VERSION "10.6"

NS_ :

BS_:

BU_: OBD XGW_Diag

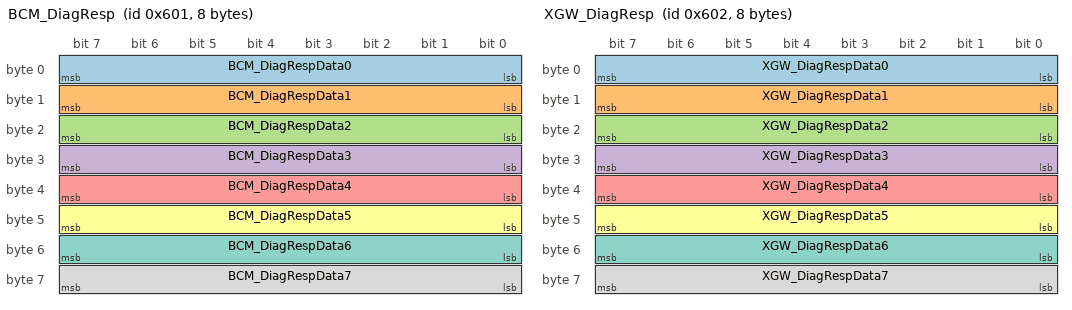
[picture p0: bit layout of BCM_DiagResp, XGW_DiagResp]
BO_ 1537 BCM_DiagResp: 8 XGW_Diag
  SG_ BCM_DiagRespData0 : 7|8@0+ (1,0) [0|255] "" OBD
  SG_ BCM_DiagRespData1 : 15|8@0+ (1,0) [0|255] "-" OBD
  SG_ BCM_DiagRespData2 : 23|8@0+ (1,0) [0|255] "" OBD
  SG_ BCM_DiagRespData3 : 31|8@0+ (1,0) [0|255] "" OBD
  SG_ BCM_DiagRespData4 : 39|8@0+ (1,0) [0|255] "" OBD
  SG_ BCM_DiagRespData5 : 47|8@0+ (1,0) [0|255] "" OBD
  SG_ BCM_DiagRespData6 : 55|8@0+ (1,0) [0|255] "-" OBD
  SG_ BCM_DiagRespData7 : 63|8@0+ (1,0) [0|255] "" OBD

BO_ 1538 XGW_DiagResp: 8 XGW_Diag
  SG_ XGW_DiagRespData0 : 7|8@0+ (1,0) [0|255] "-" OBD
  SG_ XGW_DiagRespData1 : 15|8@0+ (1,0) [0|255] "-" OBD
  SG_ XGW_DiagRespData2 : 23|8@0+ (1,0) [0|255] "-" OBD
  SG_ XGW_DiagRespData3 : 31|8@0+ (1,0) [0|255] "" OBD
  SG_ XGW_DiagRespData4 : 39|8@0+ (1,0) [0|255] "" OBD
  SG_ XGW_DiagRespData5 : 47|8@0+ (1,0) [0|255] "-" OBD
  SG_ XGW_DiagRespData6 : 55|8@0+ (1,0) [0|255] "" OBD
  SG_ XGW_DiagRespData7 : 63|8@0+ (1,0) [0|255] "-" OBD

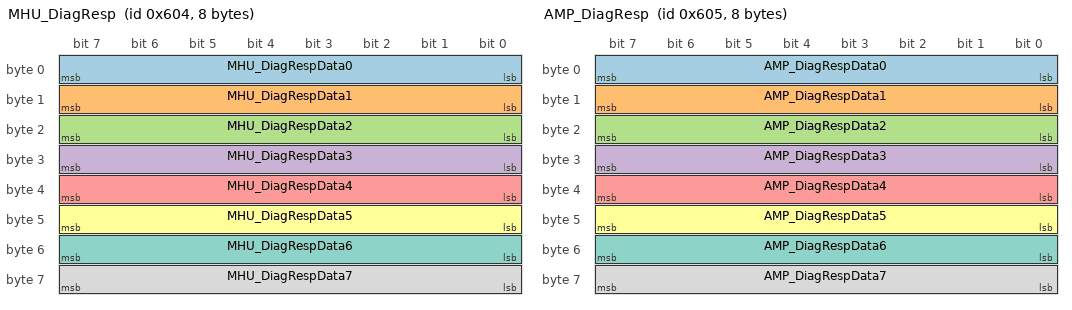
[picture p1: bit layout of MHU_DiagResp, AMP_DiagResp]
BO_ 1540 MHU_DiagResp: 8 XGW_Diag
  SG_ MHU_DiagRespData0 : 7|8@0+ (1,0) [0|255] "-" OBD
  SG_ MHU_DiagRespData1 : 15|8@0+ (1,0) [0|255] "-" OBD
  SG_ MHU_DiagRespData2 : 23|8@0+ (1,0) [0|255] "" OBD
  SG_ MHU_DiagRespData3 : 31|8@0+ (1,0) [0|255] "-" OBD
  SG_ MHU_DiagRespData4 : 39|8@0+ (1,0) [0|255] "-" OBD
  SG_ MHU_DiagRespData5 : 47|8@0+ (1,0) [0|255] "-" OBD
  SG_ MHU_DiagRespData6 : 55|8@0+ (1,0) [0|255] "-" OBD
  SG_ MHU_DiagRespData7 : 63|8@0+ (1,0) [0|255] "" OBD

BO_ 1541 AMP_DiagResp: 8 XGW_Diag
  SG_ AMP_DiagRespData0 : 7|8@0+ (1,0) [0|255] "-" OBD
  SG_ AMP_DiagRespData1 : 15|8@0+ (1,0) [0|255] "-" OBD
  SG_ AMP_DiagRespData2 : 23|8@0+ (1,0) [0|255] "-" OBD
  SG_ AMP_DiagRespData3 : 31|8@0+ (1,0) [0|255] "" OBD
  SG_ AMP_DiagRespData4 : 39|8@0+ (1,0) [0|255] "-" OBD
  SG_ AMP_DiagRespData5 : 47|8@0+ (1,0) [0|255] "" OBD
  SG_ AMP_DiagRespData6 : 55|8@0+ (1,0) [0|255] "" OBD
  SG_ AMP_DiagRespData7 : 63|8@0+ (1,0) [0|255] "-" OBD

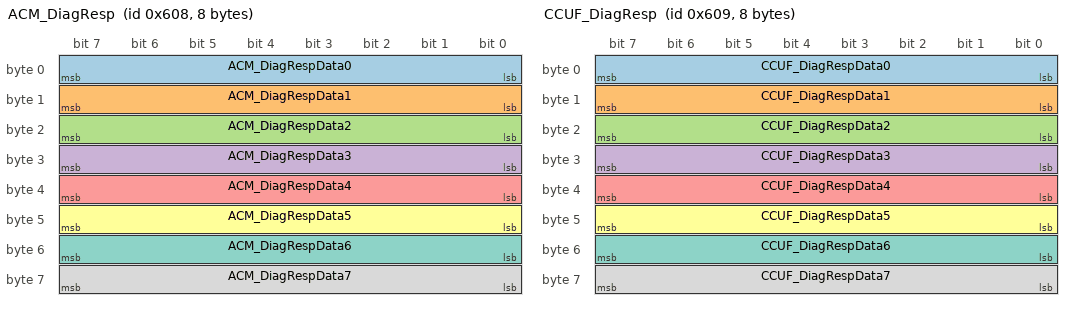
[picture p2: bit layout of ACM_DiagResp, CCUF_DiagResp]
BO_ 1544 ACM_DiagResp: 8 XGW_Diag
  SG_ ACM_DiagRespData0 : 7|8@0+ (1,0) [0|255] "" OBD
  SG_ ACM_DiagRespData1 : 15|8@0+ (1,0) [0|255] "-" OBD
  SG_ ACM_DiagRespData2 : 23|8@0+ (1,0) [0|255] "" OBD
  SG_ ACM_DiagRespData3 : 31|8@0+ (1,0) [0|255] "-" OBD
  SG_ ACM_DiagRespData4 : 39|8@0+ (1,0) [0|255] "" OBD
  SG_ ACM_DiagRespData5 : 47|8@0+ (1,0) [0|255] "-" OBD
  SG_ ACM_DiagRespData6 : 55|8@0+ (1,0) [0|255] "" OBD
  SG_ ACM_DiagRespData7 : 63|8@0+ (1,0) [0|255] "-" OBD

BO_ 1545 CCUF_DiagResp: 8 XGW_Diag
  SG_ CCUF_DiagRespData0 : 7|8@0+ (1,0) [0|255] "" OBD
  SG_ CCUF_DiagRespData1 : 15|8@0+ (1,0) [0|255] "-" OBD
  SG_ CCUF_DiagRespData2 : 23|8@0+ (1,0) [0|255] "-" OBD
  SG_ CCUF_DiagRespData3 : 31|8@0+ (1,0) [0|255] "" OBD
  SG_ CCUF_DiagRespData4 : 39|8@0+ (1,0) [0|255] "" OBD
  SG_ CCUF_DiagRespData5 : 47|8@0+ (1,0) [0|255] "-" OBD
  SG_ CCUF_DiagRespData6 : 55|8@0+ (1,0) [0|255] "-" OBD
  SG_ CCUF_DiagRespData7 : 63|8@0+ (1,0) [0|255] "" OBD

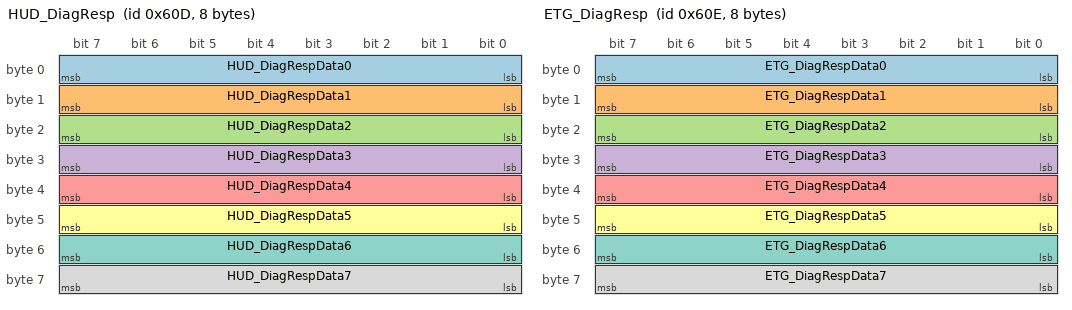
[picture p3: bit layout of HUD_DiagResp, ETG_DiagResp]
BO_ 1549 HUD_DiagResp: 8 XGW_Diag
  SG_ HUD_DiagRespData0 : 7|8@0+ (1,0) [0|255] "" OBD
  SG_ HUD_DiagRespData1 : 15|8@0+ (1,0) [0|255] "" OBD
  SG_ HUD_DiagRespData2 : 23|8@0+ (1,0) [0|255] "" OBD
  SG_ HUD_DiagRespData3 : 31|8@0+ (1,0) [0|255] "" OBD
  SG_ HUD_DiagRespData4 : 39|8@0+ (1,0) [0|255] "-" OBD
  SG_ HUD_DiagRespData5 : 47|8@0+ (1,0) [0|255] "" OBD
  SG_ HUD_DiagRespData6 : 55|8@0+ (1,0) [0|255] "-" OBD
  SG_ HUD_DiagRespData7 : 63|8@0+ (1,0) [0|255] "" OBD

BO_ 1550 ETG_DiagResp: 8 XGW_Diag
  SG_ ETG_DiagRespData0 : 7|8@0+ (1,0) [0|255] "" OBD
  SG_ ETG_DiagRespData1 : 15|8@0+ (1,0) [0|255] "" OBD
  SG_ ETG_DiagRespData2 : 23|8@0+ (1,0) [0|255] "" OBD
  SG_ ETG_DiagRespData3 : 31|8@0+ (1,0) [0|255] "-" OBD
  SG_ ETG_DiagRespData4 : 39|8@0+ (1,0) [0|255] "" OBD
  SG_ ETG_DiagRespData5 : 47|8@0+ (1,0) [0|255] "" OBD
  SG_ ETG_DiagRespData6 : 55|8@0+ (1,0) [0|255] "" OBD
  SG_ ETG_DiagRespData7 : 63|8@0+ (1,0) [0|255] "" OBD

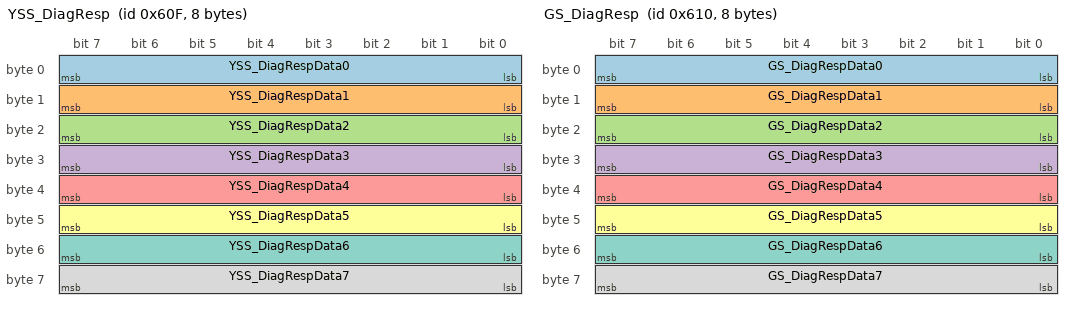
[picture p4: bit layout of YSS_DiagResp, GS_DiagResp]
BO_ 1551 YSS_DiagResp: 8 XGW_Diag
  SG_ YSS_DiagRespData0 : 7|8@0+ (1,0) [0|255] "" OBD
  SG_ YSS_DiagRespData1 : 15|8@0+ (1,0) [0|255] "" OBD
  SG_ YSS_DiagRespData2 : 23|8@0+ (1,0) [0|255] "-" OBD
  SG_ YSS_DiagRespData3 : 31|8@0+ (1,0) [0|255] "" OBD
  SG_ YSS_DiagRespData4 : 39|8@0+ (1,0) [0|255] "" OBD
  SG_ YSS_DiagRespData5 : 47|8@0+ (1,0) [0|255] "" OBD
  SG_ YSS_DiagRespData6 : 55|8@0+ (1,0) [0|255] "" OBD
  SG_ YSS_DiagRespData7 : 63|8@0+ (1,0) [0|255] "" OBD

BO_ 1552 GS_DiagResp: 8 XGW_Diag
  SG_ GS_DiagRespData0 : 7|8@0+ (1,0) [0|255] "-" OBD
  SG_ GS_DiagRespData1 : 15|8@0+ (1,0) [0|255] "" OBD
  SG_ GS_DiagRespData2 : 23|8@0+ (1,0) [0|255] "-" OBD
  SG_ GS_DiagRespData3 : 31|8@0+ (1,0) [0|255] "" OBD
  SG_ GS_DiagRespData4 : 39|8@0+ (1,0) [0|255] "" OBD
  SG_ GS_DiagRespData5 : 47|8@0+ (1,0) [0|255] "" OBD
  SG_ GS_DiagRespData6 : 55|8@0+ (1,0) [0|255] "-" OBD
  SG_ GS_DiagRespData7 : 63|8@0+ (1,0) [0|255] "" OBD

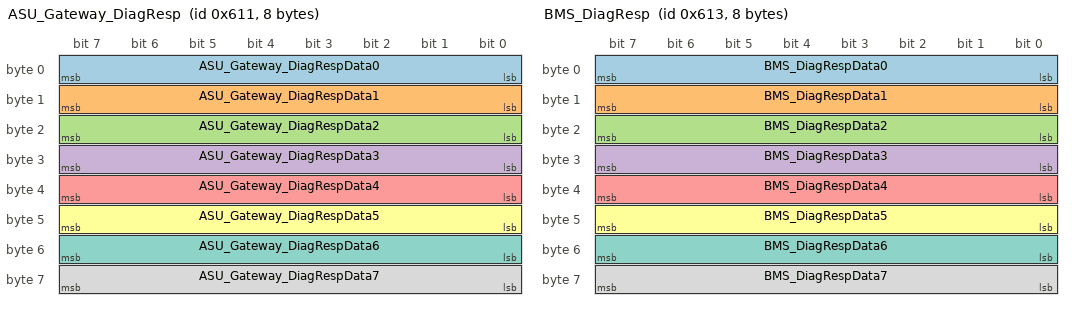
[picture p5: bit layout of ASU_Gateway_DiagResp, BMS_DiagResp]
BO_ 1553 ASU_Gateway_DiagResp: 8 XGW_Diag
  SG_ ASU_Gateway_DiagRespData0 : 7|8@0+ (1,0) [0|255] "-" OBD
  SG_ ASU_Gateway_DiagRespData1 : 15|8@0+ (1,0) [0|255] "-" OBD
  SG_ ASU_Gateway_DiagRespData2 : 23|8@0+ (1,0) [0|255] "-" OBD
  SG_ ASU_Gateway_DiagRespData3 : 31|8@0+ (1,0) [0|255] "-" OBD
  SG_ ASU_Gateway_DiagRespData4 : 39|8@0+ (1,0) [0|255] "-" OBD
  SG_ ASU_Gateway_DiagRespData5 : 47|8@0+ (1,0) [0|255] "-" OBD
  SG_ ASU_Gateway_DiagRespData6 : 55|8@0+ (1,0) [0|255] "-" OBD
  SG_ ASU_Gateway_DiagRespData7 : 63|8@0+ (1,0) [0|255] "-" OBD

BO_ 1555 BMS_DiagResp: 8 XGW_Diag
  SG_ BMS_DiagRespData0 : 7|8@0+ (1,0) [0|255] "" OBD
  SG_ BMS_DiagRespData1 : 15|8@0+ (1,0) [0|255] "" OBD
  SG_ BMS_DiagRespData2 : 23|8@0+ (1,0) [0|255] "" OBD
  SG_ BMS_DiagRespData3 : 31|8@0+ (1,0) [0|255] "" OBD
  SG_ BMS_DiagRespData4 : 39|8@0+ (1,0) [0|255] "" OBD
  SG_ BMS_DiagRespData5 : 47|8@0+ (1,0) [0|255] "" OBD
  SG_ BMS_DiagRespData6 : 55|8@0+ (1,0) [0|255] "" OBD
  SG_ BMS_DiagRespData7 : 63|8@0+ (1,0) [0|255] "-" OBD

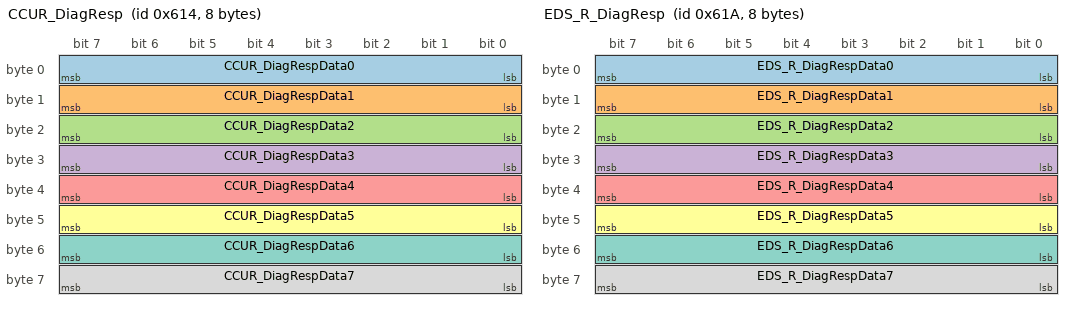
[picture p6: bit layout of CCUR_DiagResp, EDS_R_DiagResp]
BO_ 1556 CCUR_DiagResp: 8 XGW_Diag
  SG_ CCUR_DiagRespData0 : 7|8@0+ (1,0) [0|255] "" OBD
  SG_ CCUR_DiagRespData1 : 15|8@0+ (1,0) [0|255] "" OBD
  SG_ CCUR_DiagRespData2 : 23|8@0+ (1,0) [0|255] "" OBD
  SG_ CCUR_DiagRespData3 : 31|8@0+ (1,0) [0|255] "" OBD
  SG_ CCUR_DiagRespData4 : 39|8@0+ (1,0) [0|255] "-" OBD
  SG_ CCUR_DiagRespData5 : 47|8@0+ (1,0) [0|255] "" OBD
  SG_ CCUR_DiagRespData6 : 55|8@0+ (1,0) [0|255] "-" OBD
  SG_ CCUR_DiagRespData7 : 63|8@0+ (1,0) [0|255] "" OBD

BO_ 1562 EDS_R_DiagResp: 8 XGW_Diag
  SG_ EDS_R_DiagRespData0 : 7|8@0+ (1,0) [0|255] "" OBD
  SG_ EDS_R_DiagRespData1 : 15|8@0+ (1,0) [0|255] "" OBD
  SG_ EDS_R_DiagRespData2 : 23|8@0+ (1,0) [0|255] "-" OBD
  SG_ EDS_R_DiagRespData3 : 31|8@0+ (1,0) [0|255] "" OBD
  SG_ EDS_R_DiagRespData4 : 39|8@0+ (1,0) [0|255] "" OBD
  SG_ EDS_R_DiagRespData5 : 47|8@0+ (1,0) [0|255] "-" OBD
  SG_ EDS_R_DiagRespData6 : 55|8@0+ (1,0) [0|255] "-" OBD
  SG_ EDS_R_DiagRespData7 : 63|8@0+ (1,0) [0|255] "-" OBD

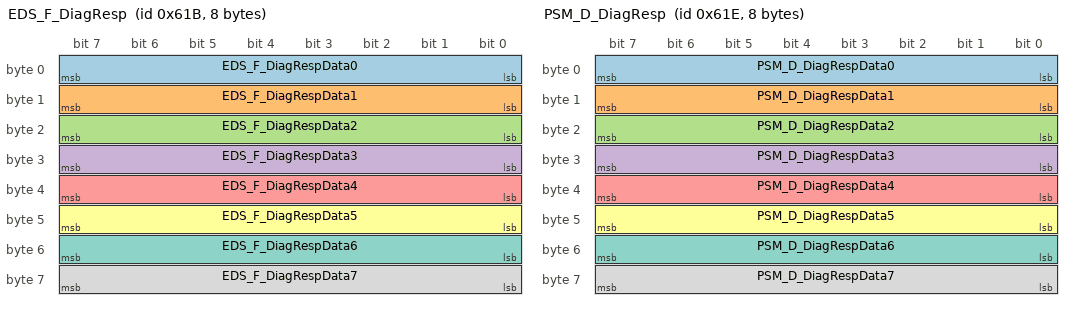
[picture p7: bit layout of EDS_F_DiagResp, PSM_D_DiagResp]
BO_ 1563 EDS_F_DiagResp: 8 XGW_Diag
  SG_ EDS_F_DiagRespData0 : 7|8@0+ (1,0) [0|255] "" OBD
  SG_ EDS_F_DiagRespData1 : 15|8@0+ (1,0) [0|255] "" OBD
  SG_ EDS_F_DiagRespData2 : 23|8@0+ (1,0) [0|255] "-" OBD
  SG_ EDS_F_DiagRespData3 : 31|8@0+ (1,0) [0|255] "" OBD
  SG_ EDS_F_DiagRespData4 : 39|8@0+ (1,0) [0|255] "" OBD
  SG_ EDS_F_DiagRespData5 : 47|8@0+ (1,0) [0|255] "" OBD
  SG_ EDS_F_DiagRespData6 : 55|8@0+ (1,0) [0|255] "-" OBD
  SG_ EDS_F_DiagRespData7 : 63|8@0+ (1,0) [0|255] "" OBD

BO_ 1566 PSM_D_DiagResp: 8 XGW_Diag
  SG_ PSM_D_DiagRespData0 : 7|8@0+ (1,0) [0|255] "" OBD
  SG_ PSM_D_DiagRespData1 : 15|8@0+ (1,0) [0|255] "" OBD
  SG_ PSM_D_DiagRespData2 : 23|8@0+ (1,0) [0|255] "" OBD
  SG_ PSM_D_DiagRespData3 : 31|8@0+ (1,0) [0|255] "-" OBD
  SG_ PSM_D_DiagRespData4 : 39|8@0+ (1,0) [0|255] "" OBD
  SG_ PSM_D_DiagRespData5 : 47|8@0+ (1,0) [0|255] "" OBD
  SG_ PSM_D_DiagRespData6 : 55|8@0+ (1,0) [0|255] "" OBD
  SG_ PSM_D_DiagRespData7 : 63|8@0+ (1,0) [0|255] "" OBD

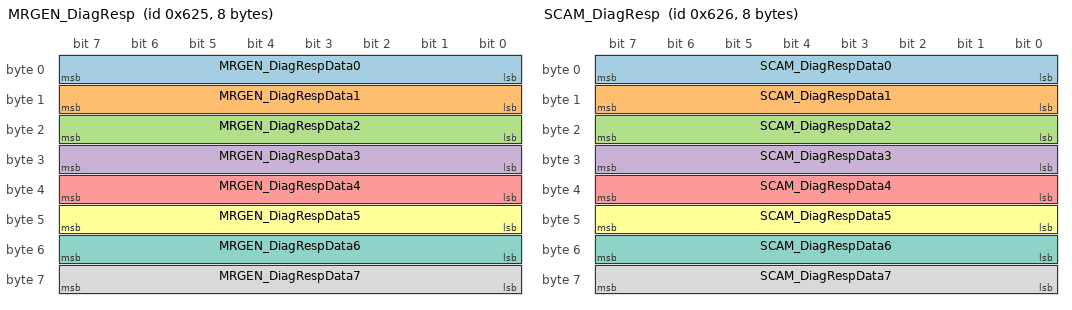
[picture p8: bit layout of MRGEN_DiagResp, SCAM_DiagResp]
BO_ 1573 MRGEN_DiagResp: 8 XGW_Diag
  SG_ MRGEN_DiagRespData0 : 7|8@0+ (1,0) [0|255] "" OBD
  SG_ MRGEN_DiagRespData1 : 15|8@0+ (1,0) [0|255] "-" OBD
  SG_ MRGEN_DiagRespData2 : 23|8@0+ (1,0) [0|255] "" OBD
  SG_ MRGEN_DiagRespData3 : 31|8@0+ (1,0) [0|255] "" OBD
  SG_ MRGEN_DiagRespData4 : 39|8@0+ (1,0) [0|255] "" OBD
  SG_ MRGEN_DiagRespData5 : 47|8@0+ (1,0) [0|255] "" OBD
  SG_ MRGEN_DiagRespData6 : 55|8@0+ (1,0) [0|255] "" OBD
  SG_ MRGEN_DiagRespData7 : 63|8@0+ (1,0) [0|255] "-" OBD

BO_ 1574 SCAM_DiagResp: 8 XGW_Diag
  SG_ SCAM_DiagRespData0 : 7|8@0+ (1,0) [0|255] "" OBD
  SG_ SCAM_DiagRespData1 : 15|8@0+ (1,0) [0|255] "" OBD
  SG_ SCAM_DiagRespData2 : 23|8@0+ (1,0) [0|255] "" OBD
  SG_ SCAM_DiagRespData3 : 31|8@0+ (1,0) [0|255] "" OBD
  SG_ SCAM_DiagRespData4 : 39|8@0+ (1,0) [0|255] "" OBD
  SG_ SCAM_DiagRespData5 : 47|8@0+ (1,0) [0|255] "-" OBD
  SG_ SCAM_DiagRespData6 : 55|8@0+ (1,0) [0|255] "" OBD
  SG_ SCAM_DiagRespData7 : 63|8@0+ (1,0) [0|255] "" OBD

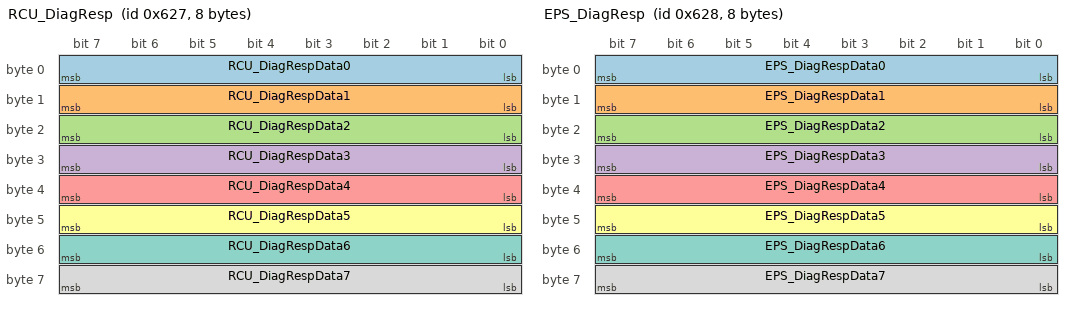
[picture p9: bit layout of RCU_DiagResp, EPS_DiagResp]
BO_ 1575 RCU_DiagResp: 8 XGW_Diag
  SG_ RCU_DiagRespData0 : 7|8@0+ (1,0) [0|255] "" OBD
  SG_ RCU_DiagRespData1 : 15|8@0+ (1,0) [0|255] "" OBD
  SG_ RCU_DiagRespData2 : 23|8@0+ (1,0) [0|255] "" OBD
  SG_ RCU_DiagRespData3 : 31|8@0+ (1,0) [0|255] "" OBD
  SG_ RCU_DiagRespData4 : 39|8@0+ (1,0) [0|255] "" OBD
  SG_ RCU_DiagRespData5 : 47|8@0+ (1,0) [0|255] "" OBD
  SG_ RCU_DiagRespData6 : 55|8@0+ (1,0) [0|255] "" OBD
  SG_ RCU_DiagRespData7 : 63|8@0+ (1,0) [0|255] "" OBD

BO_ 1576 EPS_DiagResp: 8 XGW_Diag
  SG_ EPS_DiagRespData0 : 7|8@0+ (1,0) [0|255] "-" OBD
  SG_ EPS_DiagRespData1 : 15|8@0+ (1,0) [0|255] "" OBD
  SG_ EPS_DiagRespData2 : 23|8@0+ (1,0) [0|255] "" OBD
  SG_ EPS_DiagRespData3 : 31|8@0+ (1,0) [0|255] "-" OBD
  SG_ EPS_DiagRespData4 : 39|8@0+ (1,0) [0|255] "" OBD
  SG_ EPS_DiagRespData5 : 47|8@0+ (1,0) [0|255] "" OBD
  SG_ EPS_DiagRespData6 : 55|8@0+ (1,0) [0|255] "-" OBD
  SG_ EPS_DiagRespData7 : 63|8@0+ (1,0) [0|255] "-" OBD

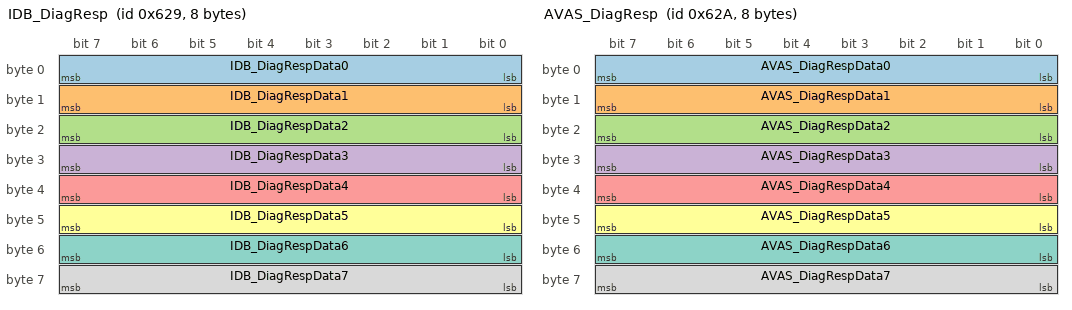
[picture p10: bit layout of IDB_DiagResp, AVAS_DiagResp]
BO_ 1577 IDB_DiagResp: 8 XGW_Diag
  SG_ IDB_DiagRespData0 : 7|8@0+ (1,0) [0|255] "" OBD
  SG_ IDB_DiagRespData1 : 15|8@0+ (1,0) [0|255] "-" OBD
  SG_ IDB_DiagRespData2 : 23|8@0+ (1,0) [0|255] "-" OBD
  SG_ IDB_DiagRespData3 : 31|8@0+ (1,0) [0|255] "" OBD
  SG_ IDB_DiagRespData4 : 39|8@0+ (1,0) [0|255] "" OBD
  SG_ IDB_DiagRespData5 : 47|8@0+ (1,0) [0|255] "-" OBD
  SG_ IDB_DiagRespData6 : 55|8@0+ (1,0) [0|255] "-" OBD
  SG_ IDB_DiagRespData7 : 63|8@0+ (1,0) [0|255] "" OBD

BO_ 1578 AVAS_DiagResp: 8 XGW_Diag
  SG_ AVAS_DiagRespData0 : 7|8@0+ (1,0) [0|255] "" OBD
  SG_ AVAS_DiagRespData1 : 15|8@0+ (1,0) [0|255] "" OBD
  SG_ AVAS_DiagRespData2 : 23|8@0+ (1,0) [0|255] "" OBD
  SG_ AVAS_DiagRespData3 : 31|8@0+ (1,0) [0|255] "" OBD
  SG_ AVAS_DiagRespData4 : 39|8@0+ (1,0) [0|255] "" OBD
  SG_ AVAS_DiagRespData5 : 47|8@0+ (1,0) [0|255] "" OBD
  SG_ AVAS_DiagRespData6 : 55|8@0+ (1,0) [0|255] "" OBD
  SG_ AVAS_DiagRespData7 : 63|8@0+ (1,0) [0|255] "-" OBD

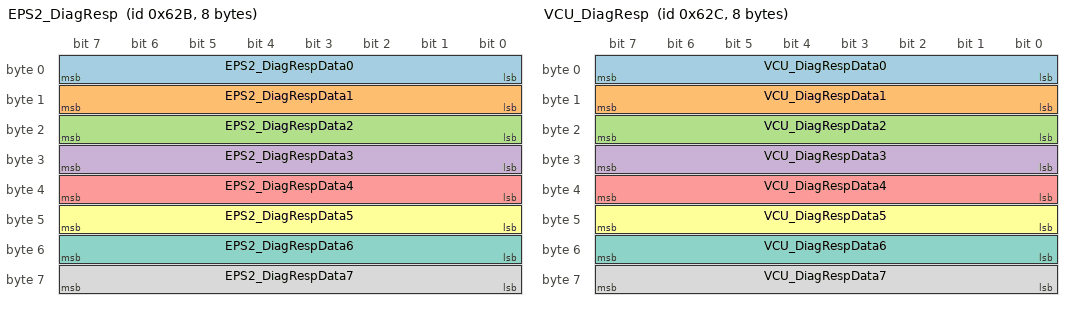
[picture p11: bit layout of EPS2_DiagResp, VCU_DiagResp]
BO_ 1579 EPS2_DiagResp: 8 XGW_Diag
  SG_ EPS2_DiagRespData0 : 7|8@0+ (1,0) [0|255] "" OBD
  SG_ EPS2_DiagRespData1 : 15|8@0+ (1,0) [0|255] "-" OBD
  SG_ EPS2_DiagRespData2 : 23|8@0+ (1,0) [0|255] "-" OBD
  SG_ EPS2_DiagRespData3 : 31|8@0+ (1,0) [0|255] "" OBD
  SG_ EPS2_DiagRespData4 : 39|8@0+ (1,0) [0|255] "-" OBD
  SG_ EPS2_DiagRespData5 : 47|8@0+ (1,0) [0|255] "" OBD
  SG_ EPS2_DiagRespData6 : 55|8@0+ (1,0) [0|255] "-" OBD
  SG_ EPS2_DiagRespData7 : 63|8@0+ (1,0) [0|255] "-" OBD

BO_ 1580 VCU_DiagResp: 8 XGW_Diag
  SG_ VCU_DiagRespData0 : 7|8@0+ (1,0) [0|255] "" OBD
  SG_ VCU_DiagRespData1 : 15|8@0+ (1,0) [0|255] "" OBD
  SG_ VCU_DiagRespData2 : 23|8@0+ (1,0) [0|255] "" OBD
  SG_ VCU_DiagRespData3 : 31|8@0+ (1,0) [0|255] "" OBD
  SG_ VCU_DiagRespData4 : 39|8@0+ (1,0) [0|255] "-" OBD
  SG_ VCU_DiagRespData5 : 47|8@0+ (1,0) [0|255] "" OBD
  SG_ VCU_DiagRespData6 : 55|8@0+ (1,0) [0|255] "" OBD
  SG_ VCU_DiagRespData7 : 63|8@0+ (1,0) [0|255] "-" OBD

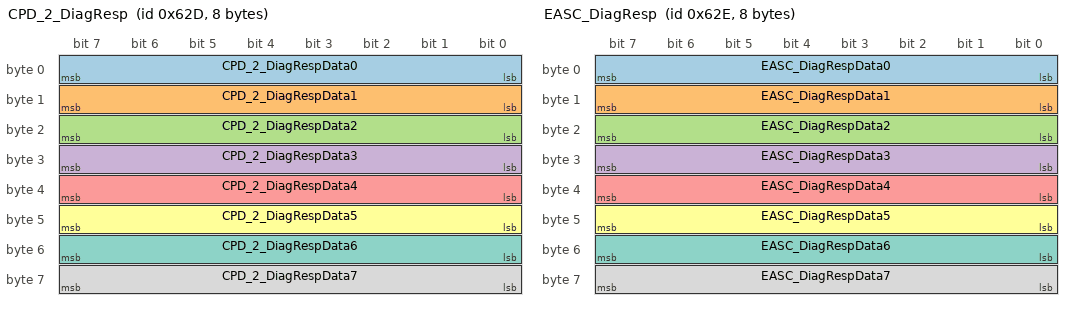
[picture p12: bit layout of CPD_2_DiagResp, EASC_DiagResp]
BO_ 1581 CPD_2_DiagResp: 8 XGW_Diag
  SG_ CPD_2_DiagRespData0 : 7|8@0+ (1,0) [0|0] "" OBD
  SG_ CPD_2_DiagRespData1 : 15|8@0+ (1,0) [0|0] "" OBD
  SG_ CPD_2_DiagRespData2 : 23|8@0+ (1,0) [0|0] "" OBD
  SG_ CPD_2_DiagRespData3 : 31|8@0+ (1,0) [0|0] "" OBD
  SG_ CPD_2_DiagRespData4 : 39|8@0+ (1,0) [0|0] "" OBD
  SG_ CPD_2_DiagRespData5 : 47|8@0+ (1,0) [0|0] "" OBD
  SG_ CPD_2_DiagRespData6 : 55|8@0+ (1,0) [0|0] "" OBD
  SG_ CPD_2_DiagRespData7 : 63|8@0+ (1,0) [0|0] "" OBD

BO_ 1582 EASC_DiagResp: 8 XGW_Diag
  SG_ EASC_DiagRespData0 : 7|8@0+ (1,0) [0|255] "-" OBD
  SG_ EASC_DiagRespData1 : 15|8@0+ (1,0) [0|255] "-" OBD
  SG_ EASC_DiagRespData2 : 23|8@0+ (1,0) [0|255] "-" OBD
  SG_ EASC_DiagRespData3 : 31|8@0+ (1,0) [0|255] "" OBD
  SG_ EASC_DiagRespData4 : 39|8@0+ (1,0) [0|255] "" OBD
  SG_ EASC_DiagRespData5 : 47|8@0+ (1,0) [0|255] "" OBD
  SG_ EASC_DiagRespData6 : 55|8@0+ (1,0) [0|255] "" OBD
  SG_ EASC_DiagRespData7 : 63|8@0+ (1,0) [0|255] "" OBD

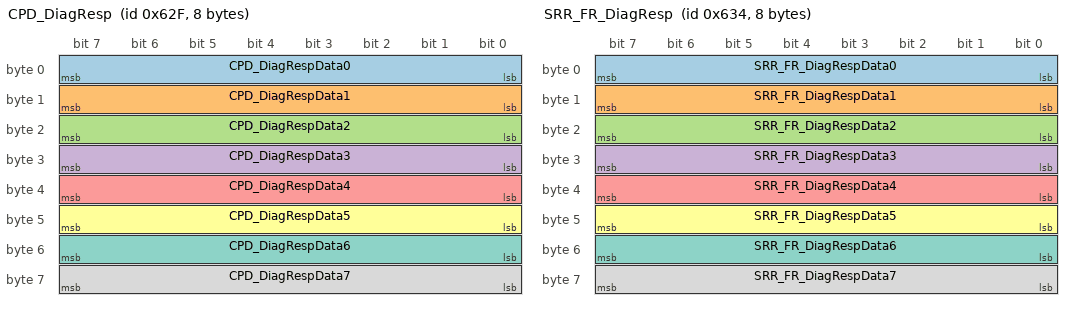
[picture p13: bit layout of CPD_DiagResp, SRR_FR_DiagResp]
BO_ 1583 CPD_DiagResp: 8 XGW_Diag
  SG_ CPD_DiagRespData0 : 7|8@0+ (1,0) [0|255] "-" OBD
  SG_ CPD_DiagRespData1 : 15|8@0+ (1,0) [0|255] "-" OBD
  SG_ CPD_DiagRespData2 : 23|8@0+ (1,0) [0|255] "" OBD
  SG_ CPD_DiagRespData3 : 31|8@0+ (1,0) [0|255] "-" OBD
  SG_ CPD_DiagRespData4 : 39|8@0+ (1,0) [0|255] "-" OBD
  SG_ CPD_DiagRespData5 : 47|8@0+ (1,0) [0|255] "" OBD
  SG_ CPD_DiagRespData6 : 55|8@0+ (1,0) [0|255] "-" OBD
  SG_ CPD_DiagRespData7 : 63|8@0+ (1,0) [0|255] "" OBD

BO_ 1588 SRR_FR_DiagResp: 8 XGW_Diag
  SG_ SRR_FR_DiagRespData0 : 7|8@0+ (1,0) [0|255] "-" OBD
  SG_ SRR_FR_DiagRespData1 : 15|8@0+ (1,0) [0|255] "-" OBD
  SG_ SRR_FR_DiagRespData2 : 23|8@0+ (1,0) [0|255] "-" OBD
  SG_ SRR_FR_DiagRespData3 : 31|8@0+ (1,0) [0|255] "" OBD
  SG_ SRR_FR_DiagRespData4 : 39|8@0+ (1,0) [0|255] "" OBD
  SG_ SRR_FR_DiagRespData5 : 47|8@0+ (1,0) [0|255] "" OBD
  SG_ SRR_FR_DiagRespData6 : 55|8@0+ (1,0) [0|255] "" OBD
  SG_ SRR_FR_DiagRespData7 : 63|8@0+ (1,0) [0|255] "" OBD

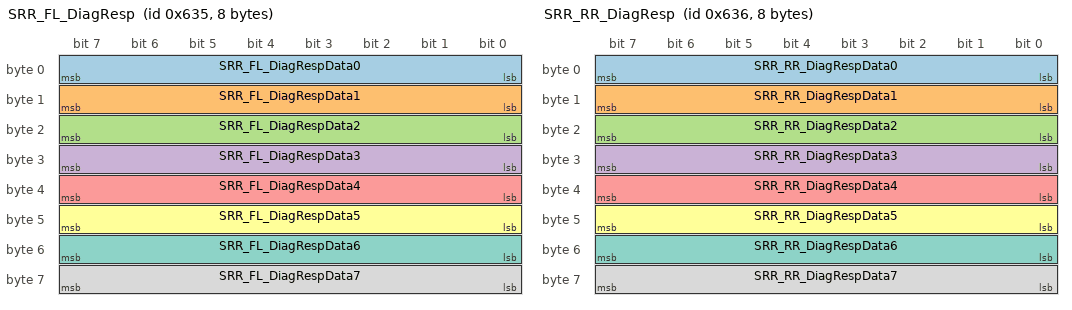
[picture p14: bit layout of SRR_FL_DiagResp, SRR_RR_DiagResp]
BO_ 1589 SRR_FL_DiagResp: 8 XGW_Diag
  SG_ SRR_FL_DiagRespData0 : 7|8@0+ (1,0) [0|255] "" OBD
  SG_ SRR_FL_DiagRespData1 : 15|8@0+ (1,0) [0|255] "-" OBD
  SG_ SRR_FL_DiagRespData2 : 23|8@0+ (1,0) [0|255] "" OBD
  SG_ SRR_FL_DiagRespData3 : 31|8@0+ (1,0) [0|255] "-" OBD
  SG_ SRR_FL_DiagRespData4 : 39|8@0+ (1,0) [0|255] "" OBD
  SG_ SRR_FL_DiagRespData5 : 47|8@0+ (1,0) [0|255] "-" OBD
  SG_ SRR_FL_DiagRespData6 : 55|8@0+ (1,0) [0|255] "-" OBD
  SG_ SRR_FL_DiagRespData7 : 63|8@0+ (1,0) [0|255] "" OBD

BO_ 1590 SRR_RR_DiagResp: 8 XGW_Diag
  SG_ SRR_RR_DiagRespData0 : 7|8@0+ (1,0) [0|255] "" OBD
  SG_ SRR_RR_DiagRespData1 : 15|8@0+ (1,0) [0|255] "-" OBD
  SG_ SRR_RR_DiagRespData2 : 23|8@0+ (1,0) [0|255] "-" OBD
  SG_ SRR_RR_DiagRespData3 : 31|8@0+ (1,0) [0|255] "" OBD
  SG_ SRR_RR_DiagRespData4 : 39|8@0+ (1,0) [0|255] "-" OBD
  SG_ SRR_RR_DiagRespData5 : 47|8@0+ (1,0) [0|255] "-" OBD
  SG_ SRR_RR_DiagRespData6 : 55|8@0+ (1,0) [0|255] "-" OBD
  SG_ SRR_RR_DiagRespData7 : 63|8@0+ (1,0) [0|255] "-" OBD

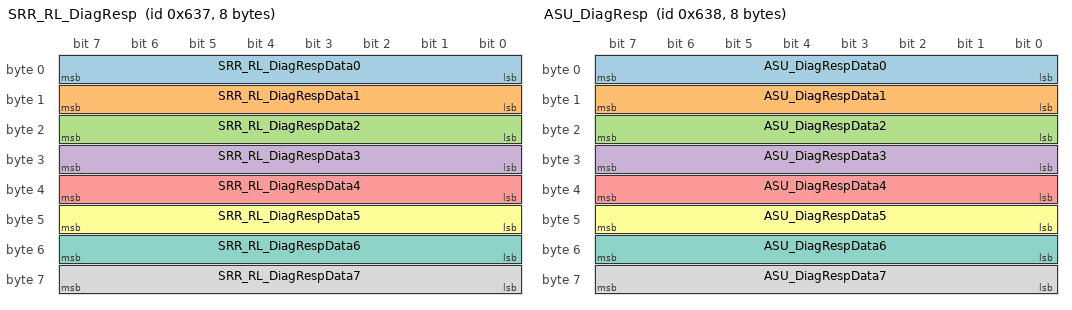
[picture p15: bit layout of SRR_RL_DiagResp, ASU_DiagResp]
BO_ 1591 SRR_RL_DiagResp: 8 XGW_Diag
  SG_ SRR_RL_DiagRespData0 : 7|8@0+ (1,0) [0|255] "" OBD
  SG_ SRR_RL_DiagRespData1 : 15|8@0+ (1,0) [0|255] "-" OBD
  SG_ SRR_RL_DiagRespData2 : 23|8@0+ (1,0) [0|255] "-" OBD
  SG_ SRR_RL_DiagRespData3 : 31|8@0+ (1,0) [0|255] "-" OBD
  SG_ SRR_RL_DiagRespData4 : 39|8@0+ (1,0) [0|255] "" OBD
  SG_ SRR_RL_DiagRespData5 : 47|8@0+ (1,0) [0|255] "-" OBD
  SG_ SRR_RL_DiagRespData6 : 55|8@0+ (1,0) [0|255] "-" OBD
  SG_ SRR_RL_DiagRespData7 : 63|8@0+ (1,0) [0|255] "-" OBD

BO_ 1592 ASU_DiagResp: 8 XGW_Diag
  SG_ ASU_DiagRespData0 : 7|8@0+ (1,0) [0|255] "-" OBD
  SG_ ASU_DiagRespData1 : 15|8@0+ (1,0) [0|255] "-" OBD
  SG_ ASU_DiagRespData2 : 23|8@0+ (1,0) [0|255] "-" OBD
  SG_ ASU_DiagRespData3 : 31|8@0+ (1,0) [0|255] "-" OBD
  SG_ ASU_DiagRespData4 : 39|8@0+ (1,0) [0|255] "-" OBD
  SG_ ASU_DiagRespData5 : 47|8@0+ (1,0) [0|255] "-" OBD
  SG_ ASU_DiagRespData6 : 55|8@0+ (1,0) [0|255] "-" OBD
  SG_ ASU_DiagRespData7 : 63|8@0+ (1,0) [0|255] "-" OBD

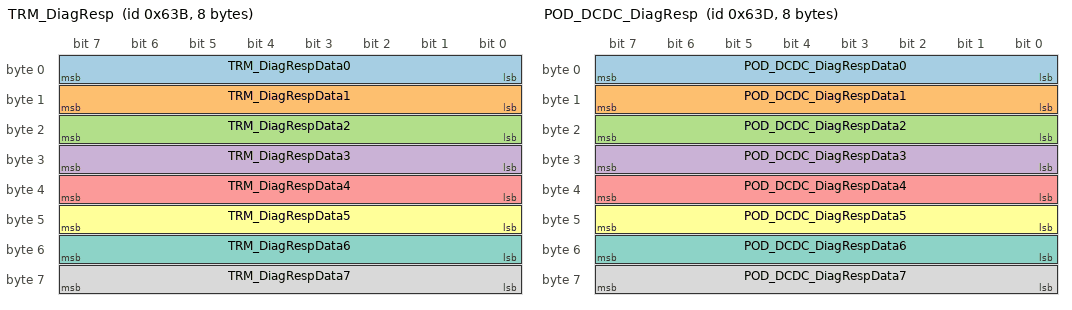
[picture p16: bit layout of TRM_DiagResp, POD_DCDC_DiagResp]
BO_ 1595 TRM_DiagResp: 8 XGW_Diag
  SG_ TRM_DiagRespData0 : 7|8@0+ (1,0) [0|255] "" OBD
  SG_ TRM_DiagRespData1 : 15|8@0+ (1,0) [0|255] "" OBD
  SG_ TRM_DiagRespData2 : 23|8@0+ (1,0) [0|255] "" OBD
  SG_ TRM_DiagRespData3 : 31|8@0+ (1,0) [0|255] "-" OBD
  SG_ TRM_DiagRespData4 : 39|8@0+ (1,0) [0|255] "-" OBD
  SG_ TRM_DiagRespData5 : 47|8@0+ (1,0) [0|255] "-" OBD
  SG_ TRM_DiagRespData6 : 55|8@0+ (1,0) [0|255] "" OBD
  SG_ TRM_DiagRespData7 : 63|8@0+ (1,0) [0|255] "-" OBD

BO_ 1597 POD_DCDC_DiagResp: 8 XGW_Diag
  SG_ POD_DCDC_DiagRespData0 : 7|8@0+ (1,0) [0|255] "" OBD
  SG_ POD_DCDC_DiagRespData1 : 15|8@0+ (1,0) [0|255] "" OBD
  SG_ POD_DCDC_DiagRespData2 : 23|8@0+ (1,0) [0|255] "-" OBD
  SG_ POD_DCDC_DiagRespData3 : 31|8@0+ (1,0) [0|255] "-" OBD
  SG_ POD_DCDC_DiagRespData4 : 39|8@0+ (1,0) [0|255] "" OBD
  SG_ POD_DCDC_DiagRespData5 : 47|8@0+ (1,0) [0|255] "" OBD
  SG_ POD_DCDC_DiagRespData6 : 55|8@0+ (1,0) [0|255] "-" OBD
  SG_ POD_DCDC_DiagRespData7 : 63|8@0+ (1,0) [0|255] "" OBD

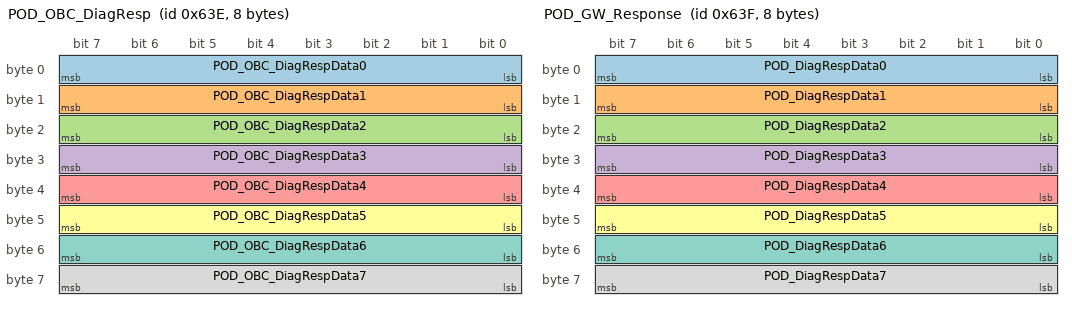
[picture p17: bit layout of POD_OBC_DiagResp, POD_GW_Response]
BO_ 1598 POD_OBC_DiagResp: 8 XGW_Diag
  SG_ POD_OBC_DiagRespData0 : 7|8@0+ (1,0) [0|255] "" OBD
  SG_ POD_OBC_DiagRespData1 : 15|8@0+ (1,0) [0|255] "-" OBD
  SG_ POD_OBC_DiagRespData2 : 23|8@0+ (1,0) [0|255] "" OBD
  SG_ POD_OBC_DiagRespData3 : 31|8@0+ (1,0) [0|255] "-" OBD
  SG_ POD_OBC_DiagRespData4 : 39|8@0+ (1,0) [0|255] "" OBD
  SG_ POD_OBC_DiagRespData5 : 47|8@0+ (1,0) [0|255] "-" OBD
  SG_ POD_OBC_DiagRespData6 : 55|8@0+ (1,0) [0|255] "" OBD
  SG_ POD_OBC_DiagRespData7 : 63|8@0+ (1,0) [0|255] "-" OBD

BO_ 1599 POD_GW_Response: 8 XGW_Diag
  SG_ POD_DiagRespData0 : 7|8@0+ (1,0) [0|255] "-" OBD
  SG_ POD_DiagRespData1 : 15|8@0+ (1,0) [0|255] "" OBD
  SG_ POD_DiagRespData2 : 23|8@0+ (1,0) [0|255] "" OBD
  SG_ POD_DiagRespData3 : 31|8@0+ (1,0) [0|255] "-" OBD
  SG_ POD_DiagRespData4 : 39|8@0+ (1,0) [0|255] "-" OBD
  SG_ POD_DiagRespData5 : 47|8@0+ (1,0) [0|255] "-" OBD
  SG_ POD_DiagRespData6 : 55|8@0+ (1,0) [0|255] "" OBD
  SG_ POD_DiagRespData7 : 63|8@0+ (1,0) [0|255] "" OBD

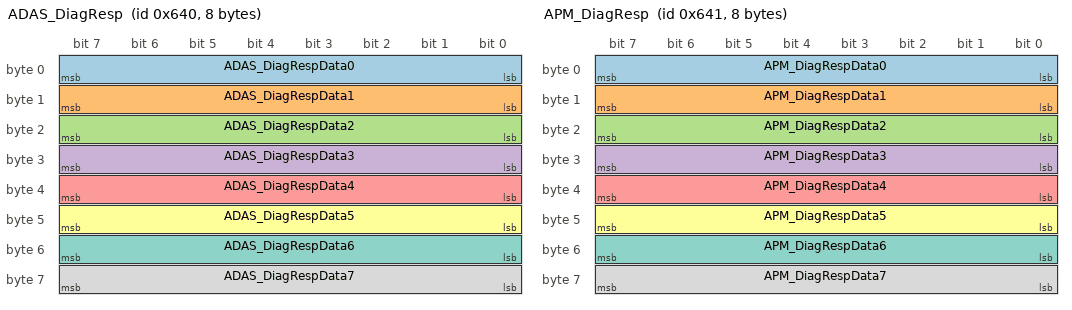
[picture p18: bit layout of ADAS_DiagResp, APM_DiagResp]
BO_ 1600 ADAS_DiagResp: 8 XGW_Diag
  SG_ ADAS_DiagRespData0 : 7|8@0+ (1,0) [0|255] "" OBD
  SG_ ADAS_DiagRespData1 : 15|8@0+ (1,0) [0|255] "" OBD
  SG_ ADAS_DiagRespData2 : 23|8@0+ (1,0) [0|255] "" OBD
  SG_ ADAS_DiagRespData3 : 31|8@0+ (1,0) [0|255] "" OBD
  SG_ ADAS_DiagRespData4 : 39|8@0+ (1,0) [0|255] "" OBD
  SG_ ADAS_DiagRespData5 : 47|8@0+ (1,0) [0|255] "" OBD
  SG_ ADAS_DiagRespData6 : 55|8@0+ (1,0) [0|255] "" OBD
  SG_ ADAS_DiagRespData7 : 63|8@0+ (1,0) [0|255] "" OBD

BO_ 1601 APM_DiagResp: 8 XGW_Diag
  SG_ APM_DiagRespData0 : 7|8@0+ (1,0) [0|255] "" OBD
  SG_ APM_DiagRespData1 : 15|8@0+ (1,0) [0|255] "" OBD
  SG_ APM_DiagRespData2 : 23|8@0+ (1,0) [0|255] "" OBD
  SG_ APM_DiagRespData3 : 31|8@0+ (1,0) [0|255] "" OBD
  SG_ APM_DiagRespData4 : 39|8@0+ (1,0) [0|255] "-" OBD
  SG_ APM_DiagRespData5 : 47|8@0+ (1,0) [0|255] "" OBD
  SG_ APM_DiagRespData6 : 55|8@0+ (1,0) [0|255] "-" OBD
  SG_ APM_DiagRespData7 : 63|8@0+ (1,0) [0|255] "" OBD

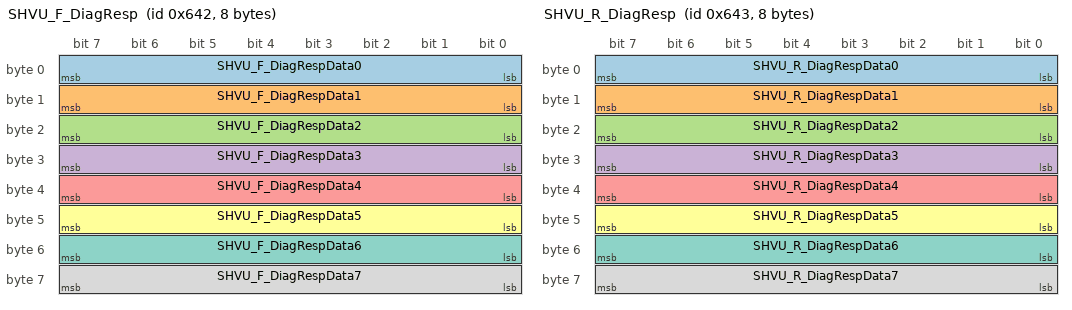
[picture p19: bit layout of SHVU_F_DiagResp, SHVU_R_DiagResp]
BO_ 1602 SHVU_F_DiagResp: 8 XGW_Diag
  SG_ SHVU_F_DiagRespData0 : 7|8@0+ (1,0) [0|255] "" OBD
  SG_ SHVU_F_DiagRespData1 : 15|8@0+ (1,0) [0|255] "" OBD
  SG_ SHVU_F_DiagRespData2 : 23|8@0+ (1,0) [0|255] "-" OBD
  SG_ SHVU_F_DiagRespData3 : 31|8@0+ (1,0) [0|255] "" OBD
  SG_ SHVU_F_DiagRespData4 : 39|8@0+ (1,0) [0|255] "" OBD
  SG_ SHVU_F_DiagRespData5 : 47|8@0+ (1,0) [0|255] "" OBD
  SG_ SHVU_F_DiagRespData6 : 55|8@0+ (1,0) [0|255] "-" OBD
  SG_ SHVU_F_DiagRespData7 : 63|8@0+ (1,0) [0|255] "" OBD

BO_ 1603 SHVU_R_DiagResp: 8 XGW_Diag
  SG_ SHVU_R_DiagRespData0 : 7|8@0+ (1,0) [0|255] "" OBD
  SG_ SHVU_R_DiagRespData1 : 15|8@0+ (1,0) [0|255] "-" OBD
  SG_ SHVU_R_DiagRespData2 : 23|8@0+ (1,0) [0|255] "" OBD
  SG_ SHVU_R_DiagRespData3 : 31|8@0+ (1,0) [0|255] "-" OBD
  SG_ SHVU_R_DiagRespData4 : 39|8@0+ (1,0) [0|255] "-" OBD
  SG_ SHVU_R_DiagRespData5 : 47|8@0+ (1,0) [0|255] "" OBD
  SG_ SHVU_R_DiagRespData6 : 55|8@0+ (1,0) [0|255] "-" OBD
  SG_ SHVU_R_DiagRespData7 : 63|8@0+ (1,0) [0|255] "" OBD

BO_ 1604 OCS_P_DiagResp: 8 XGW_Diag
  SG_ OCS_P_DiagRespData0 : 7|8@0+ (1,0) [0|255] "" OBD
  SG_ OCS_P_DiagRespData1 : 15|8@0+ (1,0) [0|255] "-" OBD
  SG_ OCS_P_DiagRespData2 : 23|8@0+ (1,0) [0|255] "" OBD
  SG_ OCS_P_DiagRespData3 : 31|8@0+ (1,0) [0|255] "-" OBD
  SG_ OCS_P_DiagRespData4 : 39|8@0+ (1,0) [0|255] "" OBD
  SG_ OCS_P_DiagRespData5 : 47|8@0+ (1,0) [0|255] "" OBD
  SG_ OCS_P_DiagRespData6 : 55|8@0+ (1,0) [0|255] "" OBD
  SG_ OCS_P_DiagRespData7 : 63|8@0+ (1,0) [0|255] "" OBD

BO_ 1609 LDM_L_DiagResp: 8 XGW_Diag
  SG_ LDM_L_DiagRespData0 : 7|8@0+ (1,0) [0|255] "-" OBD
  SG_ LDM_L_DiagRespData1 : 15|8@0+ (1,0) [0|255] "" OBD
  SG_ LDM_L_DiagRespData2 : 23|8@0+ (1,0) [0|255] "-" OBD
  SG_ LDM_L_DiagRespData3 : 31|8@0+ (1,0) [0|255] "" OBD
  SG_ LDM_L_DiagRespData4 : 39|8@0+ (1,0) [0|255] "" OBD
  SG_ LDM_L_DiagRespData5 : 47|8@0+ (1,0) [0|255] "-" OBD
  SG_ LDM_L_DiagRespData6 : 55|8@0+ (1,0) [0|255] "" OBD
  SG_ LDM_L_DiagRespData7 : 63|8@0+ (1,0) [0|255] "-" OBD

BO_ 1610 LDM_R_DiagResp: 8 XGW_Diag
  SG_ LDM_R_DiagRespData0 : 7|8@0+ (1,0) [0|255] "" OBD
  SG_ LDM_R_DiagRespData1 : 15|8@0+ (1,0) [0|255] "-" OBD
  SG_ LDM_R_DiagRespData2 : 23|8@0+ (1,0) [0|255] "" OBD
  SG_ LDM_R_DiagRespData3 : 31|8@0+ (1,0) [0|255] "" OBD
  SG_ LDM_R_DiagRespData4 : 39|8@0+ (1,0) [0|255] "-" OBD
  SG_ LDM_R_DiagRespData5 : 47|8@0+ (1,0) [0|255] "" OBD
  SG_ LDM_R_DiagRespData6 : 55|8@0+ (1,0) [0|255] "" OBD
  SG_ LDM_R_DiagRespData7 : 63|8@0+ (1,0) [0|255] "-" OBD

BO_ 1624 BAS_DiagResp: 8 XGW_Diag
  SG_ BAS_DiagRespData0 : 7|8@0+ (1,0) [0|255] "" OBD
  SG_ BAS_DiagRespData1 : 15|8@0+ (1,0) [0|255] "" OBD
  SG_ BAS_DiagRespData2 : 23|8@0+ (1,0) [0|255] "" OBD
  SG_ BAS_DiagRespData3 : 31|8@0+ (1,0) [0|255] "" OBD
  SG_ BAS_DiagRespData4 : 39|8@0+ (1,0) [0|255] "" OBD
  SG_ BAS_DiagRespData5 : 47|8@0+ (1,0) [0|255] "" OBD
  SG_ BAS_DiagRespData6 : 55|8@0+ (1,0) [0|255] "" OBD
  SG_ BAS_DiagRespData7 : 63|8@0+ (1,0) [0|255] "" OBD

BO_ 1636 DCM_APM_DiagResp: 8 XGW_Diag
  SG_ DCM_APM_DiagRespData0 : 7|8@0+ (1,0) [0|255] "-" OBD
  SG_ DCM_APM_DiagRespData1 : 15|8@0+ (1,0) [0|255] "-" OBD
  SG_ DCM_APM_DiagRespData2 : 23|8@0+ (1,0) [0|255] "" OBD
  SG_ DCM_APM_DiagRespData3 : 31|8@0+ (1,0) [0|255] "-" OBD
  SG_ DCM_APM_DiagRespData4 : 39|8@0+ (1,0) [0|255] "" OBD
  SG_ DCM_APM_DiagRespData5 : 47|8@0+ (1,0) [0|255] "-" OBD
  SG_ DCM_APM_DiagRespData6 : 55|8@0+ (1,0) [0|255] "-" OBD
  SG_ DCM_APM_DiagRespData7 : 63|8@0+ (1,0) [0|255] "" OBD

BO_ 1659 BCM_BPM_DiagResp: 8 XGW_Diag
  SG_ BCM_BPM_DiagRespData0 : 7|8@0+ (1,0) [0|255] "" OBD
  SG_ BCM_BPM_DiagRespData1 : 15|8@0+ (1,0) [0|255] "-" OBD
  SG_ BCM_BPM_DiagRespData2 : 23|8@0+ (1,0) [0|255] "" OBD
  SG_ BCM_BPM_DiagRespData3 : 31|8@0+ (1,0) [0|255] "" OBD
  SG_ BCM_BPM_DiagRespData4 : 39|8@0+ (1,0) [0|255] "-" OBD
  SG_ BCM_BPM_DiagRespData5 : 47|8@0+ (1,0) [0|255] "" OBD
  SG_ BCM_BPM_DiagRespData6 : 55|8@0+ (1,0) [0|255] "-" OBD
  SG_ BCM_BPM_DiagRespData7 : 63|8@0+ (1,0) [0|255] "" OBD

BO_ 1665 BCM_DiagReq: 8 OBD
  SG_ BCM_DiagReqData0 : 7|8@0+ (1,0) [0|255] "" XGW_Diag
  SG_ BCM_DiagReqData1 : 15|8@0+ (1,0) [0|255] "" XGW_Diag
  SG_ BCM_DiagReqData2 : 23|8@0+ (1,0) [0|255] "" XGW_Diag
  SG_ BCM_DiagReqData3 : 31|8@0+ (1,0) [0|255] "" XGW_Diag
  SG_ BCM_DiagReqData4 : 39|8@0+ (1,0) [0|255] "" XGW_Diag
  SG_ BCM_DiagReqData5 : 47|8@0+ (1,0) [0|255] "" XGW_Diag
  SG_ BCM_DiagReqData6 : 55|8@0+ (1,0) [0|255] "-" XGW_Diag
  SG_ BCM_DiagReqData7 : 63|8@0+ (1,0) [0|255] "-" XGW_Diag

BO_ 1666 XGW_DiagReq: 8 OBD
  SG_ XGW_DiagReqData0 : 7|8@0+ (1,0) [0|255] "" XGW_Diag
  SG_ XGW_DiagReqData1 : 15|8@0+ (1,0) [0|255] "" XGW_Diag
  SG_ XGW_DiagReqData2 : 23|8@0+ (1,0) [0|255] "-" XGW_Diag
  SG_ XGW_DiagReqData3 : 31|8@0+ (1,0) [0|255] "-" XGW_Diag
  SG_ XGW_DiagReqData4 : 39|8@0+ (1,0) [0|255] "" XGW_Diag
  SG_ XGW_DiagReqData5 : 47|8@0+ (1,0) [0|255] "" XGW_Diag
  SG_ XGW_DiagReqData6 : 55|8@0+ (1,0) [0|255] "" XGW_Diag
  SG_ XGW_DiagReqData7 : 63|8@0+ (1,0) [0|255] "" XGW_Diag

BO_ 1668 MHU_DiagReq: 8 OBD
  SG_ MHU_DiagReqData0 : 7|8@0+ (1,0) [0|255] "" XGW_Diag
  SG_ MHU_DiagReqData1 : 15|8@0+ (1,0) [0|255] "" XGW_Diag
  SG_ MHU_DiagReqData2 : 23|8@0+ (1,0) [0|255] "-" XGW_Diag
  SG_ MHU_DiagReqData3 : 31|8@0+ (1,0) [0|255] "-" XGW_Diag
  SG_ MHU_DiagReqData4 : 39|8@0+ (1,0) [0|255] "" XGW_Diag
  SG_ MHU_DiagReqData5 : 47|8@0+ (1,0) [0|255] "-" XGW_Diag
  SG_ MHU_DiagReqData6 : 55|8@0+ (1,0) [0|255] "-" XGW_Diag
  SG_ MHU_DiagReqData7 : 63|8@0+ (1,0) [0|255] "-" XGW_Diag

BO_ 1669 AMP_DiagReq: 8 OBD
  SG_ AMP_DiagReqData0 : 7|8@0+ (1,0) [0|255] "" XGW_Diag
  SG_ AMP_DiagReqData1 : 15|8@0+ (1,0) [0|255] "-" XGW_Diag
  SG_ AMP_DiagReqData2 : 23|8@0+ (1,0) [0|255] "" XGW_Diag
  SG_ AMP_DiagReqData3 : 31|8@0+ (1,0) [0|255] "" XGW_Diag
  SG_ AMP_DiagReqData4 : 39|8@0+ (1,0) [0|255] "" XGW_Diag
  SG_ AMP_DiagReqData5 : 47|8@0+ (1,0) [0|255] "-" XGW_Diag
  SG_ AMP_DiagReqData6 : 55|8@0+ (1,0) [0|255] "-" XGW_Diag
  SG_ AMP_DiagReqData7 : 63|8@0+ (1,0) [0|255] "" XGW_Diag

BO_ 1672 ACM_DiagReq: 8 OBD
  SG_ ACM_DiagReqData0 : 7|8@0+ (1,0) [0|255] "" XGW_Diag
  SG_ ACM_DiagReqData1 : 15|8@0+ (1,0) [0|255] "" XGW_Diag
  SG_ ACM_DiagReqData2 : 23|8@0+ (1,0) [0|255] "" XGW_Diag
  SG_ ACM_DiagReqData3 : 31|8@0+ (1,0) [0|255] "-" XGW_Diag
  SG_ ACM_DiagReqData4 : 39|8@0+ (1,0) [0|255] "" XGW_Diag
  SG_ ACM_DiagReqData5 : 47|8@0+ (1,0) [0|255] "" XGW_Diag
  SG_ ACM_DiagReqData6 : 55|8@0+ (1,0) [0|255] "-" XGW_Diag
  SG_ ACM_DiagReqData7 : 63|8@0+ (1,0) [0|255] "" XGW_Diag

BO_ 1673 CCUF_DiagReq: 8 OBD
  SG_ CCUF_DiagReqData0 : 7|8@0+ (1,0) [0|255] "-" XGW_Diag
  SG_ CCUF_DiagReqData1 : 15|8@0+ (1,0) [0|255] "" XGW_Diag
  SG_ CCUF_DiagReqData2 : 23|8@0+ (1,0) [0|255] "" XGW_Diag
  SG_ CCUF_DiagReqData3 : 31|8@0+ (1,0) [0|255] "" XGW_Diag
  SG_ CCUF_DiagReqData4 : 39|8@0+ (1,0) [0|255] "" XGW_Diag
  SG_ CCUF_DiagReqData5 : 47|8@0+ (1,0) [0|255] "" XGW_Diag
  SG_ CCUF_DiagReqData6 : 55|8@0+ (1,0) [0|255] "" XGW_Diag
  SG_ CCUF_DiagReqData7 : 63|8@0+ (1,0) [0|255] "" XGW_Diag

BO_ 1677 HUD_DiagReq: 8 OBD
  SG_ HUD_DiagReqData0 : 7|8@0+ (1,0) [0|255] "-" XGW_Diag
  SG_ HUD_DiagReqData1 : 15|8@0+ (1,0) [0|255] "" XGW_Diag
  SG_ HUD_DiagReqData2 : 23|8@0+ (1,0) [0|255] "-" XGW_Diag
  SG_ HUD_DiagReqData3 : 31|8@0+ (1,0) [0|255] "" XGW_Diag
  SG_ HUD_DiagReqData4 : 39|8@0+ (1,0) [0|255] "-" XGW_Diag
  SG_ HUD_DiagReqData5 : 47|8@0+ (1,0) [0|255] "-" XGW_Diag
  SG_ HUD_DiagReqData6 : 55|8@0+ (1,0) [0|255] "" XGW_Diag
  SG_ HUD_DiagReqData7 : 63|8@0+ (1,0) [0|255] "" XGW_Diag

BO_ 1678 ETG_DiagReq: 8 OBD
  SG_ ETG_DiagReqData0 : 7|8@0+ (1,0) [0|255] "" XGW_Diag
  SG_ ETG_DiagReqData1 : 15|8@0+ (1,0) [0|255] "" XGW_Diag
  SG_ ETG_DiagReqData2 : 23|8@0+ (1,0) [0|255] "" XGW_Diag
  SG_ ETG_DiagReqData3 : 31|8@0+ (1,0) [0|255] "" XGW_Diag
  SG_ ETG_DiagReqData4 : 39|8@0+ (1,0) [0|255] "" XGW_Diag
  SG_ ETG_DiagReqData5 : 47|8@0+ (1,0) [0|255] "" XGW_Diag
  SG_ ETG_DiagReqData6 : 55|8@0+ (1,0) [0|255] "" XGW_Diag
  SG_ ETG_DiagReqData7 : 63|8@0+ (1,0) [0|255] "-" XGW_Diag

BO_ 1679 YSS_DiagReq: 8 OBD
  SG_ YSS_DiagReqData0 : 7|8@0+ (1,0) [0|255] "" XGW_Diag
  SG_ YSS_DiagReqData1 : 15|8@0+ (1,0) [0|255] "" XGW_Diag
  SG_ YSS_DiagReqData2 : 23|8@0+ (1,0) [0|255] "-" XGW_Diag
  SG_ YSS_DiagReqData3 : 31|8@0+ (1,0) [0|255] "-" XGW_Diag
  SG_ YSS_DiagReqData4 : 39|8@0+ (1,0) [0|255] "-" XGW_Diag
  SG_ YSS_DiagReqData5 : 47|8@0+ (1,0) [0|255] "-" XGW_Diag
  SG_ YSS_DiagReqData6 : 55|8@0+ (1,0) [0|255] "" XGW_Diag
  SG_ YSS_DiagReqData7 : 63|8@0+ (1,0) [0|255] "" XGW_Diag

BO_ 1680 GS_DiagReq: 8 OBD
  SG_ GS_DiagReqData0 : 7|8@0+ (1,0) [0|255] "" XGW_Diag
  SG_ GS_DiagReqData1 : 15|8@0+ (1,0) [0|255] "" XGW_Diag
  SG_ GS_DiagReqData2 : 23|8@0+ (1,0) [0|255] "" XGW_Diag
  SG_ GS_DiagReqData3 : 31|8@0+ (1,0) [0|255] "" XGW_Diag
  SG_ GS_DiagReqData4 : 39|8@0+ (1,0) [0|255] "-" XGW_Diag
  SG_ GS_DiagReqData5 : 47|8@0+ (1,0) [0|255] "" XGW_Diag
  SG_ GS_DiagReqData6 : 55|8@0+ (1,0) [0|255] "" XGW_Diag
  SG_ GS_DiagReqData7 : 63|8@0+ (1,0) [0|255] "" XGW_Diag

BO_ 1681 ASU_Gateway_DiagReq: 8 OBD
  SG_ ASU_Gateway_DiagReqData0 : 7|8@0+ (1,0) [0|255] "-" XGW_Diag
  SG_ ASU_Gateway_DiagReqData1 : 15|8@0+ (1,0) [0|255] "-" XGW_Diag
  SG_ ASU_Gateway_DiagReqData2 : 23|8@0+ (1,0) [0|255] "-" XGW_Diag
  SG_ ASU_Gateway_DiagReqData3 : 31|8@0+ (1,0) [0|255] "-" XGW_Diag
  SG_ ASU_Gateway_DiagReqData4 : 39|8@0+ (1,0) [0|255] "-" XGW_Diag
  SG_ ASU_Gateway_DiagReqData5 : 47|8@0+ (1,0) [0|255] "-" XGW_Diag
  SG_ ASU_Gateway_DiagReqData6 : 55|8@0+ (1,0) [0|255] "-" XGW_Diag
  SG_ ASU_Gateway_DiagReqData7 : 63|8@0+ (1,0) [0|255] "-" XGW_Diag

BO_ 1683 BMS_DiagReq: 8 OBD
  SG_ BMS_DiagReqData0 : 7|8@0+ (1,0) [0|255] "" XGW_Diag
  SG_ BMS_DiagReqData1 : 15|8@0+ (1,0) [0|255] "" XGW_Diag
  SG_ BMS_DiagReqData2 : 23|8@0+ (1,0) [0|255] "" XGW_Diag
  SG_ BMS_DiagReqData3 : 31|8@0+ (1,0) [0|255] "-" XGW_Diag
  SG_ BMS_DiagReqData4 : 39|8@0+ (1,0) [0|255] "-" XGW_Diag
  SG_ BMS_DiagReqData5 : 47|8@0+ (1,0) [0|255] "-" XGW_Diag
  SG_ BMS_DiagReqData6 : 55|8@0+ (1,0) [0|255] "" XGW_Diag
  SG_ BMS_DiagReqData7 : 63|8@0+ (1,0) [0|255] "" XGW_Diag

BO_ 1684 CCUR_DiagReq: 8 OBD
  SG_ CCUR_DiagReqData0 : 7|8@0+ (1,0) [0|255] "" XGW_Diag
  SG_ CCUR_DiagReqData1 : 15|8@0+ (1,0) [0|255] "" XGW_Diag
  SG_ CCUR_DiagReqData2 : 23|8@0+ (1,0) [0|255] "" XGW_Diag
  SG_ CCUR_DiagReqData3 : 31|8@0+ (1,0) [0|255] "-" XGW_Diag
  SG_ CCUR_DiagReqData4 : 39|8@0+ (1,0) [0|255] "-" XGW_Diag
  SG_ CCUR_DiagReqData5 : 47|8@0+ (1,0) [0|255] "" XGW_Diag
  SG_ CCUR_DiagReqData6 : 55|8@0+ (1,0) [0|255] "" XGW_Diag
  SG_ CCUR_DiagReqData7 : 63|8@0+ (1,0) [0|255] "" XGW_Diag

BO_ 1690 EDS_R_DiagReq: 8 OBD
  SG_ EDS_R_DiagReqData0 : 7|8@0+ (1,0) [0|255] "" XGW_Diag
  SG_ EDS_R_DiagReqData1 : 15|8@0+ (1,0) [0|255] "-" XGW_Diag
  SG_ EDS_R_DiagReqData2 : 23|8@0+ (1,0) [0|255] "" XGW_Diag
  SG_ EDS_R_DiagReqData3 : 31|8@0+ (1,0) [0|255] "-" XGW_Diag
  SG_ EDS_R_DiagReqData4 : 39|8@0+ (1,0) [0|255] "-" XGW_Diag
  SG_ EDS_R_DiagReqData5 : 47|8@0+ (1,0) [0|255] "" XGW_Diag
  SG_ EDS_R_DiagReqData6 : 55|8@0+ (1,0) [0|255] "-" XGW_Diag
  SG_ EDS_R_DiagReqData7 : 63|8@0+ (1,0) [0|255] "" XGW_Diag

BO_ 1691 EDS_F_DiagReq: 8 OBD
  SG_ EDS_F_DiagReqData0 : 7|8@0+ (1,0) [0|255] "-" XGW_Diag
  SG_ EDS_F_DiagReqData1 : 15|8@0+ (1,0) [0|255] "" XGW_Diag
  SG_ EDS_F_DiagReqData2 : 23|8@0+ (1,0) [0|255] "-" XGW_Diag
  SG_ EDS_F_DiagReqData3 : 31|8@0+ (1,0) [0|255] "" XGW_Diag
  SG_ EDS_F_DiagReqData4 : 39|8@0+ (1,0) [0|255] "" XGW_Diag
  SG_ EDS_F_DiagReqData5 : 47|8@0+ (1,0) [0|255] "" XGW_Diag
  SG_ EDS_F_DiagReqData6 : 55|8@0+ (1,0) [0|255] "" XGW_Diag
  SG_ EDS_F_DiagReqData7 : 63|8@0+ (1,0) [0|255] "" XGW_Diag

BO_ 1694 PSM_D_DiagReq: 8 OBD
  SG_ PSM_D_DiagReqData0 : 7|8@0+ (1,0) [0|255] "-" XGW_Diag
  SG_ PSM_D_DiagReqData1 : 15|8@0+ (1,0) [0|255] "" XGW_Diag
  SG_ PSM_D_DiagReqData2 : 23|8@0+ (1,0) [0|255] "-" XGW_Diag
  SG_ PSM_D_DiagReqData3 : 31|8@0+ (1,0) [0|255] "" XGW_Diag
  SG_ PSM_D_DiagReqData4 : 39|8@0+ (1,0) [0|255] "" XGW_Diag
  SG_ PSM_D_DiagReqData5 : 47|8@0+ (1,0) [0|255] "-" XGW_Diag
  SG_ PSM_D_DiagReqData6 : 55|8@0+ (1,0) [0|255] "-" XGW_Diag
  SG_ PSM_D_DiagReqData7 : 63|8@0+ (1,0) [0|255] "" XGW_Diag

BO_ 1701 MRGEN_DiagReq: 8 OBD
  SG_ MRGEN_DiagReqData0 : 7|8@0+ (1,0) [0|255] "" XGW_Diag
  SG_ MRGEN_DiagReqData1 : 15|8@0+ (1,0) [0|255] "" XGW_Diag
  SG_ MRGEN_DiagReqData2 : 23|8@0+ (1,0) [0|255] "" XGW_Diag
  SG_ MRGEN_DiagReqData3 : 31|8@0+ (1,0) [0|255] "" XGW_Diag
  SG_ MRGEN_DiagReqData4 : 39|8@0+ (1,0) [0|255] "" XGW_Diag
  SG_ MRGEN_DiagReqData5 : 47|8@0+ (1,0) [0|255] "-" XGW_Diag
  SG_ MRGEN_DiagReqData6 : 55|8@0+ (1,0) [0|255] "" XGW_Diag
  SG_ MRGEN_DiagReqData7 : 63|8@0+ (1,0) [0|255] "" XGW_Diag

BO_ 1702 SCAM_DiagReq: 8 OBD
  SG_ SCAM_DiagReqData0 : 7|8@0+ (1,0) [0|255] "-" XGW_Diag
  SG_ SCAM_DiagReqData1 : 15|8@0+ (1,0) [0|255] "" XGW_Diag
  SG_ SCAM_DiagReqData2 : 23|8@0+ (1,0) [0|255] "-" XGW_Diag
  SG_ SCAM_DiagReqData3 : 31|8@0+ (1,0) [0|255] "-" XGW_Diag
  SG_ SCAM_DiagReqData4 : 39|8@0+ (1,0) [0|255] "" XGW_Diag
  SG_ SCAM_DiagReqData5 : 47|8@0+ (1,0) [0|255] "-" XGW_Diag
  SG_ SCAM_DiagReqData6 : 55|8@0+ (1,0) [0|255] "-" XGW_Diag
  SG_ SCAM_DiagReqData7 : 63|8@0+ (1,0) [0|255] "-" XGW_Diag

BO_ 1703 RCU_DiagReq: 8 OBD
  SG_ RCU_DiagReqData0 : 7|8@0+ (1,0) [0|255] "" XGW_Diag
  SG_ RCU_DiagReqData1 : 15|8@0+ (1,0) [0|255] "" XGW_Diag
  SG_ RCU_DiagReqData2 : 23|8@0+ (1,0) [0|255] "" XGW_Diag
  SG_ RCU_DiagReqData3 : 31|8@0+ (1,0) [0|255] "" XGW_Diag
  SG_ RCU_DiagReqData4 : 39|8@0+ (1,0) [0|255] "-" XGW_Diag
  SG_ RCU_DiagReqData5 : 47|8@0+ (1,0) [0|255] "" XGW_Diag
  SG_ RCU_DiagReqData6 : 55|8@0+ (1,0) [0|255] "-" XGW_Diag
  SG_ RCU_DiagReqData7 : 63|8@0+ (1,0) [0|255] "-" XGW_Diag

BO_ 1704 EPS_DiagReq: 8 OBD
  SG_ EPS_DiagReqData0 : 7|8@0+ (1,0) [0|255] "-" XGW_Diag
  SG_ EPS_DiagReqData1 : 15|8@0+ (1,0) [0|255] "" XGW_Diag
  SG_ EPS_DiagReqData2 : 23|8@0+ (1,0) [0|255] "" XGW_Diag
  SG_ EPS_DiagReqData3 : 31|8@0+ (1,0) [0|255] "" XGW_Diag
  SG_ EPS_DiagReqData4 : 39|8@0+ (1,0) [0|255] "-" XGW_Diag
  SG_ EPS_DiagReqData5 : 47|8@0+ (1,0) [0|255] "-" XGW_Diag
  SG_ EPS_DiagReqData6 : 55|8@0+ (1,0) [0|255] "-" XGW_Diag
  SG_ EPS_DiagReqData7 : 63|8@0+ (1,0) [0|255] "" XGW_Diag

BO_ 1705 IDB_DiagReq: 8 OBD
  SG_ IDB_DiagReqData0 : 7|8@0+ (1,0) [0|255] "" XGW_Diag
  SG_ IDB_DiagReqData1 : 15|8@0+ (1,0) [0|255] "" XGW_Diag
  SG_ IDB_DiagReqData2 : 23|8@0+ (1,0) [0|255] "" XGW_Diag
  SG_ IDB_DiagReqData3 : 31|8@0+ (1,0) [0|255] "" XGW_Diag
  SG_ IDB_DiagReqData4 : 39|8@0+ (1,0) [0|255] "" XGW_Diag
  SG_ IDB_DiagReqData5 : 47|8@0+ (1,0) [0|255] "" XGW_Diag
  SG_ IDB_DiagReqData6 : 55|8@0+ (1,0) [0|255] "-" XGW_Diag
  SG_ IDB_DiagReqData7 : 63|8@0+ (1,0) [0|255] "" XGW_Diag

BO_ 1706 AVAS_DiagReq: 8 OBD
  SG_ AVAS_DiagReqData0 : 7|8@0+ (1,0) [0|255] "-" XGW_Diag
  SG_ AVAS_DiagReqData1 : 15|8@0+ (1,0) [0|255] "" XGW_Diag
  SG_ AVAS_DiagReqData2 : 23|8@0+ (1,0) [0|255] "" XGW_Diag
  SG_ AVAS_DiagReqData3 : 31|8@0+ (1,0) [0|255] "-" XGW_Diag
  SG_ AVAS_DiagReqData4 : 39|8@0+ (1,0) [0|255] "" XGW_Diag
  SG_ AVAS_DiagReqData5 : 47|8@0+ (1,0) [0|255] "" XGW_Diag
  SG_ AVAS_DiagReqData6 : 55|8@0+ (1,0) [0|255] "" XGW_Diag
  SG_ AVAS_DiagReqData7 : 63|8@0+ (1,0) [0|255] "" XGW_Diag

BO_ 1707 EPS2_DiagReq: 8 OBD
  SG_ EPS2_DiagReqData0 : 7|8@0+ (1,0) [0|255] "" XGW_Diag
  SG_ EPS2_DiagReqData1 : 15|8@0+ (1,0) [0|255] "" XGW_Diag
  SG_ EPS2_DiagReqData2 : 23|8@0+ (1,0) [0|255] "" XGW_Diag
  SG_ EPS2_DiagReqData3 : 31|8@0+ (1,0) [0|255] "-" XGW_Diag
  SG_ EPS2_DiagReqData4 : 39|8@0+ (1,0) [0|255] "" XGW_Diag
  SG_ EPS2_DiagReqData5 : 47|8@0+ (1,0) [0|255] "-" XGW_Diag
  SG_ EPS2_DiagReqData6 : 55|8@0+ (1,0) [0|255] "" XGW_Diag
  SG_ EPS2_DiagReqData7 : 63|8@0+ (1,0) [0|255] "" XGW_Diag

BO_ 1708 VCU_DiagReq: 8 OBD
  SG_ VCU_DiagReqData0 : 7|8@0+ (1,0) [0|255] "-" XGW_Diag
  SG_ VCU_DiagReqData1 : 15|8@0+ (1,0) [0|255] "" XGW_Diag
  SG_ VCU_DiagReqData2 : 23|8@0+ (1,0) [0|255] "-" XGW_Diag
  SG_ VCU_DiagReqData3 : 31|8@0+ (1,0) [0|255] "" XGW_Diag
  SG_ VCU_DiagReqData4 : 39|8@0+ (1,0) [0|255] "" XGW_Diag
  SG_ VCU_DiagReqData5 : 47|8@0+ (1,0) [0|255] "-" XGW_Diag
  SG_ VCU_DiagReqData6 : 55|8@0+ (1,0) [0|255] "" XGW_Diag
  SG_ VCU_DiagReqData7 : 63|8@0+ (1,0) [0|255] "-" XGW_Diag

BO_ 1709 CPD_2_DiagReq: 8 OBD
  SG_ CPD_2_DiagReqData0 : 7|8@0+ (1,0) [0|0] "" XGW_Diag
  SG_ CPD_2_DiagReqData1 : 15|8@0+ (1,0) [0|0] "" XGW_Diag
  SG_ CPD_2_DiagReqData2 : 23|8@0+ (1,0) [0|0] "" XGW_Diag
  SG_ CPD_2_DiagReqData3 : 31|8@0+ (1,0) [0|0] "" XGW_Diag
  SG_ CPD_2_DiagReqData4 : 39|8@0+ (1,0) [0|0] "" XGW_Diag
  SG_ CPD_2_DiagReqData5 : 47|8@0+ (1,0) [0|0] "" XGW_Diag
  SG_ CPD_2_DiagReqData6 : 55|8@0+ (1,0) [0|0] "" XGW_Diag
  SG_ CPD_2_DiagReqData7 : 63|8@0+ (1,0) [0|0] "" XGW_Diag

BO_ 1710 EASC_DiagReq: 8 OBD
  SG_ EASC_DiagReqData0 : 7|8@0+ (1,0) [0|255] "" XGW_Diag
  SG_ EASC_DiagReqData1 : 15|8@0+ (1,0) [0|255] "-" XGW_Diag
  SG_ EASC_DiagReqData2 : 23|8@0+ (1,0) [0|255] "-" XGW_Diag
  SG_ EASC_DiagReqData3 : 31|8@0+ (1,0) [0|255] "" XGW_Diag
  SG_ EASC_DiagReqData4 : 39|8@0+ (1,0) [0|255] "-" XGW_Diag
  SG_ EASC_DiagReqData5 : 47|8@0+ (1,0) [0|255] "-" XGW_Diag
  SG_ EASC_DiagReqData6 : 55|8@0+ (1,0) [0|255] "" XGW_Diag
  SG_ EASC_DiagReqData7 : 63|8@0+ (1,0) [0|255] "-" XGW_Diag

BO_ 1711 CPD_DiagReq: 8 OBD
  SG_ CPD_DiagReqData0 : 7|8@0+ (1,0) [0|255] "-" XGW_Diag
  SG_ CPD_DiagReqData1 : 15|8@0+ (1,0) [0|255] "-" XGW_Diag
  SG_ CPD_DiagReqData2 : 23|8@0+ (1,0) [0|255] "-" XGW_Diag
  SG_ CPD_DiagReqData3 : 31|8@0+ (1,0) [0|255] "" XGW_Diag
  SG_ CPD_DiagReqData4 : 39|8@0+ (1,0) [0|255] "-" XGW_Diag
  SG_ CPD_DiagReqData5 : 47|8@0+ (1,0) [0|255] "" XGW_Diag
  SG_ CPD_DiagReqData6 : 55|8@0+ (1,0) [0|255] "-" XGW_Diag
  SG_ CPD_DiagReqData7 : 63|8@0+ (1,0) [0|255] "-" XGW_Diag

BO_ 1716 SRR_FR_DiagReq: 8 OBD
  SG_ SRR_FR_DiagReqData0 : 7|8@0+ (1,0) [0|255] "" XGW_Diag
  SG_ SRR_FR_DiagReqData1 : 15|8@0+ (1,0) [0|255] "" XGW_Diag
  SG_ SRR_FR_DiagReqData2 : 23|8@0+ (1,0) [0|255] "" XGW_Diag
  SG_ SRR_FR_DiagReqData3 : 31|8@0+ (1,0) [0|255] "" XGW_Diag
  SG_ SRR_FR_DiagReqData4 : 39|8@0+ (1,0) [0|255] "" XGW_Diag
  SG_ SRR_FR_DiagReqData5 : 47|8@0+ (1,0) [0|255] "" XGW_Diag
  SG_ SRR_FR_DiagReqData6 : 55|8@0+ (1,0) [0|255] "" XGW_Diag
  SG_ SRR_FR_DiagReqData7 : 63|8@0+ (1,0) [0|255] "" XGW_Diag

BO_ 1717 SRR_FL_DiagReq: 8 OBD
  SG_ SRR_FL_DiagReqData0 : 7|8@0+ (1,0) [0|255] "" XGW_Diag
  SG_ SRR_FL_DiagReqData1 : 15|8@0+ (1,0) [0|255] "" XGW_Diag
  SG_ SRR_FL_DiagReqData2 : 23|8@0+ (1,0) [0|255] "" XGW_Diag
  SG_ SRR_FL_DiagReqData3 : 31|8@0+ (1,0) [0|255] "" XGW_Diag
  SG_ SRR_FL_DiagReqData4 : 39|8@0+ (1,0) [0|255] "" XGW_Diag
  SG_ SRR_FL_DiagReqData5 : 47|8@0+ (1,0) [0|255] "" XGW_Diag
  SG_ SRR_FL_DiagReqData6 : 55|8@0+ (1,0) [0|255] "" XGW_Diag
  SG_ SRR_FL_DiagReqData7 : 63|8@0+ (1,0) [0|255] "" XGW_Diag

BO_ 1718 SRR_RR_DiagReq: 8 OBD
  SG_ SRR_RR_DiagReqData0 : 7|8@0+ (1,0) [0|255] "" XGW_Diag
  SG_ SRR_RR_DiagReqData1 : 15|8@0+ (1,0) [0|255] "" XGW_Diag
  SG_ SRR_RR_DiagReqData2 : 23|8@0+ (1,0) [0|255] "" XGW_Diag
  SG_ SRR_RR_DiagReqData3 : 31|8@0+ (1,0) [0|255] "" XGW_Diag
  SG_ SRR_RR_DiagReqData4 : 39|8@0+ (1,0) [0|255] "" XGW_Diag
  SG_ SRR_RR_DiagReqData5 : 47|8@0+ (1,0) [0|255] "" XGW_Diag
  SG_ SRR_RR_DiagReqData6 : 55|8@0+ (1,0) [0|255] "" XGW_Diag
  SG_ SRR_RR_DiagReqData7 : 63|8@0+ (1,0) [0|255] "" XGW_Diag

BO_ 1719 SRR_RL_DiagReq: 8 OBD
  SG_ SRR_RL_DiagReqData0 : 7|8@0+ (1,0) [0|255] "" XGW_Diag
  SG_ SRR_RL_DiagReqData1 : 15|8@0+ (1,0) [0|255] "" XGW_Diag
  SG_ SRR_RL_DiagReqData2 : 23|8@0+ (1,0) [0|255] "" XGW_Diag
  SG_ SRR_RL_DiagReqData3 : 31|8@0+ (1,0) [0|255] "" XGW_Diag
  SG_ SRR_RL_DiagReqData4 : 39|8@0+ (1,0) [0|255] "" XGW_Diag
  SG_ SRR_RL_DiagReqData5 : 47|8@0+ (1,0) [0|255] "" XGW_Diag
  SG_ SRR_RL_DiagReqData6 : 55|8@0+ (1,0) [0|255] "" XGW_Diag
  SG_ SRR_RL_DiagReqData7 : 63|8@0+ (1,0) [0|255] "" XGW_Diag

BO_ 1723 TRM_DiagReq: 8 OBD
  SG_ TRM_DiagReqData0 : 7|8@0+ (1,0) [0|255] "" XGW_Diag
  SG_ TRM_DiagReqData1 : 15|8@0+ (1,0) [0|255] "" XGW_Diag
  SG_ TRM_DiagReqData2 : 23|8@0+ (1,0) [0|255] "-" XGW_Diag
  SG_ TRM_DiagReqData3 : 31|8@0+ (1,0) [0|255] "-" XGW_Diag
  SG_ TRM_DiagReqData4 : 39|8@0+ (1,0) [0|255] "-" XGW_Diag
  SG_ TRM_DiagReqData5 : 47|8@0+ (1,0) [0|255] "" XGW_Diag
  SG_ TRM_DiagReqData6 : 55|8@0+ (1,0) [0|255] "" XGW_Diag
  SG_ TRM_DiagReqData7 : 63|8@0+ (1,0) [0|255] "-" XGW_Diag

BO_ 1725 POD_DCDC_DiagReq: 8 OBD
  SG_ POD_DCDC_DiagReqData0 : 7|8@0+ (1,0) [0|255] "" XGW_Diag
  SG_ POD_DCDC_DiagReqData1 : 15|8@0+ (1,0) [0|255] "" XGW_Diag
  SG_ POD_DCDC_DiagReqData2 : 23|8@0+ (1,0) [0|255] "-" XGW_Diag
  SG_ POD_DCDC_DiagReqData3 : 31|8@0+ (1,0) [0|255] "" XGW_Diag
  SG_ POD_DCDC_DiagReqData4 : 39|8@0+ (1,0) [0|255] "-" XGW_Diag
  SG_ POD_DCDC_DiagReqData5 : 47|8@0+ (1,0) [0|255] "-" XGW_Diag
  SG_ POD_DCDC_DiagReqData6 : 55|8@0+ (1,0) [0|255] "" XGW_Diag
  SG_ POD_DCDC_DiagReqData7 : 63|8@0+ (1,0) [0|255] "" XGW_Diag

BO_ 1726 POD_OBC_DiagReq: 8 OBD
  SG_ POD_OBC_DiagReqData0 : 7|8@0+ (1,0) [0|255] "" XGW_Diag
  SG_ POD_OBC_DiagReqData1 : 15|8@0+ (1,0) [0|255] "" XGW_Diag
  SG_ POD_OBC_DiagReqData2 : 23|8@0+ (1,0) [0|255] "" XGW_Diag
  SG_ POD_OBC_DiagReqData3 : 31|8@0+ (1,0) [0|255] "-" XGW_Diag
  SG_ POD_OBC_DiagReqData4 : 39|8@0+ (1,0) [0|255] "" XGW_Diag
  SG_ POD_OBC_DiagReqData5 : 47|8@0+ (1,0) [0|255] "" XGW_Diag
  SG_ POD_OBC_DiagReqData6 : 55|8@0+ (1,0) [0|255] "" XGW_Diag
  SG_ POD_OBC_DiagReqData7 : 63|8@0+ (1,0) [0|255] "-" XGW_Diag

BO_ 1727 POD_GW_Request: 8 OBD
  SG_ POD_DiagReqData0 : 7|8@0+ (1,0) [0|255] "-" XGW_Diag
  SG_ POD_DiagReqData1 : 15|8@0+ (1,0) [0|255] "" XGW_Diag
  SG_ POD_DiagReqData2 : 23|8@0+ (1,0) [0|255] "" XGW_Diag
  SG_ POD_DiagReqData3 : 31|8@0+ (1,0) [0|255] "" XGW_Diag
  SG_ POD_DiagReqData4 : 39|8@0+ (1,0) [0|255] "" XGW_Diag
  SG_ POD_DiagReqData5 : 47|8@0+ (1,0) [0|255] "" XGW_Diag
  SG_ POD_DiagReqData6 : 55|8@0+ (1,0) [0|255] "" XGW_Diag
  SG_ POD_DiagReqData7 : 63|8@0+ (1,0) [0|255] "" XGW_Diag

BO_ 1728 ADAS_DiagReq: 8 OBD
  SG_ ADAS_DiagReqData0 : 7|8@0+ (1,0) [0|255] "" XGW_Diag
  SG_ ADAS_DiagReqData1 : 15|8@0+ (1,0) [0|255] "" XGW_Diag
  SG_ ADAS_DiagReqData2 : 23|8@0+ (1,0) [0|255] "" XGW_Diag
  SG_ ADAS_DiagReqData3 : 31|8@0+ (1,0) [0|255] "" XGW_Diag
  SG_ ADAS_DiagReqData4 : 39|8@0+ (1,0) [0|255] "" XGW_Diag
  SG_ ADAS_DiagReqData5 : 47|8@0+ (1,0) [0|255] "" XGW_Diag
  SG_ ADAS_DiagReqData6 : 55|8@0+ (1,0) [0|255] "" XGW_Diag
  SG_ ADAS_DiagReqData7 : 63|8@0+ (1,0) [0|255] "" XGW_Diag

BO_ 1729 APM_DiagReq: 8 OBD
  SG_ APM_DiagReqData0 : 7|8@0+ (1,0) [0|255] "" XGW_Diag
  SG_ APM_DiagReqData1 : 15|8@0+ (1,0) [0|255] "" XGW_Diag
  SG_ APM_DiagReqData2 : 23|8@0+ (1,0) [0|255] "-" XGW_Diag
  SG_ APM_DiagReqData3 : 31|8@0+ (1,0) [0|255] "" XGW_Diag
  SG_ APM_DiagReqData4 : 39|8@0+ (1,0) [0|255] "" XGW_Diag
  SG_ APM_DiagReqData5 : 47|8@0+ (1,0) [0|255] "-" XGW_Diag
  SG_ APM_DiagReqData6 : 55|8@0+ (1,0) [0|255] "" XGW_Diag
  SG_ APM_DiagReqData7 : 63|8@0+ (1,0) [0|255] "" XGW_Diag

BO_ 1730 SHVU_F_DiagReq: 8 OBD
  SG_ SHVU_F_DiagReqData0 : 7|8@0+ (1,0) [0|255] "" XGW_Diag
  SG_ SHVU_F_DiagReqData1 : 15|8@0+ (1,0) [0|255] "" XGW_Diag
  SG_ SHVU_F_DiagReqData2 : 23|8@0+ (1,0) [0|255] "" XGW_Diag
  SG_ SHVU_F_DiagReqData3 : 31|8@0+ (1,0) [0|255] "-" XGW_Diag
  SG_ SHVU_F_DiagReqData4 : 39|8@0+ (1,0) [0|255] "" XGW_Diag
  SG_ SHVU_F_DiagReqData5 : 47|8@0+ (1,0) [0|255] "" XGW_Diag
  SG_ SHVU_F_DiagReqData6 : 55|8@0+ (1,0) [0|255] "-" XGW_Diag
  SG_ SHVU_F_DiagReqData7 : 63|8@0+ (1,0) [0|255] "" XGW_Diag

BO_ 1731 SHVU_R_DiagReq: 8 OBD
  SG_ SHVU_R_DiagReqData0 : 7|8@0+ (1,0) [0|255] "" XGW_Diag
  SG_ SHVU_R_DiagReqData1 : 15|8@0+ (1,0) [0|255] "" XGW_Diag
  SG_ SHVU_R_DiagReqData2 : 23|8@0+ (1,0) [0|255] "" XGW_Diag
  SG_ SHVU_R_DiagReqData3 : 31|8@0+ (1,0) [0|255] "" XGW_Diag
  SG_ SHVU_R_DiagReqData4 : 39|8@0+ (1,0) [0|255] "" XGW_Diag
  SG_ SHVU_R_DiagReqData5 : 47|8@0+ (1,0) [0|255] "-" XGW_Diag
  SG_ SHVU_R_DiagReqData6 : 55|8@0+ (1,0) [0|255] "" XGW_Diag
  SG_ SHVU_R_DiagReqData7 : 63|8@0+ (1,0) [0|255] "" XGW_Diag

BO_ 1732 OCS_P_DiagReq: 8 OBD
  SG_ OCS_P_DiagReqData0 : 7|8@0+ (1,0) [0|255] "-" XGW_Diag
  SG_ OCS_P_DiagReqData1 : 15|8@0+ (1,0) [0|255] "" XGW_Diag
  SG_ OCS_P_DiagReqData2 : 23|8@0+ (1,0) [0|255] "" XGW_Diag
  SG_ OCS_P_DiagReqData3 : 31|8@0+ (1,0) [0|255] "" XGW_Diag
  SG_ OCS_P_DiagReqData4 : 39|8@0+ (1,0) [0|255] "" XGW_Diag
  SG_ OCS_P_DiagReqData5 : 47|8@0+ (1,0) [0|255] "" XGW_Diag
  SG_ OCS_P_DiagReqData6 : 55|8@0+ (1,0) [0|255] "" XGW_Diag
  SG_ OCS_P_DiagReqData7 : 63|8@0+ (1,0) [0|255] "-" XGW_Diag

BO_ 1737 LDM_L_DiagReq: 8 OBD
  SG_ LDM_L_DiagReqData0 : 7|8@0+ (1,0) [0|255] "-" XGW_Diag
  SG_ LDM_L_DiagReqData1 : 15|8@0+ (1,0) [0|255] "" XGW_Diag
  SG_ LDM_L_DiagReqData2 : 23|8@0+ (1,0) [0|255] "" XGW_Diag
  SG_ LDM_L_DiagReqData3 : 31|8@0+ (1,0) [0|255] "" XGW_Diag
  SG_ LDM_L_DiagReqData4 : 39|8@0+ (1,0) [0|255] "-" XGW_Diag
  SG_ LDM_L_DiagReqData5 : 47|8@0+ (1,0) [0|255] "" XGW_Diag
  SG_ LDM_L_DiagReqData6 : 55|8@0+ (1,0) [0|255] "" XGW_Diag
  SG_ LDM_L_DiagReqData7 : 63|8@0+ (1,0) [0|255] "" XGW_Diag

BO_ 1738 LDM_R_DiagReq: 8 OBD
  SG_ LDM_R_DiagReqData0 : 7|8@0+ (1,0) [0|255] "" XGW_Diag
  SG_ LDM_R_DiagReqData1 : 15|8@0+ (1,0) [0|255] "" XGW_Diag
  SG_ LDM_R_DiagReqData2 : 23|8@0+ (1,0) [0|255] "" XGW_Diag
  SG_ LDM_R_DiagReqData3 : 31|8@0+ (1,0) [0|255] "-" XGW_Diag
  SG_ LDM_R_DiagReqData4 : 39|8@0+ (1,0) [0|255] "" XGW_Diag
  SG_ LDM_R_DiagReqData5 : 47|8@0+ (1,0) [0|255] "" XGW_Diag
  SG_ LDM_R_DiagReqData6 : 55|8@0+ (1,0) [0|255] "-" XGW_Diag
  SG_ LDM_R_DiagReqData7 : 63|8@0+ (1,0) [0|255] "-" XGW_Diag

BO_ 1752 BAS_DiagReq: 8 OBD
  SG_ BAS_DiagReqData0 : 7|8@0+ (1,0) [0|255] "" XGW_Diag
  SG_ BAS_DiagReqData1 : 15|8@0+ (1,0) [0|255] "" XGW_Diag
  SG_ BAS_DiagReqData2 : 23|8@0+ (1,0) [0|255] "" XGW_Diag
  SG_ BAS_DiagReqData3 : 31|8@0+ (1,0) [0|255] "" XGW_Diag
  SG_ BAS_DiagReqData4 : 39|8@0+ (1,0) [0|255] "" XGW_Diag
  SG_ BAS_DiagReqData5 : 47|8@0+ (1,0) [0|255] "" XGW_Diag
  SG_ BAS_DiagReqData6 : 55|8@0+ (1,0) [0|255] "" XGW_Diag
  SG_ BAS_DiagReqData7 : 63|8@0+ (1,0) [0|255] "" XGW_Diag

BO_ 1764 DCM_APM_DiagReq: 8 OBD
  SG_ DCM_APM_DiagReqData0 : 7|8@0+ (1,0) [0|255] "-" XGW_Diag
  SG_ DCM_APM_DiagReqData1 : 15|8@0+ (1,0) [0|255] "-" XGW_Diag
  SG_ DCM_APM_DiagReqData2 : 23|8@0+ (1,0) [0|255] "-" XGW_Diag
  SG_ DCM_APM_DiagReqData3 : 31|8@0+ (1,0) [0|255] "-" XGW_Diag
  SG_ DCM_APM_DiagReqData4 : 39|8@0+ (1,0) [0|255] "" XGW_Diag
  SG_ DCM_APM_DiagReqData5 : 47|8@0+ (1,0) [0|255] "" XGW_Diag
  SG_ DCM_APM_DiagReqData6 : 55|8@0+ (1,0) [0|255] "" XGW_Diag
  SG_ DCM_APM_DiagReqData7 : 63|8@0+ (1,0) [0|255] "" XGW_Diag

BO_ 1775 DIAG_Req_All_CAN: 8 OBD
  SG_ DiagReqAllCANData0 : 7|8@0+ (1,0) [0|255] "-" XGW_Diag
  SG_ DiagReqAllCANData1 : 15|8@0+ (1,0) [0|255] "" XGW_Diag
  SG_ DiagReqAllCANData2 : 23|8@0+ (1,0) [0|255] "-" XGW_Diag
  SG_ DiagReqAllCANData3 : 31|8@0+ (1,0) [0|255] "-" XGW_Diag
  SG_ DiagReqAllCANData4 : 39|8@0+ (1,0) [0|255] "" XGW_Diag
  SG_ DiagReqAllCANData5 : 47|8@0+ (1,0) [0|255] "" XGW_Diag
  SG_ DiagReqAllCANData6 : 55|8@0+ (1,0) [0|255] "" XGW_Diag
  SG_ DiagReqAllCANData7 : 63|8@0+ (1,0) [0|255] "" XGW_Diag

BO_ 1777 ASU_DiagReq: 8 OBD
  SG_ ASU_DiagReqData0 : 7|8@0+ (1,0) [0|255] "-" XGW_Diag
  SG_ ASU_DiagReqData1 : 15|8@0+ (1,0) [0|255] "-" XGW_Diag
  SG_ ASU_DiagReqData2 : 23|8@0+ (1,0) [0|255] "-" XGW_Diag
  SG_ ASU_DiagReqData3 : 31|8@0+ (1,0) [0|255] "-" XGW_Diag
  SG_ ASU_DiagReqData4 : 39|8@0+ (1,0) [0|255] "-" XGW_Diag
  SG_ ASU_DiagReqData5 : 47|8@0+ (1,0) [0|255] "-" XGW_Diag
  SG_ ASU_DiagReqData6 : 55|8@0+ (1,0) [0|255] "-" XGW_Diag
  SG_ ASU_DiagReqData7 : 63|8@0+ (1,0) [0|255] "-" XGW_Diag

BO_ 1787 BCM_BPM_DiagReq: 8 OBD
  SG_ BCM_BPM_DiagReqData0 : 7|8@0+ (1,0) [0|255] "-" XGW_Diag
  SG_ BCM_BPM_DiagReqData1 : 15|8@0+ (1,0) [0|255] "" XGW_Diag
  SG_ BCM_BPM_DiagReqData2 : 23|8@0+ (1,0) [0|255] "" XGW_Diag
  SG_ BCM_BPM_DiagReqData3 : 31|8@0+ (1,0) [0|255] "" XGW_Diag
  SG_ BCM_BPM_DiagReqData4 : 39|8@0+ (1,0) [0|255] "" XGW_Diag
  SG_ BCM_BPM_DiagReqData5 : 47|8@0+ (1,0) [0|255] "" XGW_Diag
  SG_ BCM_BPM_DiagReqData6 : 55|8@0+ (1,0) [0|255] "-" XGW_Diag
  SG_ BCM_BPM_DiagReqData7 : 63|8@0+ (1,0) [0|255] "-" XGW_Diag

BO_ 1791 DIAG_Req_All_Ecu: 8 OBD
  SG_ DiagReqAllEcuData0 : 7|8@0+ (1,0) [0|255] "-" XGW_Diag
  SG_ DiagReqAllEcuData1 : 15|8@0+ (1,0) [0|255] "" XGW_Diag
  SG_ DiagReqAllEcuData2 : 23|8@0+ (1,0) [0|255] "" XGW_Diag
  SG_ DiagReqAllEcuData3 : 31|8@0+ (1,0) [0|255] "" XGW_Diag
  SG_ DiagReqAllEcuData4 : 39|8@0+ (1,0) [0|255] "-" XGW_Diag
  SG_ DiagReqAllEcuData5 : 47|8@0+ (1,0) [0|255] "" XGW_Diag
  SG_ DiagReqAllEcuData6 : 55|8@0+ (1,0) [0|255] "" XGW_Diag
  SG_ DiagReqAllEcuData7 : 63|8@0+ (1,0) [0|255] "" XGW_Diag

BO_ 2033 DIAG_Req_Airbag_Deploy: 8 OBD
  SG_ Request_Airbag_Deployment : 7|64@0+ (1,0) [0|1.84467440737096E+019] "" XGW_Diag

BO_ 2041 DIAG_Resp_Airbag_Deploy: 8 XGW_Diag
  SG_ Response_Airbag_Deployment : 7|64@0+ (1,0) [0|255] "" OBD

CM_ "This dbc file for FRS build";
CM_ BO_ 1537 "BCM DiagResp";
CM_ BO_ 1538 "XGW DiagResp";
CM_ BO_ 1540 "MHU DiagResp";
CM_ BO_ 1541 "Diagnostic Response for AMP ";
CM_ BO_ 1544 "ACM DiagResp";
CM_ BO_ 1545 "CCU DiagResp";
CM_ BO_ 1549 "HUD DiagResp";
CM_ BO_ 1550 "ETG DiagResp";
CM_ BO_ 1551 "Diagnostic Response for YSS     ";
CM_ BO_ 1552 "GS Diagnostic Responde";
CM_ BO_ 1553 "ASU gateway Diagnostic response";
CM_ BO_ 1555 "BMS Diagnostic Responde";
CM_ BO_ 1556 "CCUR Diagnostic Response";
CM_ BO_ 1562 "EDS Rear Diagnostic Responde";
CM_ BO_ 1563 "EDS Front Diagnostic Responde";
CM_ BO_ 1566 "PSM D DiagResp";
CM_ BO_ 1573 "MRGEN_DiagResp";
CM_ BO_ 1574 "SCAM_DiagReq";
CM_ BO_ 1575 "Diagnostic Response for RCU     ";
CM_ BO_ 1576 "Diagnostic response";
CM_ BO_ 1577 "IDB Diagnostic Response";
CM_ BO_ 1578 "AVAS Diagnostic Responde";
CM_ BO_ 1579 "Diagnostic Response for EPS2     ";
CM_ BO_ 1580 "VCU Diagnostic Responde";
CM_ BO_ 1581 "CPD_2_DiagResp";
CM_ BO_ 1582 "EASC DiagResp";
CM_ BO_ 1583 "CPD DiagResp";
CM_ BO_ 1588 "SRR FR Diagnostic Response";
CM_ BO_ 1589 "SRR FL Diagnostic Response";
CM_ BO_ 1590 "SRR RR Diagnostic Response";
CM_ BO_ 1591 "SRR RL Diagnostic Response";
CM_ BO_ 1592 "ASU Diagnostic Response";
CM_ BO_ 1595 "TRM DiagResp";
CM_ BO_ 1597 "POD DCDC Diagnostic Response";
CM_ BO_ 1598 "POD OBC Diagnostic Response";
CM_ BO_ 1599 "POD Diagnostic Response";
CM_ BO_ 1600 "ADAS DiagResp";
CM_ BO_ 1601 "APM DiagResp";
CM_ BO_ 1602 "SHVU F DiagResp";
CM_ BO_ 1603 "SHVU R DiagResp";
CM_ BO_ 1604 "OCS_P_DiagResp";
CM_ BO_ 1609 "LDM_L DiagResp";
CM_ BO_ 1610 "LDM_R DiagResp";
CM_ BO_ 1624 "BAS DiagResp";
CM_ BO_ 1636 "DCM_APM_DiagResp";
CM_ BO_ 1659 "BCM_BPM Diagnostic Response";
CM_ BO_ 1665 "BCM DiagReq";
CM_ BO_ 1666 "XGW DiagReq";
CM_ BO_ 1668 "MHU DiagReq";
CM_ BO_ 1669 "AMP DiagReq";
CM_ BO_ 1672 "ACM DiagReq";
CM_ BO_ 1673 "CCU DiagReq";
CM_ BO_ 1677 "HUD DiagReq";
CM_ BO_ 1678 "ETG DiagReq";
CM_ BO_ 1679 "Diagnostic Request for YSS     ";
CM_ BO_ 1680 "GS Diagnostic Request";
CM_ BO_ 1681 "ASU gateway Diagnostic Request";
CM_ BO_ 1683 "BMS Diagnostic Request";
CM_ BO_ 1684 "CCUR Diagnostic Request";
CM_ BO_ 1690 "EDS Rear Diagnostic Request";
CM_ BO_ 1691 "EDS Front Diagnostic Request";
CM_ BO_ 1694 "PSM D DiagReq";
CM_ BO_ 1701 "MRGEN_DiagReq";
CM_ BO_ 1702 "SCAM_DiagReq";
CM_ BO_ 1703 "Diagnostic Request for RCU     ";
CM_ BO_ 1704 "Diagnostic request";
CM_ BO_ 1705 "IDB Diagnostic Request";
CM_ BO_ 1706 "AVAS Diagnostic Request";
CM_ BO_ 1707 "Diagnostic Request for EPS2     ";
CM_ BO_ 1708 "VCU Diagnostic Request";
CM_ BO_ 1709 "CPD_2 DiagReqCPD_2_DiagReq";
CM_ BO_ 1710 "EASC DiagReq";
CM_ BO_ 1711 "CPD DiagReq";
CM_ BO_ 1716 "SRR FR Diagnostic Request";
CM_ BO_ 1717 "SRR FL Diagnostic Request";
CM_ BO_ 1718 "SRR RR Diagnostic Request";
CM_ BO_ 1719 "SRR RL Diagnostic Request";
CM_ BO_ 1723 "TRM DiagReq";
CM_ BO_ 1725 "POD DCDC Diagnostic Request";
CM_ BO_ 1726 "POD OBC Diagnostic Request";
CM_ BO_ 1727 "POD Diagnostic Request";
CM_ BO_ 1728 "ADAS DiagReq";
CM_ BO_ 1729 "APM DiagReq";
CM_ BO_ 1730 "SHVU F DiagReq";
CM_ BO_ 1731 "SHVU R DiagReq";
CM_ BO_ 1732 "OCS P DiagReq";
CM_ BO_ 1737 "LDM_L DiagReq";
CM_ BO_ 1738 "LDM_R DiagReq";
CM_ BO_ 1752 "BAS DiagReq";
CM_ BO_ 1764 "DCM APM DiagReq";
CM_ BO_ 1775 "Diagnostic Request for all CAN";
CM_ BO_ 1777 "ASU Diagnostic Request";
CM_ BO_ 1787 "BCM_BPM Diagnostic Request";
CM_ BO_ 1791 "Diagnostic Request for all ECUs";
CM_ BO_ 2033 "ACM Scrapping Diag Req";
CM_ BO_ 2041 "ACM Scrapping Diag Resp";
CM_ SG_ 1537 BCM_DiagRespData0 "Diagnostic signal Data response";
CM_ SG_ 1537 BCM_DiagRespData1 "Remote Diagnostic signal Data response";
CM_ SG_ 1537 BCM_DiagRespData2 "Diagnostic signal Data response";
CM_ SG_ 1537 BCM_DiagRespData3 "Diagnostic signal Data response";
CM_ SG_ 1537 BCM_DiagRespData4 "Diagnostic signal Data response";
CM_ SG_ 1537 BCM_DiagRespData5 "Diagnostic signal Data response";
CM_ SG_ 1537 BCM_DiagRespData6 "Remote Diagnostic signal Data response";
CM_ SG_ 1537 BCM_DiagRespData7 "Diagnostic signal Data response";
CM_ SG_ 1538 XGW_DiagRespData0 "Remote Diagnostic signal Data response";
CM_ SG_ 1538 XGW_DiagRespData1 "Remote Diagnostic signal Data response";
CM_ SG_ 1538 XGW_DiagRespData2 "Remote Diagnostic signal Data response";
CM_ SG_ 1538 XGW_DiagRespData3 "Diagnostic signal Data response";
CM_ SG_ 1538 XGW_DiagRespData4 "Diagnostic signal Data response";
CM_ SG_ 1538 XGW_DiagRespData5 "Remote Diagnostic signal Data response";
CM_ SG_ 1538 XGW_DiagRespData6 "Diagnostic signal Data response";
CM_ SG_ 1538 XGW_DiagRespData7 "Remote Diagnostic signal Data response";
CM_ SG_ 1540 MHU_DiagRespData0 "Diagnostic signal Data response";
CM_ SG_ 1540 MHU_DiagRespData1 "Diagnostic signal Data response";
CM_ SG_ 1540 MHU_DiagRespData2 "Diagnostic signal Data response";
CM_ SG_ 1540 MHU_DiagRespData3 "Diagnostic signal Data response";
CM_ SG_ 1540 MHU_DiagRespData4 "Diagnostic signal Data response";
CM_ SG_ 1540 MHU_DiagRespData5 "Diagnostic signal Data response";
CM_ SG_ 1540 MHU_DiagRespData6 "Diagnostic signal Data response";
CM_ SG_ 1540 MHU_DiagRespData7 "Diagnostic signal Data response";
CM_ SG_ 1541 AMP_DiagRespData0 "Remote Diagnostic signal Data response";
CM_ SG_ 1541 AMP_DiagRespData1 "Remote Diagnostic signal Data response";
CM_ SG_ 1541 AMP_DiagRespData2 "Remote Diagnostic signal Data response";
CM_ SG_ 1541 AMP_DiagRespData3 "Diagnostic signal Data response";
CM_ SG_ 1541 AMP_DiagRespData4 "Remote Diagnostic signal Data response";
CM_ SG_ 1541 AMP_DiagRespData5 "Diagnostic signal Data response";
CM_ SG_ 1541 AMP_DiagRespData6 "Diagnostic signal Data response";
CM_ SG_ 1541 AMP_DiagRespData7 "Remote Diagnostic signal Data response";
CM_ SG_ 1544 ACM_DiagRespData0 "Diagnostic signal Data response";
CM_ SG_ 1544 ACM_DiagRespData1 "Remote Diagnostic signal Data response";
CM_ SG_ 1544 ACM_DiagRespData2 "Diagnostic signal Data response";
CM_ SG_ 1544 ACM_DiagRespData3 "Remote Diagnostic signal Data response";
CM_ SG_ 1544 ACM_DiagRespData4 "Diagnostic signal Data response";
CM_ SG_ 1544 ACM_DiagRespData5 "Remote Diagnostic signal Data response";
CM_ SG_ 1544 ACM_DiagRespData6 "Diagnostic signal Data response";
CM_ SG_ 1544 ACM_DiagRespData7 "Remote Diagnostic signal Data response";
CM_ SG_ 1545 CCUF_DiagRespData0 "Diagnostic signal Data response";
CM_ SG_ 1545 CCUF_DiagRespData1 "Remote Diagnostic signal Data response";
CM_ SG_ 1545 CCUF_DiagRespData2 "Remote Diagnostic signal Data response";
CM_ SG_ 1545 CCUF_DiagRespData3 "Diagnostic signal Data response";
CM_ SG_ 1545 CCUF_DiagRespData4 "Diagnostic signal Data response";
CM_ SG_ 1545 CCUF_DiagRespData5 "Remote Diagnostic signal Data response";
CM_ SG_ 1545 CCUF_DiagRespData6 "Remote Diagnostic signal Data response";
CM_ SG_ 1545 CCUF_DiagRespData7 "Diagnostic signal Data response";
CM_ SG_ 1549 HUD_DiagRespData0 "Diagnostic signal Data response";
CM_ SG_ 1549 HUD_DiagRespData1 "Diagnostic signal Data response";
CM_ SG_ 1549 HUD_DiagRespData2 "Diagnostic signal Data response";
CM_ SG_ 1549 HUD_DiagRespData3 "Diagnostic signal Data response";
CM_ SG_ 1549 HUD_DiagRespData4 "Diagnostic signal Data response";
CM_ SG_ 1549 HUD_DiagRespData5 "Diagnostic signal Data response";
CM_ SG_ 1549 HUD_DiagRespData6 "Diagnostic signal Data response";
CM_ SG_ 1549 HUD_DiagRespData7 "Diagnostic signal Data response";
CM_ SG_ 1550 ETG_DiagRespData0 "Diagnostic signal Data response";
CM_ SG_ 1550 ETG_DiagRespData1 "Diagnostic signal Data response";
CM_ SG_ 1550 ETG_DiagRespData2 "Diagnostic signal Data response";
CM_ SG_ 1550 ETG_DiagRespData3 "Remote Diagnostic signal Data response";
CM_ SG_ 1550 ETG_DiagRespData4 "Diagnostic signal Data response";
CM_ SG_ 1550 ETG_DiagRespData5 "Diagnostic signal Data response";
CM_ SG_ 1550 ETG_DiagRespData6 "Diagnostic signal Data response";
CM_ SG_ 1550 ETG_DiagRespData7 "Diagnostic signal Data response";
CM_ SG_ 1551 YSS_DiagRespData0 "Diagnostic signal Data response";
CM_ SG_ 1551 YSS_DiagRespData1 "Diagnostic signal Data response";
CM_ SG_ 1551 YSS_DiagRespData2 "Diagnostic signal Data response";
CM_ SG_ 1551 YSS_DiagRespData3 "Diagnostic signal Data response";
CM_ SG_ 1551 YSS_DiagRespData4 "Diagnostic signal Data response";
CM_ SG_ 1551 YSS_DiagRespData5 "Diagnostic signal Data response";
CM_ SG_ 1551 YSS_DiagRespData6 "Diagnostic signal Data response";
CM_ SG_ 1551 YSS_DiagRespData7 "Diagnostic signal Data response";
CM_ SG_ 1552 GS_DiagRespData0 "Remote Diagnostic signal Data response";
CM_ SG_ 1552 GS_DiagRespData1 "Diagnostic signal Data response";
CM_ SG_ 1552 GS_DiagRespData2 "Remote Diagnostic signal Data response";
CM_ SG_ 1552 GS_DiagRespData3 "Diagnostic signal Data response";
CM_ SG_ 1552 GS_DiagRespData4 "Diagnostic signal Data response";
CM_ SG_ 1552 GS_DiagRespData5 "Diagnostic signal Data response";
CM_ SG_ 1552 GS_DiagRespData6 "Remote Diagnostic signal Data response";
CM_ SG_ 1552 GS_DiagRespData7 "Diagnostic signal Data response";
CM_ SG_ 1553 ASU_Gateway_DiagRespData0 "Diagnostic signal Data response";
CM_ SG_ 1553 ASU_Gateway_DiagRespData1 "Diagnostic signal Data response";
CM_ SG_ 1553 ASU_Gateway_DiagRespData2 "Diagnostic signal Data response";
CM_ SG_ 1553 ASU_Gateway_DiagRespData3 "Diagnostic signal Data response";
CM_ SG_ 1553 ASU_Gateway_DiagRespData4 "Diagnostic signal Data response";
CM_ SG_ 1553 ASU_Gateway_DiagRespData5 "Diagnostic signal Data response";
CM_ SG_ 1553 ASU_Gateway_DiagRespData6 "Diagnostic signal Data response";
CM_ SG_ 1553 ASU_Gateway_DiagRespData7 "Diagnostic signal Data response";
CM_ SG_ 1555 BMS_DiagRespData0 "Diagnostic signal Data response";
CM_ SG_ 1555 BMS_DiagRespData1 "Diagnostic signal Data response";
CM_ SG_ 1555 BMS_DiagRespData2 "Diagnostic signal Data response";
CM_ SG_ 1555 BMS_DiagRespData3 "Diagnostic signal Data response";
CM_ SG_ 1555 BMS_DiagRespData4 "Diagnostic signal Data response";
CM_ SG_ 1555 BMS_DiagRespData5 "Diagnostic signal Data response";
CM_ SG_ 1555 BMS_DiagRespData6 "Diagnostic signal Data response";
CM_ SG_ 1555 BMS_DiagRespData7 "Remote Diagnostic signal Data response";
CM_ SG_ 1556 CCUR_DiagRespData0 "Diagnostic signal Data response";
CM_ SG_ 1556 CCUR_DiagRespData1 "Diagnostic signal Data response";
CM_ SG_ 1556 CCUR_DiagRespData2 "Diagnostic signal Data response";
CM_ SG_ 1556 CCUR_DiagRespData3 "Diagnostic signal Data response";
CM_ SG_ 1556 CCUR_DiagRespData4 "Remote Diagnostic signal Data response";
CM_ SG_ 1556 CCUR_DiagRespData5 "Diagnostic signal Data response";
CM_ SG_ 1556 CCUR_DiagRespData6 "Remote Diagnostic signal Data response";
CM_ SG_ 1556 CCUR_DiagRespData7 "Diagnostic signal Data response";
CM_ SG_ 1562 EDS_R_DiagRespData0 "Diagnostic signal Data response";
CM_ SG_ 1562 EDS_R_DiagRespData1 "Diagnostic signal Data response";
CM_ SG_ 1562 EDS_R_DiagRespData2 "Remote Diagnostic signal Data response";
CM_ SG_ 1562 EDS_R_DiagRespData3 "Diagnostic signal Data response";
CM_ SG_ 1562 EDS_R_DiagRespData4 "Diagnostic signal Data response";
CM_ SG_ 1562 EDS_R_DiagRespData5 "Remote Diagnostic signal Data response";
CM_ SG_ 1562 EDS_R_DiagRespData6 "Remote Diagnostic signal Data response";
CM_ SG_ 1562 EDS_R_DiagRespData7 "Remote Diagnostic signal Data response";
CM_ SG_ 1563 EDS_F_DiagRespData0 "Diagnostic signal Data response";
CM_ SG_ 1563 EDS_F_DiagRespData1 "Diagnostic signal Data response";
CM_ SG_ 1563 EDS_F_DiagRespData2 "Remote Diagnostic signal Data response";
CM_ SG_ 1563 EDS_F_DiagRespData3 "Diagnostic signal Data response";
CM_ SG_ 1563 EDS_F_DiagRespData4 "Diagnostic signal Data response";
CM_ SG_ 1563 EDS_F_DiagRespData5 "Diagnostic signal Data response";
CM_ SG_ 1563 EDS_F_DiagRespData6 "Remote Diagnostic signal Data response";
CM_ SG_ 1563 EDS_F_DiagRespData7 "Diagnostic signal Data response";
CM_ SG_ 1566 PSM_D_DiagRespData0 "Diagnostic signal Data response";
CM_ SG_ 1566 PSM_D_DiagRespData1 "Diagnostic signal Data response";
CM_ SG_ 1566 PSM_D_DiagRespData2 "Diagnostic signal Data response";
CM_ SG_ 1566 PSM_D_DiagRespData3 "Remote Diagnostic signal Data response";
CM_ SG_ 1566 PSM_D_DiagRespData4 "Diagnostic signal Data response";
CM_ SG_ 1566 PSM_D_DiagRespData5 "Diagnostic signal Data response";
CM_ SG_ 1566 PSM_D_DiagRespData6 "Diagnostic signal Data response";
CM_ SG_ 1566 PSM_D_DiagRespData7 "Diagnostic signal Data response";
CM_ SG_ 1573 MRGEN_DiagRespData0 "Diagnostic signal Data response";
CM_ SG_ 1573 MRGEN_DiagRespData1 "Remote Diagnostic signal Data response
";
CM_ SG_ 1573 MRGEN_DiagRespData2 "Diagnostic signal Data response";
CM_ SG_ 1573 MRGEN_DiagRespData3 "Diagnostic signal Data response";
CM_ SG_ 1573 MRGEN_DiagRespData4 "Diagnostic signal Data response";
CM_ SG_ 1573 MRGEN_DiagRespData5 "Diagnostic signal Data response";
CM_ SG_ 1573 MRGEN_DiagRespData6 "Diagnostic signal Data response";
CM_ SG_ 1573 MRGEN_DiagRespData7 "Remote Diagnostic signal Data response
";
CM_ SG_ 1574 SCAM_DiagRespData0 "Diagnostic signal Data response";
CM_ SG_ 1574 SCAM_DiagRespData1 "Diagnostic signal Data response";
CM_ SG_ 1574 SCAM_DiagRespData2 "Diagnostic signal Data response";
CM_ SG_ 1574 SCAM_DiagRespData3 "Diagnostic signal Data response";
CM_ SG_ 1574 SCAM_DiagRespData4 "Diagnostic signal Data response";
CM_ SG_ 1574 SCAM_DiagRespData5 "Remote Diagnostic signal Data response";
CM_ SG_ 1574 SCAM_DiagRespData6 "Diagnostic signal Data response";
CM_ SG_ 1574 SCAM_DiagRespData7 "Diagnostic signal Data response";
CM_ SG_ 1575 RCU_DiagRespData0 "Diagnostic signal Data response";
CM_ SG_ 1575 RCU_DiagRespData1 "Diagnostic signal Data response";
CM_ SG_ 1575 RCU_DiagRespData2 "Diagnostic signal Data response";
CM_ SG_ 1575 RCU_DiagRespData3 "Diagnostic signal Data response";
CM_ SG_ 1575 RCU_DiagRespData4 "Diagnostic signal Data response";
CM_ SG_ 1575 RCU_DiagRespData5 "Diagnostic signal Data response...";
CM_ SG_ 1575 RCU_DiagRespData6 "Diagnostic signal Data response";
CM_ SG_ 1575 RCU_DiagRespData7 "Diagnostic signal Data response...";
CM_ SG_ 1576 EPS_DiagRespData0 "Remote Diagnostic signal Data response";
CM_ SG_ 1576 EPS_DiagRespData1 "Diagnostic signal Data response";
CM_ SG_ 1576 EPS_DiagRespData2 "Diagnostic signal Data response";
CM_ SG_ 1576 EPS_DiagRespData3 "Remote Diagnostic signal Data response";
CM_ SG_ 1576 EPS_DiagRespData4 "Diagnostic signal Data response";
CM_ SG_ 1576 EPS_DiagRespData5 "Diagnostic signal Data response";
CM_ SG_ 1576 EPS_DiagRespData6 "Remote Diagnostic signal Data response";
CM_ SG_ 1576 EPS_DiagRespData7 "Remote Diagnostic signal Data response";
CM_ SG_ 1577 IDB_DiagRespData0 "Diagnostic signal Data response";
CM_ SG_ 1577 IDB_DiagRespData1 "Remote Diagnostic signal Data response";
CM_ SG_ 1577 IDB_DiagRespData2 "Remote Diagnostic signal Data response";
CM_ SG_ 1577 IDB_DiagRespData3 "Diagnostic signal Data response";
CM_ SG_ 1577 IDB_DiagRespData4 "Diagnostic signal Data response";
CM_ SG_ 1577 IDB_DiagRespData5 "Remote Diagnostic signal Data response";
CM_ SG_ 1577 IDB_DiagRespData6 "Remote Diagnostic signal Data response";
CM_ SG_ 1577 IDB_DiagRespData7 "Diagnostic signal Data response";
CM_ SG_ 1578 AVAS_DiagRespData0 "Diagnostic signal Data response";
CM_ SG_ 1578 AVAS_DiagRespData1 "Diagnostic signal Data response";
CM_ SG_ 1578 AVAS_DiagRespData2 "Diagnostic signal Data response";
CM_ SG_ 1578 AVAS_DiagRespData3 "Diagnostic signal Data response";
CM_ SG_ 1578 AVAS_DiagRespData4 "Diagnostic signal Data response";
CM_ SG_ 1578 AVAS_DiagRespData5 "Diagnostic signal Data response";
CM_ SG_ 1578 AVAS_DiagRespData6 "Diagnostic signal Data response";
CM_ SG_ 1578 AVAS_DiagRespData7 "Remote Diagnostic signal Data response";
CM_ SG_ 1579 EPS2_DiagRespData0 "Diagnostic signal Data response...";
CM_ SG_ 1579 EPS2_DiagRespData1 "Remote Diagnostic signal Data response";
CM_ SG_ 1579 EPS2_DiagRespData2 "Remote Diagnostic signal Data response";
CM_ SG_ 1579 EPS2_DiagRespData3 "Diagnostic signal Data response";
CM_ SG_ 1579 EPS2_DiagRespData4 "Remote Diagnostic signal Data response";
CM_ SG_ 1579 EPS2_DiagRespData5 "Diagnostic signal Data response";
CM_ SG_ 1579 EPS2_DiagRespData6 "Remote Diagnostic signal Data response";
CM_ SG_ 1579 EPS2_DiagRespData7 "Remote Diagnostic signal Data response";
CM_ SG_ 1580 VCU_DiagRespData0 "Diagnostic signal Data response";
CM_ SG_ 1580 VCU_DiagRespData1 "Diagnostic signal Data response";
CM_ SG_ 1580 VCU_DiagRespData2 "Diagnostic signal Data response";
CM_ SG_ 1580 VCU_DiagRespData3 "Diagnostic signal Data response";
CM_ SG_ 1580 VCU_DiagRespData4 "Remote Diagnostic signal Data response";
CM_ SG_ 1580 VCU_DiagRespData5 "Diagnostic signal Data response";
CM_ SG_ 1580 VCU_DiagRespData6 "Diagnostic signal Data response";
CM_ SG_ 1580 VCU_DiagRespData7 "Remote Diagnostic signal Data response";
CM_ SG_ 1581 CPD_2_DiagRespData0 "Diagnostic signal Data response";
CM_ SG_ 1581 CPD_2_DiagRespData1 "Diagnostic signal Data response";
CM_ SG_ 1581 CPD_2_DiagRespData2 "Diagnostic signal Data response";
CM_ SG_ 1581 CPD_2_DiagRespData3 "Diagnostic signal Data response";
CM_ SG_ 1581 CPD_2_DiagRespData4 "Diagnostic signal Data response";
CM_ SG_ 1581 CPD_2_DiagRespData5 "Diagnostic signal Data response";
CM_ SG_ 1581 CPD_2_DiagRespData6 "Diagnostic signal Data response";
CM_ SG_ 1581 CPD_2_DiagRespData7 "Diagnostic signal Data response";
CM_ SG_ 1582 EASC_DiagRespData0 "Remote Diagnostic signal Data response";
CM_ SG_ 1582 EASC_DiagRespData1 "Remote Diagnostic signal Data response";
CM_ SG_ 1582 EASC_DiagRespData2 "Remote Diagnostic signal Data response";
CM_ SG_ 1582 EASC_DiagRespData3 "Remote Diagnostic signal Data response";
CM_ SG_ 1582 EASC_DiagRespData4 "Remote Diagnostic signal Data response";
CM_ SG_ 1582 EASC_DiagRespData5 "Remote Diagnostic signal Data response";
CM_ SG_ 1582 EASC_DiagRespData6 "Remote Diagnostic signal Data response";
CM_ SG_ 1582 EASC_DiagRespData7 "Remote Diagnostic signal Data response";
CM_ SG_ 1583 CPD_DiagRespData0 "Diagnostic signal Data response";
CM_ SG_ 1583 CPD_DiagRespData1 "Diagnostic signal Data response";
CM_ SG_ 1583 CPD_DiagRespData2 "Diagnostic signal Data response";
CM_ SG_ 1583 CPD_DiagRespData3 "Diagnostic signal Data response";
CM_ SG_ 1583 CPD_DiagRespData4 "Diagnostic signal Data response";
CM_ SG_ 1583 CPD_DiagRespData5 "Diagnostic signal Data response";
CM_ SG_ 1583 CPD_DiagRespData6 "Diagnostic signal Data response";
CM_ SG_ 1583 CPD_DiagRespData7 "Diagnostic signal Data response";
CM_ SG_ 1588 SRR_FR_DiagRespData0 "SRR_Diagnostic Response";
CM_ SG_ 1588 SRR_FR_DiagRespData1 "SRR_Diagnostic Response";
CM_ SG_ 1588 SRR_FR_DiagRespData2 "SRR_Diagnostic Response";
CM_ SG_ 1588 SRR_FR_DiagRespData3 "SRR_Diagnostic Response";
CM_ SG_ 1588 SRR_FR_DiagRespData4 "SRR_Diagnostic Response";
CM_ SG_ 1588 SRR_FR_DiagRespData5 "SRR_Diagnostic Response";
CM_ SG_ 1588 SRR_FR_DiagRespData6 "SRR_Diagnostic Response";
CM_ SG_ 1588 SRR_FR_DiagRespData7 "SRR_Diagnostic Response";
CM_ SG_ 1589 SRR_FL_DiagRespData0 "SRR_Diagnostic Response";
CM_ SG_ 1589 SRR_FL_DiagRespData1 "SRR_Diagnostic Response";
CM_ SG_ 1589 SRR_FL_DiagRespData2 "SRR_Diagnostic Response";
CM_ SG_ 1589 SRR_FL_DiagRespData3 "SRR_Diagnostic Response";
CM_ SG_ 1589 SRR_FL_DiagRespData4 "SRR_Diagnostic Response";
CM_ SG_ 1589 SRR_FL_DiagRespData5 "SRR_Diagnostic Response";
CM_ SG_ 1589 SRR_FL_DiagRespData6 "SRR_Diagnostic Response";
CM_ SG_ 1589 SRR_FL_DiagRespData7 "SRR_Diagnostic Response";
CM_ SG_ 1590 SRR_RR_DiagRespData0 "SRR_Diagnostic Response";
CM_ SG_ 1590 SRR_RR_DiagRespData1 "SRR_Diagnostic Response";
CM_ SG_ 1590 SRR_RR_DiagRespData2 "SRR_Diagnostic Response";
CM_ SG_ 1590 SRR_RR_DiagRespData3 "SRR_Diagnostic Response";
CM_ SG_ 1590 SRR_RR_DiagRespData4 "SRR_Diagnostic Response";
CM_ SG_ 1590 SRR_RR_DiagRespData5 "SRR_Diagnostic Response";
CM_ SG_ 1590 SRR_RR_DiagRespData6 "SRR_Diagnostic Response";
CM_ SG_ 1590 SRR_RR_DiagRespData7 "SRR_Diagnostic Response";
CM_ SG_ 1591 SRR_RL_DiagRespData0 "SRR_Diagnostic Response";
CM_ SG_ 1591 SRR_RL_DiagRespData1 "SRR_Diagnostic Response";
CM_ SG_ 1591 SRR_RL_DiagRespData2 "SRR_Diagnostic Response";
CM_ SG_ 1591 SRR_RL_DiagRespData3 "SRR_Diagnostic Response";
CM_ SG_ 1591 SRR_RL_DiagRespData4 "SRR_Diagnostic Response";
CM_ SG_ 1591 SRR_RL_DiagRespData5 "SRR_Diagnostic Response";
CM_ SG_ 1591 SRR_RL_DiagRespData6 "SRR_Diagnostic Response";
CM_ SG_ 1591 SRR_RL_DiagRespData7 "SRR_Diagnostic Response";
CM_ SG_ 1592 ASU_DiagRespData0 "Diagnostic signal Data response";
CM_ SG_ 1592 ASU_DiagRespData1 "Diagnostic signal Data response";
CM_ SG_ 1592 ASU_DiagRespData2 "Diagnostic signal Data response";
CM_ SG_ 1592 ASU_DiagRespData3 "Diagnostic signal Data response";
CM_ SG_ 1592 ASU_DiagRespData4 "Diagnostic signal Data response";
CM_ SG_ 1592 ASU_DiagRespData5 "Diagnostic signal Data response";
CM_ SG_ 1592 ASU_DiagRespData6 "Diagnostic signal Data response";
CM_ SG_ 1592 ASU_DiagRespData7 "Diagnostic signal Data response";
CM_ SG_ 1595 TRM_DiagRespData0 "Diagnostic signal Data response";
CM_ SG_ 1595 TRM_DiagRespData1 "Diagnostic signal Data response";
CM_ SG_ 1595 TRM_DiagRespData2 "Diagnostic signal Data response";
CM_ SG_ 1595 TRM_DiagRespData3 "Remote Diagnostic signal Data response
";
CM_ SG_ 1595 TRM_DiagRespData4 "Remote Diagnostic signal Data response
";
CM_ SG_ 1595 TRM_DiagRespData5 "Remote Diagnostic signal Data response
";
CM_ SG_ 1595 TRM_DiagRespData6 "Diagnostic signal Data response";
CM_ SG_ 1595 TRM_DiagRespData7 "Remote Diagnostic signal Data response
";
CM_ SG_ 1597 POD_DCDC_DiagRespData0 "Diagnostic signal Data response";
CM_ SG_ 1597 POD_DCDC_DiagRespData1 "Diagnostic signal Data response";
CM_ SG_ 1597 POD_DCDC_DiagRespData2 "Remote Diagnostic signal Data response";
CM_ SG_ 1597 POD_DCDC_DiagRespData3 "Remote Diagnostic signal Data response";
CM_ SG_ 1597 POD_DCDC_DiagRespData4 "Diagnostic signal Data response";
CM_ SG_ 1597 POD_DCDC_DiagRespData5 "Diagnostic signal Data response";
CM_ SG_ 1597 POD_DCDC_DiagRespData6 "Remote Diagnostic signal Data response";
CM_ SG_ 1597 POD_DCDC_DiagRespData7 "Diagnostic signal Data response";
CM_ SG_ 1598 POD_OBC_DiagRespData0 "Diagnostic signal Data response";
CM_ SG_ 1598 POD_OBC_DiagRespData1 "Remote Diagnostic signal Data response";
CM_ SG_ 1598 POD_OBC_DiagRespData2 "Diagnostic signal Data response";
CM_ SG_ 1598 POD_OBC_DiagRespData3 "Remote Diagnostic signal Data response";
CM_ SG_ 1598 POD_OBC_DiagRespData4 "Diagnostic signal Data response";
CM_ SG_ 1598 POD_OBC_DiagRespData5 "Remote Diagnostic signal Data response";
CM_ SG_ 1598 POD_OBC_DiagRespData6 "Diagnostic signal Data response";
CM_ SG_ 1598 POD_OBC_DiagRespData7 "Remote Diagnostic signal Data response";
CM_ SG_ 1599 POD_DiagRespData0 "Diagnostic signal Data response";
CM_ SG_ 1599 POD_DiagRespData1 "Diagnostic signal Data response";
CM_ SG_ 1599 POD_DiagRespData2 "Diagnostic signal Data response";
CM_ SG_ 1599 POD_DiagRespData3 "Diagnostic signal Data response";
CM_ SG_ 1599 POD_DiagRespData4 "Diagnostic signal Data response";
CM_ SG_ 1599 POD_DiagRespData5 "Diagnostic signal Data response";
CM_ SG_ 1599 POD_DiagRespData6 "Diagnostic signal Data response";
CM_ SG_ 1599 POD_DiagRespData7 "Diagnostic signal Data response";
CM_ SG_ 1600 ADAS_DiagRespData0 "Diagnostic signal Data response";
CM_ SG_ 1600 ADAS_DiagRespData1 "Diagnostic signal Data response";
CM_ SG_ 1600 ADAS_DiagRespData2 "Diagnostic signal Data response";
CM_ SG_ 1600 ADAS_DiagRespData3 "Diagnostic signal Data response";
CM_ SG_ 1600 ADAS_DiagRespData4 "Diagnostic signal Data response";
CM_ SG_ 1600 ADAS_DiagRespData5 "Diagnostic signal Data response";
CM_ SG_ 1600 ADAS_DiagRespData6 "Diagnostic signal Data response";
CM_ SG_ 1600 ADAS_DiagRespData7 "Diagnostic signal Data response";
CM_ SG_ 1601 APM_DiagRespData0 "Diagnostic signal Data response";
CM_ SG_ 1601 APM_DiagRespData1 "Diagnostic signal Data response";
CM_ SG_ 1601 APM_DiagRespData2 "Diagnostic signal Data response";
CM_ SG_ 1601 APM_DiagRespData3 "Diagnostic signal Data response";
CM_ SG_ 1601 APM_DiagRespData4 "Remote Diagnostic signal Data response";
CM_ SG_ 1601 APM_DiagRespData5 "Diagnostic signal Data response";
CM_ SG_ 1601 APM_DiagRespData6 "Remote Diagnostic signal Data response";
CM_ SG_ 1601 APM_DiagRespData7 "Diagnostic signal Data response";
CM_ SG_ 1602 SHVU_F_DiagRespData0 "Diagnostic signal Data response";
CM_ SG_ 1602 SHVU_F_DiagRespData1 "Diagnostic signal Data response";
CM_ SG_ 1602 SHVU_F_DiagRespData2 "Remote Diagnostic signal Data response";
CM_ SG_ 1602 SHVU_F_DiagRespData3 "Diagnostic signal Data response";
CM_ SG_ 1602 SHVU_F_DiagRespData4 "Diagnostic signal Data response";
CM_ SG_ 1602 SHVU_F_DiagRespData5 "Diagnostic signal Data response";
CM_ SG_ 1602 SHVU_F_DiagRespData6 "Remote Diagnostic signal Data response";
CM_ SG_ 1602 SHVU_F_DiagRespData7 "Diagnostic signal Data response";
CM_ SG_ 1603 SHVU_R_DiagRespData0 "Diagnostic signal Data response";
CM_ SG_ 1603 SHVU_R_DiagRespData1 "Remote Diagnostic signal Data response";
CM_ SG_ 1603 SHVU_R_DiagRespData2 "Diagnostic signal Data response";
CM_ SG_ 1603 SHVU_R_DiagRespData3 "Remote Diagnostic signal Data response";
CM_ SG_ 1603 SHVU_R_DiagRespData4 "Remote Diagnostic signal Data response";
CM_ SG_ 1603 SHVU_R_DiagRespData5 "Diagnostic signal Data response";
CM_ SG_ 1603 SHVU_R_DiagRespData6 "Remote Diagnostic signal Data response";
CM_ SG_ 1603 SHVU_R_DiagRespData7 "Diagnostic signal Data response";
CM_ SG_ 1604 OCS_P_DiagRespData0 "Diagnostic signal Data response";
CM_ SG_ 1604 OCS_P_DiagRespData1 "Remote Diagnostic signal Data response";
CM_ SG_ 1604 OCS_P_DiagRespData2 "Diagnostic signal Data response";
CM_ SG_ 1604 OCS_P_DiagRespData3 "Remote Diagnostic signal Data response";
CM_ SG_ 1604 OCS_P_DiagRespData4 "Diagnostic signal Data response";
CM_ SG_ 1604 OCS_P_DiagRespData5 "Diagnostic signal Data response";
CM_ SG_ 1604 OCS_P_DiagRespData6 "Diagnostic signal Data response";
CM_ SG_ 1604 OCS_P_DiagRespData7 "Diagnostic signal Data response";
CM_ SG_ 1609 LDM_L_DiagRespData0 "Remote Diagnostic signal Data response
";
CM_ SG_ 1609 LDM_L_DiagRespData1 "Diagnostic signal Data response";
CM_ SG_ 1609 LDM_L_DiagRespData2 "Remote Diagnostic signal Data response
";
CM_ SG_ 1609 LDM_L_DiagRespData3 "Diagnostic signal Data response";
CM_ SG_ 1609 LDM_L_DiagRespData4 "Diagnostic signal Data response";
CM_ SG_ 1609 LDM_L_DiagRespData5 "Remote Diagnostic signal Data response
";
CM_ SG_ 1609 LDM_L_DiagRespData6 "Diagnostic signal Data response";
CM_ SG_ 1609 LDM_L_DiagRespData7 "Remote Diagnostic signal Data response
";
CM_ SG_ 1610 LDM_R_DiagRespData0 "Diagnostic signal Data response";
CM_ SG_ 1610 LDM_R_DiagRespData1 "Remote Diagnostic signal Data response
";
CM_ SG_ 1610 LDM_R_DiagRespData2 "Diagnostic signal Data response";
CM_ SG_ 1610 LDM_R_DiagRespData3 "Diagnostic signal Data response";
CM_ SG_ 1610 LDM_R_DiagRespData4 "Remote Diagnostic signal Data response
";
CM_ SG_ 1610 LDM_R_DiagRespData5 "Diagnostic signal Data response";
CM_ SG_ 1610 LDM_R_DiagRespData6 "Diagnostic signal Data response";
CM_ SG_ 1610 LDM_R_DiagRespData7 "Remote Diagnostic signal Data response
";
CM_ SG_ 1624 BAS_DiagRespData0 "Diagnostic signal Data response";
CM_ SG_ 1624 BAS_DiagRespData1 "Diagnostic signal Data response";
CM_ SG_ 1624 BAS_DiagRespData2 "Diagnostic signal Data response";
CM_ SG_ 1624 BAS_DiagRespData3 "Diagnostic signal Data response";
CM_ SG_ 1624 BAS_DiagRespData4 "Diagnostic signal Data response";
CM_ SG_ 1624 BAS_DiagRespData5 "Diagnostic signal Data response";
CM_ SG_ 1624 BAS_DiagRespData6 "Diagnostic signal Data response";
CM_ SG_ 1624 BAS_DiagRespData7 "Diagnostic signal Data response";
CM_ SG_ 1636 DCM_APM_DiagRespData0 "Remote Diagnostic signal Data response
";
CM_ SG_ 1636 DCM_APM_DiagRespData1 "Remote Diagnostic signal Data response
";
CM_ SG_ 1636 DCM_APM_DiagRespData2 "Diagnostic signal Data response";
CM_ SG_ 1636 DCM_APM_DiagRespData3 "Remote Diagnostic signal Data response
";
CM_ SG_ 1636 DCM_APM_DiagRespData4 "Diagnostic signal Data response";
CM_ SG_ 1636 DCM_APM_DiagRespData5 "Remote Diagnostic signal Data response
";
CM_ SG_ 1636 DCM_APM_DiagRespData6 "Remote Diagnostic signal Data response
";
CM_ SG_ 1636 DCM_APM_DiagRespData7 "Diagnostic signal Data response";
CM_ SG_ 1659 BCM_BPM_DiagRespData0 "Diagnostic signal Data response";
CM_ SG_ 1659 BCM_BPM_DiagRespData1 "Diagnostic signal Data response";
CM_ SG_ 1659 BCM_BPM_DiagRespData2 "Diagnostic signal Data response";
CM_ SG_ 1659 BCM_BPM_DiagRespData3 "Diagnostic signal Data response";
CM_ SG_ 1659 BCM_BPM_DiagRespData4 "Diagnostic signal Data response";
CM_ SG_ 1659 BCM_BPM_DiagRespData5 "Diagnostic signal Data response";
CM_ SG_ 1659 BCM_BPM_DiagRespData6 "Diagnostic signal Data response";
CM_ SG_ 1659 BCM_BPM_DiagRespData7 "Diagnostic signal Data response";
CM_ SG_ 1665 BCM_DiagReqData0 "Diagnostic signal Data request";
CM_ SG_ 1665 BCM_DiagReqData1 "Diagnostic signal Data request";
CM_ SG_ 1665 BCM_DiagReqData2 "Diagnostic signal Data request";
CM_ SG_ 1665 BCM_DiagReqData3 "Diagnostic signal Data request";
CM_ SG_ 1665 BCM_DiagReqData4 "Diagnostic signal Data request";
CM_ SG_ 1665 BCM_DiagReqData5 "Diagnostic signal Data request";
CM_ SG_ 1665 BCM_DiagReqData6 "Remote Diagnostic signal Data request";
CM_ SG_ 1665 BCM_DiagReqData7 "Remote Diagnostic signal Data request";
CM_ SG_ 1666 XGW_DiagReqData0 "Diagnostic signal Data request";
CM_ SG_ 1666 XGW_DiagReqData1 "Diagnostic signal Data request";
CM_ SG_ 1666 XGW_DiagReqData2 "Remote Diagnostic signal Data request";
CM_ SG_ 1666 XGW_DiagReqData3 "Remote Diagnostic signal Data request";
CM_ SG_ 1666 XGW_DiagReqData4 "Diagnostic signal Data request";
CM_ SG_ 1666 XGW_DiagReqData5 "Diagnostic signal Data request";
CM_ SG_ 1666 XGW_DiagReqData6 "Diagnostic signal Data request";
CM_ SG_ 1666 XGW_DiagReqData7 "Diagnostic signal Data request";
CM_ SG_ 1668 MHU_DiagReqData0 "Diagnostic signal Data request";
CM_ SG_ 1668 MHU_DiagReqData1 "Diagnostic signal Data request";
CM_ SG_ 1668 MHU_DiagReqData2 "Diagnostic signal Data request";
CM_ SG_ 1668 MHU_DiagReqData3 "Diagnostic signal Data request";
CM_ SG_ 1668 MHU_DiagReqData4 "Diagnostic signal Data request";
CM_ SG_ 1668 MHU_DiagReqData5 "Diagnostic signal Data request";
CM_ SG_ 1668 MHU_DiagReqData6 "Diagnostic signal Data request";
CM_ SG_ 1668 MHU_DiagReqData7 "Diagnostic signal Data request";
CM_ SG_ 1669 AMP_DiagReqData0 "Diagnostic signal Data request";
CM_ SG_ 1669 AMP_DiagReqData1 "Remote Diagnostic signal Data request";
CM_ SG_ 1669 AMP_DiagReqData2 "Diagnostic signal Data request";
CM_ SG_ 1669 AMP_DiagReqData3 "Diagnostic signal Data request";
CM_ SG_ 1669 AMP_DiagReqData4 "Diagnostic signal Data request";
CM_ SG_ 1669 AMP_DiagReqData5 "Remote Diagnostic signal Data request";
CM_ SG_ 1669 AMP_DiagReqData6 "Remote Diagnostic signal Data request";
CM_ SG_ 1669 AMP_DiagReqData7 "Diagnostic signal Data request";
CM_ SG_ 1672 ACM_DiagReqData0 "Diagnostic signal Data request";
CM_ SG_ 1672 ACM_DiagReqData1 "Diagnostic signal Data request";
CM_ SG_ 1672 ACM_DiagReqData2 "Diagnostic signal Data request";
CM_ SG_ 1672 ACM_DiagReqData3 "Remote Diagnostic signal Data request";
CM_ SG_ 1672 ACM_DiagReqData4 "Diagnostic signal Data request";
CM_ SG_ 1672 ACM_DiagReqData5 "Diagnostic signal Data request";
CM_ SG_ 1672 ACM_DiagReqData6 "Remote Diagnostic signal Data request";
CM_ SG_ 1672 ACM_DiagReqData7 "Diagnostic signal Data request";
CM_ SG_ 1673 CCUF_DiagReqData0 "Remote Diagnostic signal Data request";
CM_ SG_ 1673 CCUF_DiagReqData1 "Diagnostic signal Data request";
CM_ SG_ 1673 CCUF_DiagReqData2 "Diagnostic signal Data request";
CM_ SG_ 1673 CCUF_DiagReqData3 "Diagnostic signal Data request";
CM_ SG_ 1673 CCUF_DiagReqData4 "Diagnostic signal Data request";
CM_ SG_ 1673 CCUF_DiagReqData5 "Diagnostic signal Data request";
CM_ SG_ 1673 CCUF_DiagReqData6 "Diagnostic signal Data request";
CM_ SG_ 1673 CCUF_DiagReqData7 "Diagnostic signal Data request";
CM_ SG_ 1677 HUD_DiagReqData0 "Diagnostic signal Data request";
CM_ SG_ 1677 HUD_DiagReqData1 "Diagnostic signal Data request";
CM_ SG_ 1677 HUD_DiagReqData2 "Diagnostic signal Data request";
CM_ SG_ 1677 HUD_DiagReqData3 "Diagnostic signal Data request";
CM_ SG_ 1677 HUD_DiagReqData4 "Diagnostic signal Data request";
CM_ SG_ 1677 HUD_DiagReqData5 "Diagnostic signal Data request";
CM_ SG_ 1677 HUD_DiagReqData6 "Diagnostic signal Data request";
CM_ SG_ 1677 HUD_DiagReqData7 "Diagnostic signal Data request";
CM_ SG_ 1678 ETG_DiagReqData0 "Diagnostic signal Data request";
CM_ SG_ 1678 ETG_DiagReqData1 "Diagnostic signal Data request";
CM_ SG_ 1678 ETG_DiagReqData2 "Diagnostic signal Data request";
CM_ SG_ 1678 ETG_DiagReqData3 "Diagnostic signal Data request";
CM_ SG_ 1678 ETG_DiagReqData4 "Diagnostic signal Data request";
CM_ SG_ 1678 ETG_DiagReqData5 "Diagnostic signal Data request";
CM_ SG_ 1678 ETG_DiagReqData6 "Diagnostic signal Data request";
CM_ SG_ 1678 ETG_DiagReqData7 "Remote Diagnostic signal Data request";
CM_ SG_ 1679 YSS_DiagReqData0 "Diagnostic signal Data request";
CM_ SG_ 1679 YSS_DiagReqData1 "Diagnostic signal Data request";
CM_ SG_ 1679 YSS_DiagReqData2 "Diagnostic signal Data request";
CM_ SG_ 1679 YSS_DiagReqData3 "Diagnostic signal Data request";
CM_ SG_ 1679 YSS_DiagReqData4 "Remote Diagnostic signal Data request";
CM_ SG_ 1679 YSS_DiagReqData5 "Diagnostic signal Data request";
CM_ SG_ 1679 YSS_DiagReqData6 "Diagnostic signal Data request";
CM_ SG_ 1679 YSS_DiagReqData7 "Diagnostic signal Data request";
CM_ SG_ 1680 GS_DiagReqData0 "Diagnostic signal Data request";
CM_ SG_ 1680 GS_DiagReqData1 "Diagnostic signal Data request";
CM_ SG_ 1680 GS_DiagReqData2 "Diagnostic signal Data request";
CM_ SG_ 1680 GS_DiagReqData3 "Diagnostic signal Data request";
CM_ SG_ 1680 GS_DiagReqData4 "Remote Diagnostic signal Data request";
CM_ SG_ 1680 GS_DiagReqData5 "Diagnostic signal Data request";
CM_ SG_ 1680 GS_DiagReqData6 "Diagnostic signal Data request";
CM_ SG_ 1680 GS_DiagReqData7 "Diagnostic signal Data request";
CM_ SG_ 1681 ASU_Gateway_DiagReqData0 "Diagnostic signal Data request";
CM_ SG_ 1681 ASU_Gateway_DiagReqData1 "Diagnostic signal Data request";
CM_ SG_ 1681 ASU_Gateway_DiagReqData2 "Diagnostic signal Data request";
CM_ SG_ 1681 ASU_Gateway_DiagReqData3 "Diagnostic signal Data request";
CM_ SG_ 1681 ASU_Gateway_DiagReqData4 "Diagnostic signal Data request";
CM_ SG_ 1681 ASU_Gateway_DiagReqData5 "Diagnostic signal Data request";
CM_ SG_ 1681 ASU_Gateway_DiagReqData6 "Diagnostic signal Data request";
CM_ SG_ 1681 ASU_Gateway_DiagReqData7 "Diagnostic signal Data request";
CM_ SG_ 1683 BMS_DiagReqData0 "Diagnostic signal Data request";
CM_ SG_ 1683 BMS_DiagReqData1 "Diagnostic signal Data request";
CM_ SG_ 1683 BMS_DiagReqData2 "Diagnostic signal Data request";
CM_ SG_ 1683 BMS_DiagReqData3 "Remote Diagnostic signal Data request";
CM_ SG_ 1683 BMS_DiagReqData4 "Remote Diagnostic signal Data request";
CM_ SG_ 1683 BMS_DiagReqData5 "Remote Diagnostic signal Data request";
CM_ SG_ 1683 BMS_DiagReqData6 "Diagnostic signal Data request";
CM_ SG_ 1683 BMS_DiagReqData7 "Diagnostic signal Data request";
CM_ SG_ 1684 CCUR_DiagReqData0 "Diagnostic signal Data request";
CM_ SG_ 1684 CCUR_DiagReqData1 "Diagnostic signal Data request";
CM_ SG_ 1684 CCUR_DiagReqData2 "Diagnostic signal Data request";
CM_ SG_ 1684 CCUR_DiagReqData3 "Remote Diagnostic signal Data request";
CM_ SG_ 1684 CCUR_DiagReqData4 "Remote Diagnostic signal Data request";
CM_ SG_ 1684 CCUR_DiagReqData5 "Diagnostic signal Data request";
CM_ SG_ 1684 CCUR_DiagReqData6 "Diagnostic signal Data request";
CM_ SG_ 1684 CCUR_DiagReqData7 "Diagnostic signal Data request";
CM_ SG_ 1690 EDS_R_DiagReqData0 "Diagnostic signal Data request";
CM_ SG_ 1690 EDS_R_DiagReqData1 "Remote Diagnostic signal Data request";
CM_ SG_ 1690 EDS_R_DiagReqData2 "Diagnostic signal Data request";
CM_ SG_ 1690 EDS_R_DiagReqData3 "Remote Diagnostic signal Data request";
CM_ SG_ 1690 EDS_R_DiagReqData4 "Remote Diagnostic signal Data request";
CM_ SG_ 1690 EDS_R_DiagReqData5 "Diagnostic signal Data request";
CM_ SG_ 1690 EDS_R_DiagReqData6 "Remote Diagnostic signal Data request";
CM_ SG_ 1690 EDS_R_DiagReqData7 "Diagnostic signal Data request";
CM_ SG_ 1691 EDS_F_DiagReqData0 "Remote Diagnostic signal Data request";
CM_ SG_ 1691 EDS_F_DiagReqData1 "Diagnostic signal Data request";
CM_ SG_ 1691 EDS_F_DiagReqData2 "Remote Diagnostic signal Data request";
CM_ SG_ 1691 EDS_F_DiagReqData3 "Diagnostic signal Data request";
CM_ SG_ 1691 EDS_F_DiagReqData4 "Diagnostic signal Data request";
CM_ SG_ 1691 EDS_F_DiagReqData5 "Diagnostic signal Data request";
CM_ SG_ 1691 EDS_F_DiagReqData6 "Diagnostic signal Data request";
CM_ SG_ 1691 EDS_F_DiagReqData7 "Diagnostic signal Data request";
CM_ SG_ 1694 PSM_D_DiagReqData0 "Remote Diagnostic signal Data request";
CM_ SG_ 1694 PSM_D_DiagReqData1 "Diagnostic signal Data request";
CM_ SG_ 1694 PSM_D_DiagReqData2 "Remote Diagnostic signal Data request";
CM_ SG_ 1694 PSM_D_DiagReqData3 "Diagnostic signal Data request";
CM_ SG_ 1694 PSM_D_DiagReqData4 "Diagnostic signal Data request";
CM_ SG_ 1694 PSM_D_DiagReqData5 "Remote Diagnostic signal Data request";
CM_ SG_ 1694 PSM_D_DiagReqData6 "Remote Diagnostic signal Data request";
CM_ SG_ 1694 PSM_D_DiagReqData7 "Diagnostic signal Data request";
CM_ SG_ 1701 MRGEN_DiagReqData0 "Diagnostic signal Data request";
CM_ SG_ 1701 MRGEN_DiagReqData1 "Diagnostic signal Data request";
CM_ SG_ 1701 MRGEN_DiagReqData2 "Diagnostic signal Data request";
CM_ SG_ 1701 MRGEN_DiagReqData3 "Diagnostic signal Data request";
CM_ SG_ 1701 MRGEN_DiagReqData4 "Diagnostic signal Data request";
CM_ SG_ 1701 MRGEN_DiagReqData5 "Remote Diagnostic signal Data request
";
CM_ SG_ 1701 MRGEN_DiagReqData6 "Diagnostic signal Data request";
CM_ SG_ 1701 MRGEN_DiagReqData7 "Diagnostic signal Data request";
CM_ SG_ 1702 SCAM_DiagReqData0 "Remote Diagnostic signal Data request";
CM_ SG_ 1702 SCAM_DiagReqData1 "Diagnostic signal Data request";
CM_ SG_ 1702 SCAM_DiagReqData2 "Remote Diagnostic signal Data request";
CM_ SG_ 1702 SCAM_DiagReqData3 "Remote Diagnostic signal Data request";
CM_ SG_ 1702 SCAM_DiagReqData4 "Diagnostic signal Data request";
CM_ SG_ 1702 SCAM_DiagReqData5 "Remote Diagnostic signal Data request";
CM_ SG_ 1702 SCAM_DiagReqData6 "Remote Diagnostic signal Data request";
CM_ SG_ 1702 SCAM_DiagReqData7 "Remote Diagnostic signal Data request";
CM_ SG_ 1703 RCU_DiagReqData0 "Diagnostic signal Data request";
CM_ SG_ 1703 RCU_DiagReqData1 "Diagnostic signal Data request";
CM_ SG_ 1703 RCU_DiagReqData2 "Diagnostic signal Data request";
CM_ SG_ 1703 RCU_DiagReqData3 "Diagnostic signal Data request";
CM_ SG_ 1703 RCU_DiagReqData4 "Remote Diagnostic signal Data request";
CM_ SG_ 1703 RCU_DiagReqData5 "Diagnostic signal Data request";
CM_ SG_ 1703 RCU_DiagReqData6 "Remote Diagnostic signal Data request";
CM_ SG_ 1703 RCU_DiagReqData7 "Remote Diagnostic signal Data request";
CM_ SG_ 1704 EPS_DiagReqData0 "Remote Diagnostic signal Data request";
CM_ SG_ 1704 EPS_DiagReqData1 "Diagnostic signal Data request";
CM_ SG_ 1704 EPS_DiagReqData2 "Diagnostic signal Data request";
CM_ SG_ 1704 EPS_DiagReqData3 "Diagnostic signal Data request";
CM_ SG_ 1704 EPS_DiagReqData4 "Remote Diagnostic signal Data request";
CM_ SG_ 1704 EPS_DiagReqData5 "Remote Diagnostic signal Data request";
CM_ SG_ 1704 EPS_DiagReqData6 "Remote Diagnostic signal Data request";
CM_ SG_ 1704 EPS_DiagReqData7 "Diagnostic signal Data request";
CM_ SG_ 1705 IDB_DiagReqData0 "Diagnostic signal Data request";
CM_ SG_ 1705 IDB_DiagReqData1 "Diagnostic signal Data request";
CM_ SG_ 1705 IDB_DiagReqData2 "Diagnostic signal Data request";
CM_ SG_ 1705 IDB_DiagReqData3 "Diagnostic signal Data request";
CM_ SG_ 1705 IDB_DiagReqData4 "Diagnostic signal Data request";
CM_ SG_ 1705 IDB_DiagReqData5 "Diagnostic signal Data request";
CM_ SG_ 1705 IDB_DiagReqData6 "Remote Diagnostic signal Data request";
CM_ SG_ 1705 IDB_DiagReqData7 "Diagnostic signal Data request";
CM_ SG_ 1706 AVAS_DiagReqData0 "Remote Diagnostic signal Data request";
CM_ SG_ 1706 AVAS_DiagReqData1 "Diagnostic signal Data request";
CM_ SG_ 1706 AVAS_DiagReqData2 "Diagnostic signal Data request";
CM_ SG_ 1706 AVAS_DiagReqData3 "Remote Diagnostic signal Data request";
CM_ SG_ 1706 AVAS_DiagReqData4 "Diagnostic signal Data request";
CM_ SG_ 1706 AVAS_DiagReqData5 "Diagnostic signal Data request";
CM_ SG_ 1706 AVAS_DiagReqData6 "Diagnostic signal Data request";
CM_ SG_ 1706 AVAS_DiagReqData7 "Diagnostic signal Data request";
CM_ SG_ 1707 EPS2_DiagReqData0 "Diagnostic signal Data request";
CM_ SG_ 1707 EPS2_DiagReqData1 "Diagnostic signal Data request";
CM_ SG_ 1707 EPS2_DiagReqData2 "Diagnostic signal Data request";
CM_ SG_ 1707 EPS2_DiagReqData3 "Remote Diagnostic signal Data request";
CM_ SG_ 1707 EPS2_DiagReqData4 "Diagnostic signal Data request";
CM_ SG_ 1707 EPS2_DiagReqData5 "Remote Diagnostic signal Data request";
CM_ SG_ 1707 EPS2_DiagReqData6 "Diagnostic signal Data request";
CM_ SG_ 1707 EPS2_DiagReqData7 "Diagnostic signal Data request";
CM_ SG_ 1708 VCU_DiagReqData0 "Remote Diagnostic signal Data request";
CM_ SG_ 1708 VCU_DiagReqData1 "Diagnostic signal Data request";
CM_ SG_ 1708 VCU_DiagReqData2 "Remote Diagnostic signal Data request";
CM_ SG_ 1708 VCU_DiagReqData3 "Diagnostic signal Data request";
CM_ SG_ 1708 VCU_DiagReqData4 "Diagnostic signal Data request";
CM_ SG_ 1708 VCU_DiagReqData5 "Remote Diagnostic signal Data request";
CM_ SG_ 1708 VCU_DiagReqData6 "Diagnostic signal Data request";
CM_ SG_ 1708 VCU_DiagReqData7 "Remote Diagnostic signal Data request";
CM_ SG_ 1709 CPD_2_DiagReqData0 "Diagnostic signal Data request";
CM_ SG_ 1709 CPD_2_DiagReqData1 "Diagnostic signal Data request";
CM_ SG_ 1709 CPD_2_DiagReqData2 "Diagnostic signal Data request";
CM_ SG_ 1709 CPD_2_DiagReqData3 "Diagnostic signal Data request";
CM_ SG_ 1709 CPD_2_DiagReqData4 "Diagnostic signal Data request";
CM_ SG_ 1709 CPD_2_DiagReqData5 "Diagnostic signal Data request";
CM_ SG_ 1709 CPD_2_DiagReqData6 "Diagnostic signal Data request";
CM_ SG_ 1709 CPD_2_DiagReqData7 "Diagnostic signal Data request";
CM_ SG_ 1710 EASC_DiagReqData0 "Diagnostic signal Data request";
CM_ SG_ 1710 EASC_DiagReqData1 "Diagnostic signal Data request";
CM_ SG_ 1710 EASC_DiagReqData2 "Diagnostic signal Data request";
CM_ SG_ 1710 EASC_DiagReqData3 "Diagnostic signal Data request";
CM_ SG_ 1710 EASC_DiagReqData4 "Diagnostic signal Data request";
CM_ SG_ 1710 EASC_DiagReqData5 "Diagnostic signal Data request";
CM_ SG_ 1710 EASC_DiagReqData6 "Diagnostic signal Data request";
CM_ SG_ 1710 EASC_DiagReqData7 "Diagnostic signal Data request";
CM_ SG_ 1711 CPD_DiagReqData0 "Diagnostic signal Data request";
CM_ SG_ 1711 CPD_DiagReqData1 "Diagnostic signal Data request";
CM_ SG_ 1711 CPD_DiagReqData2 "Diagnostic signal Data request";
CM_ SG_ 1711 CPD_DiagReqData3 "Diagnostic signal Data request";
CM_ SG_ 1711 CPD_DiagReqData4 "Diagnostic signal Data request";
CM_ SG_ 1711 CPD_DiagReqData5 "Diagnostic signal Data request";
CM_ SG_ 1711 CPD_DiagReqData6 "Diagnostic signal Data request";
CM_ SG_ 1711 CPD_DiagReqData7 "Diagnostic signal Data request";
CM_ SG_ 1716 SRR_FR_DiagReqData0 "SRR_Diagnostic Request";
CM_ SG_ 1716 SRR_FR_DiagReqData1 "SRR_Diagnostic Request";
CM_ SG_ 1716 SRR_FR_DiagReqData2 "Diagnostic signal Data request";
CM_ SG_ 1716 SRR_FR_DiagReqData3 "Diagnostic signal Data request";
CM_ SG_ 1716 SRR_FR_DiagReqData4 "Diagnostic signal Data request";
CM_ SG_ 1716 SRR_FR_DiagReqData5 "SRR_Diagnostic Request";
CM_ SG_ 1716 SRR_FR_DiagReqData6 "Diagnostic signal Data request";
CM_ SG_ 1716 SRR_FR_DiagReqData7 "SRR_Diagnostic Request";
CM_ SG_ 1717 SRR_FL_DiagReqData0 "Diagnostic signal Data request";
CM_ SG_ 1717 SRR_FL_DiagReqData1 "Diagnostic signal Data request";
CM_ SG_ 1717 SRR_FL_DiagReqData2 "SRR_Diagnostic Request";
CM_ SG_ 1717 SRR_FL_DiagReqData3 "SRR_Diagnostic Request";
CM_ SG_ 1717 SRR_FL_DiagReqData4 "Diagnostic signal Data request";
CM_ SG_ 1717 SRR_FL_DiagReqData5 "Diagnostic signal Data request";
CM_ SG_ 1717 SRR_FL_DiagReqData6 "Diagnostic signal Data request";
CM_ SG_ 1717 SRR_FL_DiagReqData7 "Diagnostic signal Data request";
CM_ SG_ 1718 SRR_RR_DiagReqData0 "Diagnostic signal Data request";
CM_ SG_ 1718 SRR_RR_DiagReqData1 "SRR_Diagnostic Request";
CM_ SG_ 1718 SRR_RR_DiagReqData2 "Diagnostic signal Data request";
CM_ SG_ 1718 SRR_RR_DiagReqData3 "Diagnostic signal Data request";
CM_ SG_ 1718 SRR_RR_DiagReqData4 "SRR_Diagnostic Request";
CM_ SG_ 1718 SRR_RR_DiagReqData5 "SRR_Diagnostic Request";
CM_ SG_ 1718 SRR_RR_DiagReqData6 "SRR_Diagnostic Request";
CM_ SG_ 1718 SRR_RR_DiagReqData7 "Diagnostic signal Data request";
CM_ SG_ 1719 SRR_RL_DiagReqData0 "SRR_Diagnostic Request";
CM_ SG_ 1719 SRR_RL_DiagReqData1 "Diagnostic signal Data request";
CM_ SG_ 1719 SRR_RL_DiagReqData2 "Diagnostic signal Data request";
CM_ SG_ 1719 SRR_RL_DiagReqData3 "Diagnostic signal Data request";
CM_ SG_ 1719 SRR_RL_DiagReqData4 "Diagnostic signal Data request";
CM_ SG_ 1719 SRR_RL_DiagReqData5 "SRR_Diagnostic Request";
CM_ SG_ 1719 SRR_RL_DiagReqData6 "Diagnostic signal Data request";
CM_ SG_ 1719 SRR_RL_DiagReqData7 "Diagnostic signal Data request";
CM_ SG_ 1723 TRM_DiagReqData0 "Diagnostic signal Data request";
CM_ SG_ 1723 TRM_DiagReqData1 "Diagnostic signal Data request";
CM_ SG_ 1723 TRM_DiagReqData2 "Remote Diagnostic signal Data request
";
CM_ SG_ 1723 TRM_DiagReqData3 "Remote Diagnostic signal Data request
";
CM_ SG_ 1723 TRM_DiagReqData4 "Remote Diagnostic signal Data request
";
CM_ SG_ 1723 TRM_DiagReqData5 "Diagnostic signal Data request";
CM_ SG_ 1723 TRM_DiagReqData6 "Diagnostic signal Data request";
CM_ SG_ 1723 TRM_DiagReqData7 "Remote Diagnostic signal Data request
";
CM_ SG_ 1725 POD_DCDC_DiagReqData0 "Diagnostic signal Data request";
CM_ SG_ 1725 POD_DCDC_DiagReqData1 "Diagnostic signal Data request";
CM_ SG_ 1725 POD_DCDC_DiagReqData2 "Remote Diagnostic signal Data request";
CM_ SG_ 1725 POD_DCDC_DiagReqData3 "Diagnostic signal Data request";
CM_ SG_ 1725 POD_DCDC_DiagReqData4 "Remote Diagnostic signal Data request";
CM_ SG_ 1725 POD_DCDC_DiagReqData5 "Remote Diagnostic signal Data request";
CM_ SG_ 1725 POD_DCDC_DiagReqData6 "Diagnostic signal Data request";
CM_ SG_ 1725 POD_DCDC_DiagReqData7 "Diagnostic signal Data request";
CM_ SG_ 1726 POD_OBC_DiagReqData0 "Diagnostic signal Data request";
CM_ SG_ 1726 POD_OBC_DiagReqData1 "Diagnostic signal Data request";
CM_ SG_ 1726 POD_OBC_DiagReqData2 "Diagnostic signal Data request";
CM_ SG_ 1726 POD_OBC_DiagReqData3 "Remote Diagnostic signal Data request";
CM_ SG_ 1726 POD_OBC_DiagReqData4 "Diagnostic signal Data request";
CM_ SG_ 1726 POD_OBC_DiagReqData5 "Diagnostic signal Data request";
CM_ SG_ 1726 POD_OBC_DiagReqData6 "Diagnostic signal Data request";
CM_ SG_ 1726 POD_OBC_DiagReqData7 "Remote Diagnostic signal Data request";
CM_ SG_ 1727 POD_DiagReqData0 "Diagnostic signal Data request";
CM_ SG_ 1727 POD_DiagReqData1 "Diagnostic signal Data request";
CM_ SG_ 1727 POD_DiagReqData2 "Diagnostic signal Data request";
CM_ SG_ 1727 POD_DiagReqData3 "Diagnostic signal Data request";
CM_ SG_ 1727 POD_DiagReqData4 "Diagnostic signal Data request";
CM_ SG_ 1727 POD_DiagReqData5 "Diagnostic signal Data request";
CM_ SG_ 1727 POD_DiagReqData6 "Diagnostic signal Data request";
CM_ SG_ 1727 POD_DiagReqData7 "Diagnostic signal Data request";
CM_ SG_ 1728 ADAS_DiagReqData0 "Diagnostic signal Data request";
CM_ SG_ 1728 ADAS_DiagReqData1 "Diagnostic signal Data request";
CM_ SG_ 1728 ADAS_DiagReqData2 "Diagnostic signal Data request";
CM_ SG_ 1728 ADAS_DiagReqData3 "Diagnostic signal Data request";
CM_ SG_ 1728 ADAS_DiagReqData4 "Diagnostic signal Data request";
CM_ SG_ 1728 ADAS_DiagReqData5 "Diagnostic signal Data request";
CM_ SG_ 1728 ADAS_DiagReqData6 "Diagnostic signal Data request";
CM_ SG_ 1728 ADAS_DiagReqData7 "Diagnostic signal Data request";
CM_ SG_ 1729 APM_DiagReqData0 "Diagnostic signal Data request";
CM_ SG_ 1729 APM_DiagReqData1 "Diagnostic signal Data request";
CM_ SG_ 1729 APM_DiagReqData2 "Remote Diagnostic signal Data request";
CM_ SG_ 1729 APM_DiagReqData3 "Diagnostic signal Data request";
CM_ SG_ 1729 APM_DiagReqData4 "Diagnostic signal Data request";
CM_ SG_ 1729 APM_DiagReqData5 "Remote Diagnostic signal Data request";
CM_ SG_ 1729 APM_DiagReqData6 "Diagnostic signal Data request";
CM_ SG_ 1729 APM_DiagReqData7 "Diagnostic signal Data request";
CM_ SG_ 1730 SHVU_F_DiagReqData0 "Diagnostic signal Data request";
CM_ SG_ 1730 SHVU_F_DiagReqData1 "Diagnostic signal Data request";
CM_ SG_ 1730 SHVU_F_DiagReqData2 "Diagnostic signal Data request";
CM_ SG_ 1730 SHVU_F_DiagReqData3 "Remote Diagnostic signal Data request";
CM_ SG_ 1730 SHVU_F_DiagReqData4 "Diagnostic signal Data request";
CM_ SG_ 1730 SHVU_F_DiagReqData5 "Diagnostic signal Data request";
CM_ SG_ 1730 SHVU_F_DiagReqData6 "Remote Diagnostic signal Data request";
CM_ SG_ 1730 SHVU_F_DiagReqData7 "Diagnostic signal Data request";
CM_ SG_ 1731 SHVU_R_DiagReqData0 "Diagnostic signal Data request";
CM_ SG_ 1731 SHVU_R_DiagReqData1 "Diagnostic signal Data request";
CM_ SG_ 1731 SHVU_R_DiagReqData2 "Diagnostic signal Data request";
CM_ SG_ 1731 SHVU_R_DiagReqData3 "Diagnostic signal Data request";
CM_ SG_ 1731 SHVU_R_DiagReqData4 "Diagnostic signal Data request";
CM_ SG_ 1731 SHVU_R_DiagReqData5 "Remote Diagnostic signal Data request";
CM_ SG_ 1731 SHVU_R_DiagReqData6 "Diagnostic signal Data request";
CM_ SG_ 1731 SHVU_R_DiagReqData7 "Diagnostic signal Data request";
CM_ SG_ 1732 OCS_P_DiagReqData0 "Remote Diagnostic signal Data request";
CM_ SG_ 1732 OCS_P_DiagReqData1 "Diagnostic signal Data request";
CM_ SG_ 1732 OCS_P_DiagReqData2 "Diagnostic signal Data request";
CM_ SG_ 1732 OCS_P_DiagReqData3 "Diagnostic signal Data request";
CM_ SG_ 1732 OCS_P_DiagReqData4 "Diagnostic signal Data request";
CM_ SG_ 1732 OCS_P_DiagReqData5 "Diagnostic signal Data request";
CM_ SG_ 1732 OCS_P_DiagReqData6 "Diagnostic signal Data request";
CM_ SG_ 1732 OCS_P_DiagReqData7 "Remote Diagnostic signal Data request";
CM_ SG_ 1737 LDM_L_DiagReqData0 "Remote Diagnostic signal Data request
";
CM_ SG_ 1737 LDM_L_DiagReqData1 "Diagnostic signal Data request";
CM_ SG_ 1737 LDM_L_DiagReqData2 "Diagnostic signal Data request";
CM_ SG_ 1737 LDM_L_DiagReqData3 "Diagnostic signal Data request";
CM_ SG_ 1737 LDM_L_DiagReqData4 "Remote Diagnostic signal Data request
";
CM_ SG_ 1737 LDM_L_DiagReqData5 "Diagnostic signal Data request";
CM_ SG_ 1737 LDM_L_DiagReqData6 "Diagnostic signal Data request";
CM_ SG_ 1737 LDM_L_DiagReqData7 "Diagnostic signal Data request";
CM_ SG_ 1738 LDM_R_DiagReqData0 "Diagnostic signal Data request";
CM_ SG_ 1738 LDM_R_DiagReqData1 "Diagnostic signal Data request";
CM_ SG_ 1738 LDM_R_DiagReqData2 "Diagnostic signal Data request";
CM_ SG_ 1738 LDM_R_DiagReqData3 "Remote Diagnostic signal Data request
";
CM_ SG_ 1738 LDM_R_DiagReqData4 "Diagnostic signal Data request";
CM_ SG_ 1738 LDM_R_DiagReqData5 "Diagnostic signal Data request";
CM_ SG_ 1738 LDM_R_DiagReqData6 "Remote Diagnostic signal Data request
";
CM_ SG_ 1738 LDM_R_DiagReqData7 "Remote Diagnostic signal Data request
";
CM_ SG_ 1752 BAS_DiagReqData0 "Diagnostic signal Data request";
CM_ SG_ 1752 BAS_DiagReqData1 "Diagnostic signal Data request";
CM_ SG_ 1752 BAS_DiagReqData2 "Diagnostic signal Data request";
CM_ SG_ 1752 BAS_DiagReqData3 "Diagnostic signal Data request";
CM_ SG_ 1752 BAS_DiagReqData4 "Diagnostic signal Data request";
CM_ SG_ 1752 BAS_DiagReqData5 "Diagnostic signal Data request";
CM_ SG_ 1752 BAS_DiagReqData6 "Diagnostic signal Data request";
CM_ SG_ 1752 BAS_DiagReqData7 "Diagnostic signal Data request";
CM_ SG_ 1764 DCM_APM_DiagReqData0 "Remote Diagnostic signal Data request";
CM_ SG_ 1764 DCM_APM_DiagReqData1 "Remote Diagnostic signal Data request";
CM_ SG_ 1764 DCM_APM_DiagReqData2 "Remote Diagnostic signal Data request";
CM_ SG_ 1764 DCM_APM_DiagReqData3 "Remote Diagnostic signal Data request";
CM_ SG_ 1764 DCM_APM_DiagReqData4 "Diagnostic signal Data request";
CM_ SG_ 1764 DCM_APM_DiagReqData5 "Diagnostic signal Data request";
CM_ SG_ 1764 DCM_APM_DiagReqData6 "Diagnostic signal Data request";
CM_ SG_ 1764 DCM_APM_DiagReqData7 "Diagnostic signal Data request";
CM_ SG_ 1775 DiagReqAllCANData0 "Diagnostic message Request all CAN";
CM_ SG_ 1775 DiagReqAllCANData1 "Diagnostic message Request all CAN";
CM_ SG_ 1775 DiagReqAllCANData2 "Diagnostic message Request all CAN";
CM_ SG_ 1775 DiagReqAllCANData3 "Diagnostic message Request all CAN";
CM_ SG_ 1775 DiagReqAllCANData4 "Diagnostic message Request all CAN";
CM_ SG_ 1775 DiagReqAllCANData5 "Diagnostic message Request all CAN";
CM_ SG_ 1775 DiagReqAllCANData6 "Diagnostic message Request all CAN";
CM_ SG_ 1775 DiagReqAllCANData7 "Diagnostic message Request all CAN";
CM_ SG_ 1777 ASU_DiagReqData0 "Diagnostic signal Data request";
CM_ SG_ 1777 ASU_DiagReqData1 "Diagnostic signal Data request";
CM_ SG_ 1777 ASU_DiagReqData2 "Diagnostic signal Data request";
CM_ SG_ 1777 ASU_DiagReqData3 "Diagnostic signal Data request";
CM_ SG_ 1777 ASU_DiagReqData4 "Diagnostic signal Data request";
CM_ SG_ 1777 ASU_DiagReqData5 "Diagnostic signal Data request";
CM_ SG_ 1777 ASU_DiagReqData6 "Diagnostic signal Data request";
CM_ SG_ 1777 ASU_DiagReqData7 "Diagnostic signal Data request";
CM_ SG_ 1787 BCM_BPM_DiagReqData0 "Diagnostic signal Data request";
CM_ SG_ 1787 BCM_BPM_DiagReqData1 "Diagnostic signal Data request";
CM_ SG_ 1787 BCM_BPM_DiagReqData2 "Diagnostic signal Data request";
CM_ SG_ 1787 BCM_BPM_DiagReqData3 "Diagnostic signal Data request";
CM_ SG_ 1787 BCM_BPM_DiagReqData4 "Diagnostic signal Data request";
CM_ SG_ 1787 BCM_BPM_DiagReqData5 "Diagnostic signal Data request";
CM_ SG_ 1787 BCM_BPM_DiagReqData6 "Diagnostic signal Data request";
CM_ SG_ 1787 BCM_BPM_DiagReqData7 "Diagnostic signal Data request";
CM_ SG_ 1791 DiagReqAllEcuData0 "Diagnostic message all ECUs";
CM_ SG_ 1791 DiagReqAllEcuData1 "Diagnostic message all ECUs";
CM_ SG_ 1791 DiagReqAllEcuData2 "Diagnostic message all ECUs";
CM_ SG_ 1791 DiagReqAllEcuData3 "Diagnostic message all ECUs";
CM_ SG_ 1791 DiagReqAllEcuData4 "Diagnostic message all ECUs";
CM_ SG_ 1791 DiagReqAllEcuData5 "Diagnostic message all ECUs";
CM_ SG_ 1791 DiagReqAllEcuData6 "Diagnostic message all ECUs";
CM_ SG_ 1791 DiagReqAllEcuData7 "Diagnostic message all ECUs";
CM_ SG_ 2033 Request_Airbag_Deployment "Diagnostic request for ACM Scrapping";
CM_ SG_ 2041 Response_Airbag_Deployment "Diagnostic response for ACM Scrapping";

BA_DEF_ BO_  "GenMsgSendType" ENUM "Cyclic","NotUsed","NotUsed","NotUsed","NotUsed","NotUsed","NotUsed","IfActive","NoMsgSendType","NotUsed";
BA_DEF_ BO_  "GenMsgILSupport" ENUM "No","Yes";
BA_DEF_ BO_  "DiagResponse" ENUM "No","Yes";
BA_DEF_ BO_  "DiagRequest" ENUM "No","Yes";
BA_DEF_ BO_  "NmAsrMessage" ENUM "No","Yes";
BA_DEF_ BO_  "DiagState" ENUM "No","Yes";
BA_DEF_ BO_  "DiagUudtResponse" ENUM "False","True";
BA_DEF_ BO_  "GenMsgStartDelayTime" INT 0 65535;
BA_DEF_ BO_  "GenMsgNrOfRepetition" INT 0 0;
BA_DEF_ BO_  "GenMsgCycleTimeFast" INT 0 0;
BA_DEF_ BO_  "GenMsgCycleTime" INT 0 0;
BA_DEF_ BU_  "NmStationAddress" HEX 0 0;
BA_DEF_ BU_  "TpSTMin" INT 0 255;
BA_DEF_ BU_  "ILUsed" ENUM "No","Yes";
BA_DEF_ BU_  "NmAsrNode" ENUM "No","Yes";
BA_DEF_ BU_  "NmAsrNodeIdentifier" HEX 0 255;
BA_DEF_ BU_  "NmAsrCanMsgCycleOffset" INT 0 65535;
BA_DEF_ BU_  "NmAsrCanMsgReducedTime" INT 320 640;
BA_DEF_ SG_  "GenSigSendType" ENUM "Cyclic","OnWrite","OnWriteWithRepetition","OnChange","OnChangeWithRepetition","IfActive","IfActiveWithRepetition","NoSigSendType","NotUsed","NotUsed","NotUsed","NotUsed","NotUsed";
BA_DEF_ SG_  "InvalidValue" STRING;
BA_DEF_ SG_  "GenSigStartValue" INT 0 0;
BA_DEF_ SG_  "GenSigTimeoutTime_ALL" INT 0 65535;
BA_DEF_  "DBName" STRING;
BA_DEF_  "NmAsrBaseAddress" HEX 0 2047;
BA_DEF_  "NmAsrMessageCount" INT 1 256;
BA_DEF_  "NmAsrTimeoutTime" INT 0 65535;
BA_DEF_  "NmAsrWaitBusSleepTime" INT 0 65535;
BA_DEF_  "NmAsrRepeatMessageTime" INT 0 65535;
BA_DEF_  "NmAsrCanMsgCycleTime" INT 0 65535;
BA_DEF_  "Baudrate" INT 0 1000000;
BA_DEF_  "BusType" STRING;
BA_DEF_  "Manufacturer" STRING;
BA_DEF_ BU_  "ECU" STRING;

BA_DEF_DEF_  "Baudrate" 500000;
BA_DEF_DEF_  "DiagRequest" "No";
BA_DEF_DEF_  "DiagResponse" "No";
BA_DEF_DEF_  "DiagState" "No";
BA_DEF_DEF_  "DiagUudtResponse" "False";
BA_DEF_DEF_  "ECU" "";
BA_DEF_DEF_  "GenMsgCycleTime" 0;
BA_DEF_DEF_  "GenMsgCycleTimeFast" 0;
BA_DEF_DEF_  "GenMsgILSupport" "Yes";
BA_DEF_DEF_  "GenMsgNrOfRepetition" 0;
BA_DEF_DEF_  "GenMsgSendType" "NoMsgSendType";
BA_DEF_DEF_  "GenMsgStartDelayTime" 0;
BA_DEF_DEF_  "GenSigSendType" "Cyclic";
BA_DEF_DEF_  "GenSigStartValue" 0;
BA_DEF_DEF_  "GenSigTimeoutTime_ALL" 0;
BA_DEF_DEF_  "ILUsed" "Yes";
BA_DEF_DEF_  "Manufacturer" "VinFast";
BA_DEF_DEF_  "NmAsrBaseAddress" 1280;
BA_DEF_DEF_  "NmAsrCanMsgCycleOffset" 0;
BA_DEF_DEF_  "NmAsrCanMsgCycleTime" 640;
BA_DEF_DEF_  "NmAsrCanMsgReducedTime" 320;
BA_DEF_DEF_  "NmAsrMessage" "No";
BA_DEF_DEF_  "NmAsrMessageCount" 128;
BA_DEF_DEF_  "NmAsrNode" "Yes";
BA_DEF_DEF_  "NmAsrNodeIdentifier" 0;
BA_DEF_DEF_  "NmAsrRepeatMessageTime" 3200;
BA_DEF_DEF_  "NmAsrTimeoutTime" 2000;
BA_DEF_DEF_  "NmAsrWaitBusSleepTime" 1500;
BA_DEF_DEF_  "NmStationAddress" 0;
BA_DEF_DEF_  "TpSTMin" 20;

BA_ "BusType" "CAN";
BA_ "DBName" "Diag";
BA_ "ECU" BU_ OBD "OBD";
BA_ "NmAsrCanMsgCycleOffset" BU_ OBD 255;
BA_ "NmAsrCanMsgReducedTime" BU_ OBD 447;
BA_ "NmAsrNodeIdentifier" BU_ OBD 51;
BA_ "NmStationAddress" BU_ OBD 51;
BA_ "ECU" BU_ XGW_Diag "XGW_DiagCAN";
BA_ "NmAsrCanMsgCycleOffset" BU_ XGW_Diag 10;
BA_ "NmAsrCanMsgReducedTime" BU_ XGW_Diag 325;
BA_ "NmAsrNodeIdentifier" BU_ XGW_Diag 2;
BA_ "NmStationAddress" BU_ XGW_Diag 2;
BA_ "DiagResponse" BO_ 1537 1;
BA_ "GenMsgILSupport" BO_ 1537 0;
BA_ "DiagResponse" BO_ 1538 1;
BA_ "GenMsgILSupport" BO_ 1538 0;
BA_ "DiagResponse" BO_ 1540 1;
BA_ "GenMsgILSupport" BO_ 1540 0;
BA_ "DiagResponse" BO_ 1541 1;
BA_ "GenMsgILSupport" BO_ 1541 0;
BA_ "DiagResponse" BO_ 1544 1;
BA_ "GenMsgILSupport" BO_ 1544 0;
BA_ "DiagResponse" BO_ 1545 1;
BA_ "GenMsgILSupport" BO_ 1545 0;
BA_ "DiagResponse" BO_ 1549 1;
BA_ "GenMsgILSupport" BO_ 1549 0;
BA_ "DiagResponse" BO_ 1550 1;
BA_ "GenMsgILSupport" BO_ 1550 0;
BA_ "DiagResponse" BO_ 1551 1;
BA_ "GenMsgILSupport" BO_ 1551 0;
BA_ "DiagResponse" BO_ 1552 1;
BA_ "GenMsgILSupport" BO_ 1552 0;
BA_ "DiagResponse" BO_ 1553 1;
BA_ "DiagResponse" BO_ 1555 1;
BA_ "GenMsgILSupport" BO_ 1555 0;
BA_ "DiagResponse" BO_ 1556 1;
BA_ "GenMsgILSupport" BO_ 1556 0;
BA_ "DiagResponse" BO_ 1562 1;
BA_ "GenMsgILSupport" BO_ 1562 0;
BA_ "DiagResponse" BO_ 1563 1;
BA_ "GenMsgILSupport" BO_ 1563 0;
BA_ "DiagResponse" BO_ 1566 1;
BA_ "GenMsgILSupport" BO_ 1566 0;
BA_ "DiagResponse" BO_ 1573 1;
BA_ "GenMsgILSupport" BO_ 1573 0;
BA_ "DiagResponse" BO_ 1574 1;
BA_ "GenMsgILSupport" BO_ 1574 0;
BA_ "DiagResponse" BO_ 1575 1;
BA_ "GenMsgILSupport" BO_ 1575 0;
BA_ "DiagResponse" BO_ 1576 1;
BA_ "GenMsgILSupport" BO_ 1576 0;
BA_ "DiagResponse" BO_ 1577 1;
BA_ "GenMsgILSupport" BO_ 1577 0;
BA_ "DiagResponse" BO_ 1578 1;
BA_ "GenMsgILSupport" BO_ 1578 0;
BA_ "DiagResponse" BO_ 1579 1;
BA_ "GenMsgILSupport" BO_ 1579 0;
BA_ "DiagResponse" BO_ 1580 1;
BA_ "GenMsgILSupport" BO_ 1580 0;
BA_ "DiagResponse" BO_ 1581 1;
BA_ "GenMsgILSupport" BO_ 1581 0;
BA_ "DiagResponse" BO_ 1582 1;
BA_ "GenMsgILSupport" BO_ 1582 0;
BA_ "DiagResponse" BO_ 1583 1;
BA_ "GenMsgILSupport" BO_ 1583 0;
BA_ "DiagResponse" BO_ 1588 1;
BA_ "DiagResponse" BO_ 1589 1;
BA_ "DiagResponse" BO_ 1590 1;
BA_ "DiagResponse" BO_ 1591 1;
BA_ "DiagResponse" BO_ 1592 1;
BA_ "DiagResponse" BO_ 1595 1;
BA_ "GenMsgILSupport" BO_ 1595 0;
BA_ "DiagResponse" BO_ 1597 1;
BA_ "GenMsgILSupport" BO_ 1597 0;
BA_ "DiagResponse" BO_ 1598 1;
BA_ "GenMsgILSupport" BO_ 1598 0;
BA_ "DiagResponse" BO_ 1599 1;
BA_ "GenMsgILSupport" BO_ 1599 0;
BA_ "DiagResponse" BO_ 1600 1;
BA_ "GenMsgILSupport" BO_ 1600 0;
BA_ "DiagResponse" BO_ 1601 1;
BA_ "GenMsgILSupport" BO_ 1601 0;
BA_ "DiagResponse" BO_ 1602 1;
BA_ "GenMsgILSupport" BO_ 1602 0;
BA_ "DiagResponse" BO_ 1603 1;
BA_ "GenMsgILSupport" BO_ 1603 0;
BA_ "DiagResponse" BO_ 1604 1;
BA_ "GenMsgILSupport" BO_ 1604 0;
BA_ "DiagResponse" BO_ 1609 1;
BA_ "GenMsgILSupport" BO_ 1609 0;
BA_ "DiagResponse" BO_ 1610 1;
BA_ "GenMsgILSupport" BO_ 1610 0;
BA_ "DiagResponse" BO_ 1624 1;
BA_ "GenMsgILSupport" BO_ 1624 0;
BA_ "DiagResponse" BO_ 1636 1;
BA_ "GenMsgILSupport" BO_ 1636 0;
BA_ "DiagResponse" BO_ 1659 1;
BA_ "GenMsgILSupport" BO_ 1659 0;
BA_ "DiagRequest" BO_ 1665 1;
BA_ "GenMsgILSupport" BO_ 1665 0;
BA_ "DiagRequest" BO_ 1666 1;
BA_ "GenMsgILSupport" BO_ 1666 0;
BA_ "DiagRequest" BO_ 1668 1;
BA_ "GenMsgILSupport" BO_ 1668 0;
BA_ "DiagRequest" BO_ 1669 1;
BA_ "GenMsgILSupport" BO_ 1669 0;
BA_ "DiagRequest" BO_ 1672 1;
BA_ "GenMsgILSupport" BO_ 1672 0;
BA_ "DiagRequest" BO_ 1673 1;
BA_ "GenMsgILSupport" BO_ 1673 0;
BA_ "DiagRequest" BO_ 1677 1;
BA_ "GenMsgILSupport" BO_ 1677 0;
BA_ "DiagRequest" BO_ 1678 1;
BA_ "GenMsgILSupport" BO_ 1678 0;
BA_ "DiagRequest" BO_ 1679 1;
BA_ "GenMsgILSupport" BO_ 1679 0;
BA_ "DiagRequest" BO_ 1680 1;
BA_ "GenMsgILSupport" BO_ 1680 0;
BA_ "DiagRequest" BO_ 1681 1;
BA_ "DiagRequest" BO_ 1683 1;
BA_ "GenMsgILSupport" BO_ 1683 0;
BA_ "DiagRequest" BO_ 1684 1;
BA_ "GenMsgILSupport" BO_ 1684 0;
BA_ "DiagRequest" BO_ 1690 1;
BA_ "GenMsgILSupport" BO_ 1690 0;
BA_ "DiagRequest" BO_ 1691 1;
BA_ "GenMsgILSupport" BO_ 1691 0;
BA_ "DiagRequest" BO_ 1694 1;
BA_ "GenMsgILSupport" BO_ 1694 0;
BA_ "DiagRequest" BO_ 1701 1;
BA_ "GenMsgILSupport" BO_ 1701 0;
BA_ "DiagRequest" BO_ 1702 1;
BA_ "GenMsgILSupport" BO_ 1702 0;
BA_ "DiagRequest" BO_ 1703 1;
BA_ "GenMsgILSupport" BO_ 1703 0;
BA_ "DiagRequest" BO_ 1704 1;
BA_ "GenMsgILSupport" BO_ 1704 0;
BA_ "DiagRequest" BO_ 1705 1;
BA_ "GenMsgILSupport" BO_ 1705 0;
BA_ "DiagRequest" BO_ 1706 1;
BA_ "GenMsgILSupport" BO_ 1706 0;
BA_ "DiagRequest" BO_ 1707 1;
BA_ "GenMsgILSupport" BO_ 1707 0;
BA_ "DiagRequest" BO_ 1708 1;
BA_ "GenMsgILSupport" BO_ 1708 0;
BA_ "DiagRequest" BO_ 1709 1;
BA_ "GenMsgILSupport" BO_ 1709 0;
BA_ "DiagRequest" BO_ 1710 1;
BA_ "GenMsgILSupport" BO_ 1710 0;
BA_ "DiagRequest" BO_ 1711 1;
BA_ "GenMsgILSupport" BO_ 1711 0;
BA_ "DiagRequest" BO_ 1716 1;
BA_ "GenMsgILSupport" BO_ 1716 0;
BA_ "DiagRequest" BO_ 1717 1;
BA_ "GenMsgILSupport" BO_ 1717 0;
BA_ "DiagRequest" BO_ 1718 1;
BA_ "GenMsgILSupport" BO_ 1718 0;
BA_ "DiagRequest" BO_ 1719 1;
BA_ "GenMsgILSupport" BO_ 1719 0;
BA_ "DiagRequest" BO_ 1723 1;
BA_ "GenMsgILSupport" BO_ 1723 0;
BA_ "DiagRequest" BO_ 1725 1;
BA_ "GenMsgILSupport" BO_ 1725 0;
BA_ "DiagRequest" BO_ 1726 1;
BA_ "GenMsgILSupport" BO_ 1726 0;
BA_ "DiagRequest" BO_ 1727 1;
BA_ "DiagResponse" BO_ 1727 1;
BA_ "GenMsgILSupport" BO_ 1727 0;
BA_ "DiagRequest" BO_ 1728 1;
BA_ "GenMsgILSupport" BO_ 1728 0;
BA_ "DiagRequest" BO_ 1729 1;
BA_ "GenMsgILSupport" BO_ 1729 0;
BA_ "DiagRequest" BO_ 1730 1;
BA_ "GenMsgILSupport" BO_ 1730 0;
BA_ "DiagRequest" BO_ 1731 1;
BA_ "GenMsgILSupport" BO_ 1731 0;
BA_ "DiagRequest" BO_ 1732 1;
BA_ "GenMsgILSupport" BO_ 1732 0;
BA_ "DiagRequest" BO_ 1737 1;
BA_ "GenMsgILSupport" BO_ 1737 0;
BA_ "DiagRequest" BO_ 1738 1;
BA_ "GenMsgILSupport" BO_ 1738 0;
BA_ "DiagRequest" BO_ 1752 1;
BA_ "GenMsgILSupport" BO_ 1752 0;
BA_ "DiagRequest" BO_ 1764 1;
BA_ "GenMsgILSupport" BO_ 1764 0;
BA_ "DiagRequest" BO_ 1775 1;
BA_ "DiagState" BO_ 1775 1;
BA_ "GenMsgILSupport" BO_ 1775 0;
BA_ "DiagRequest" BO_ 1777 1;
BA_ "DiagRequest" BO_ 1787 1;
BA_ "GenMsgILSupport" BO_ 1787 0;
BA_ "DiagRequest" BO_ 1791 1;
BA_ "DiagState" BO_ 1791 1;
BA_ "GenMsgILSupport" BO_ 1791 0;
BA_ "DiagRequest" BO_ 2033 1;
BA_ "GenMsgILSupport" BO_ 2033 0;
BA_ "DiagResponse" BO_ 2041 1;
BA_ "GenMsgILSupport" BO_ 2041 0;
BA_ "GenSigSendType" SG_ 1537 BCM_DiagRespData0 7;
BA_ "InvalidValue" SG_ 1537 BCM_DiagRespData0 "null";
BA_ "GenSigSendType" SG_ 1537 BCM_DiagRespData1 7;
BA_ "InvalidValue" SG_ 1537 BCM_DiagRespData1 "null";
BA_ "GenSigSendType" SG_ 1537 BCM_DiagRespData2 7;
BA_ "InvalidValue" SG_ 1537 BCM_DiagRespData2 "null";
BA_ "GenSigSendType" SG_ 1537 BCM_DiagRespData3 7;
BA_ "InvalidValue" SG_ 1537 BCM_DiagRespData3 "null";
BA_ "GenSigSendType" SG_ 1537 BCM_DiagRespData4 7;
BA_ "InvalidValue" SG_ 1537 BCM_DiagRespData4 "null";
BA_ "GenSigSendType" SG_ 1537 BCM_DiagRespData5 7;
BA_ "InvalidValue" SG_ 1537 BCM_DiagRespData5 "null";
BA_ "GenSigSendType" SG_ 1537 BCM_DiagRespData6 7;
BA_ "InvalidValue" SG_ 1537 BCM_DiagRespData6 "null";
BA_ "GenSigSendType" SG_ 1537 BCM_DiagRespData7 7;
BA_ "InvalidValue" SG_ 1537 BCM_DiagRespData7 "null";
BA_ "GenSigSendType" SG_ 1538 XGW_DiagRespData0 7;
BA_ "InvalidValue" SG_ 1538 XGW_DiagRespData0 "null";
BA_ "GenSigSendType" SG_ 1538 XGW_DiagRespData1 7;
BA_ "InvalidValue" SG_ 1538 XGW_DiagRespData1 "null";
BA_ "GenSigSendType" SG_ 1538 XGW_DiagRespData2 7;
BA_ "InvalidValue" SG_ 1538 XGW_DiagRespData2 "null";
BA_ "GenSigSendType" SG_ 1538 XGW_DiagRespData3 7;
BA_ "InvalidValue" SG_ 1538 XGW_DiagRespData3 "null";
BA_ "GenSigSendType" SG_ 1538 XGW_DiagRespData4 7;
BA_ "InvalidValue" SG_ 1538 XGW_DiagRespData4 "null";
BA_ "GenSigSendType" SG_ 1538 XGW_DiagRespData5 7;
BA_ "InvalidValue" SG_ 1538 XGW_DiagRespData5 "null";
BA_ "GenSigSendType" SG_ 1538 XGW_DiagRespData6 7;
BA_ "InvalidValue" SG_ 1538 XGW_DiagRespData6 "null";
BA_ "GenSigSendType" SG_ 1538 XGW_DiagRespData7 7;
BA_ "InvalidValue" SG_ 1538 XGW_DiagRespData7 "null";
BA_ "GenSigSendType" SG_ 1540 MHU_DiagRespData0 7;
BA_ "InvalidValue" SG_ 1540 MHU_DiagRespData0 "null";
BA_ "GenSigSendType" SG_ 1540 MHU_DiagRespData1 7;
BA_ "InvalidValue" SG_ 1540 MHU_DiagRespData1 "null";
BA_ "GenSigSendType" SG_ 1540 MHU_DiagRespData2 7;
BA_ "InvalidValue" SG_ 1540 MHU_DiagRespData2 "null";
BA_ "GenSigSendType" SG_ 1540 MHU_DiagRespData3 7;
BA_ "InvalidValue" SG_ 1540 MHU_DiagRespData3 "null";
BA_ "GenSigSendType" SG_ 1540 MHU_DiagRespData4 7;
BA_ "InvalidValue" SG_ 1540 MHU_DiagRespData4 "null";
BA_ "GenSigSendType" SG_ 1540 MHU_DiagRespData5 7;
BA_ "InvalidValue" SG_ 1540 MHU_DiagRespData5 "null";
BA_ "GenSigSendType" SG_ 1540 MHU_DiagRespData6 7;
BA_ "InvalidValue" SG_ 1540 MHU_DiagRespData6 "null";
BA_ "GenSigSendType" SG_ 1540 MHU_DiagRespData7 7;
BA_ "InvalidValue" SG_ 1540 MHU_DiagRespData7 "null";
BA_ "GenSigSendType" SG_ 1541 AMP_DiagRespData0 7;
BA_ "InvalidValue" SG_ 1541 AMP_DiagRespData0 "null";
BA_ "GenSigSendType" SG_ 1541 AMP_DiagRespData1 7;
BA_ "InvalidValue" SG_ 1541 AMP_DiagRespData1 "null";
BA_ "GenSigSendType" SG_ 1541 AMP_DiagRespData2 7;
BA_ "InvalidValue" SG_ 1541 AMP_DiagRespData2 "null";
BA_ "GenSigSendType" SG_ 1541 AMP_DiagRespData3 7;
BA_ "InvalidValue" SG_ 1541 AMP_DiagRespData3 "null";
BA_ "GenSigSendType" SG_ 1541 AMP_DiagRespData4 7;
BA_ "InvalidValue" SG_ 1541 AMP_DiagRespData4 "null";
BA_ "GenSigSendType" SG_ 1541 AMP_DiagRespData5 7;
BA_ "InvalidValue" SG_ 1541 AMP_DiagRespData5 "null";
BA_ "GenSigSendType" SG_ 1541 AMP_DiagRespData6 7;
BA_ "InvalidValue" SG_ 1541 AMP_DiagRespData6 "null";
BA_ "GenSigSendType" SG_ 1541 AMP_DiagRespData7 7;
BA_ "InvalidValue" SG_ 1541 AMP_DiagRespData7 "null";
BA_ "GenSigSendType" SG_ 1544 ACM_DiagRespData0 7;
BA_ "InvalidValue" SG_ 1544 ACM_DiagRespData0 "null";
BA_ "GenSigSendType" SG_ 1544 ACM_DiagRespData1 7;
BA_ "InvalidValue" SG_ 1544 ACM_DiagRespData1 "null";
BA_ "GenSigSendType" SG_ 1544 ACM_DiagRespData2 7;
BA_ "InvalidValue" SG_ 1544 ACM_DiagRespData2 "null";
BA_ "GenSigSendType" SG_ 1544 ACM_DiagRespData3 7;
BA_ "InvalidValue" SG_ 1544 ACM_DiagRespData3 "null";
BA_ "GenSigSendType" SG_ 1544 ACM_DiagRespData4 7;
BA_ "InvalidValue" SG_ 1544 ACM_DiagRespData4 "null";
BA_ "GenSigSendType" SG_ 1544 ACM_DiagRespData5 7;
BA_ "InvalidValue" SG_ 1544 ACM_DiagRespData5 "null";
BA_ "GenSigSendType" SG_ 1544 ACM_DiagRespData6 7;
BA_ "InvalidValue" SG_ 1544 ACM_DiagRespData6 "null";
BA_ "GenSigSendType" SG_ 1544 ACM_DiagRespData7 7;
BA_ "InvalidValue" SG_ 1544 ACM_DiagRespData7 "null";
BA_ "GenSigSendType" SG_ 1545 CCUF_DiagRespData0 7;
BA_ "InvalidValue" SG_ 1545 CCUF_DiagRespData0 "null";
BA_ "GenSigSendType" SG_ 1545 CCUF_DiagRespData1 7;
BA_ "InvalidValue" SG_ 1545 CCUF_DiagRespData1 "null";
BA_ "GenSigSendType" SG_ 1545 CCUF_DiagRespData2 7;
BA_ "InvalidValue" SG_ 1545 CCUF_DiagRespData2 "null";
BA_ "GenSigSendType" SG_ 1545 CCUF_DiagRespData3 7;
BA_ "InvalidValue" SG_ 1545 CCUF_DiagRespData3 "null";
BA_ "GenSigSendType" SG_ 1545 CCUF_DiagRespData4 7;
BA_ "InvalidValue" SG_ 1545 CCUF_DiagRespData4 "null";
BA_ "GenSigSendType" SG_ 1545 CCUF_DiagRespData5 7;
BA_ "InvalidValue" SG_ 1545 CCUF_DiagRespData5 "null";
BA_ "GenSigSendType" SG_ 1545 CCUF_DiagRespData6 7;
BA_ "InvalidValue" SG_ 1545 CCUF_DiagRespData6 "null";
BA_ "GenSigSendType" SG_ 1545 CCUF_DiagRespData7 7;
BA_ "InvalidValue" SG_ 1545 CCUF_DiagRespData7 "null";
BA_ "GenSigSendType" SG_ 1549 HUD_DiagRespData0 7;
BA_ "InvalidValue" SG_ 1549 HUD_DiagRespData0 "null";
BA_ "GenSigSendType" SG_ 1549 HUD_DiagRespData1 7;
BA_ "InvalidValue" SG_ 1549 HUD_DiagRespData1 "null";
BA_ "GenSigSendType" SG_ 1549 HUD_DiagRespData2 7;
BA_ "InvalidValue" SG_ 1549 HUD_DiagRespData2 "null";
BA_ "GenSigSendType" SG_ 1549 HUD_DiagRespData3 7;
BA_ "InvalidValue" SG_ 1549 HUD_DiagRespData3 "null";
BA_ "GenSigSendType" SG_ 1549 HUD_DiagRespData4 7;
BA_ "InvalidValue" SG_ 1549 HUD_DiagRespData4 "null";
BA_ "GenSigSendType" SG_ 1549 HUD_DiagRespData5 7;
BA_ "InvalidValue" SG_ 1549 HUD_DiagRespData5 "null";
BA_ "GenSigSendType" SG_ 1549 HUD_DiagRespData6 7;
BA_ "InvalidValue" SG_ 1549 HUD_DiagRespData6 "null";
BA_ "GenSigSendType" SG_ 1549 HUD_DiagRespData7 7;
BA_ "InvalidValue" SG_ 1549 HUD_DiagRespData7 "null";
BA_ "GenSigSendType" SG_ 1550 ETG_DiagRespData0 7;
BA_ "InvalidValue" SG_ 1550 ETG_DiagRespData0 "null";
BA_ "GenSigSendType" SG_ 1550 ETG_DiagRespData1 7;
BA_ "InvalidValue" SG_ 1550 ETG_DiagRespData1 "null";
BA_ "GenSigSendType" SG_ 1550 ETG_DiagRespData2 7;
BA_ "InvalidValue" SG_ 1550 ETG_DiagRespData2 "null";
BA_ "GenSigSendType" SG_ 1550 ETG_DiagRespData3 7;
BA_ "InvalidValue" SG_ 1550 ETG_DiagRespData3 "null";
BA_ "GenSigSendType" SG_ 1550 ETG_DiagRespData4 7;
BA_ "InvalidValue" SG_ 1550 ETG_DiagRespData4 "null";
BA_ "GenSigSendType" SG_ 1550 ETG_DiagRespData5 7;
BA_ "InvalidValue" SG_ 1550 ETG_DiagRespData5 "null";
BA_ "GenSigSendType" SG_ 1550 ETG_DiagRespData6 7;
BA_ "InvalidValue" SG_ 1550 ETG_DiagRespData6 "null";
BA_ "GenSigSendType" SG_ 1550 ETG_DiagRespData7 7;
BA_ "InvalidValue" SG_ 1550 ETG_DiagRespData7 "null";
BA_ "GenSigSendType" SG_ 1551 YSS_DiagRespData0 7;
BA_ "InvalidValue" SG_ 1551 YSS_DiagRespData0 "null";
BA_ "GenSigSendType" SG_ 1551 YSS_DiagRespData1 7;
BA_ "InvalidValue" SG_ 1551 YSS_DiagRespData1 "null";
BA_ "GenSigSendType" SG_ 1551 YSS_DiagRespData2 7;
BA_ "InvalidValue" SG_ 1551 YSS_DiagRespData2 "null";
BA_ "GenSigSendType" SG_ 1551 YSS_DiagRespData3 7;
BA_ "InvalidValue" SG_ 1551 YSS_DiagRespData3 "null";
BA_ "GenSigSendType" SG_ 1551 YSS_DiagRespData4 7;
BA_ "InvalidValue" SG_ 1551 YSS_DiagRespData4 "null";
BA_ "GenSigSendType" SG_ 1551 YSS_DiagRespData5 7;
BA_ "InvalidValue" SG_ 1551 YSS_DiagRespData5 "null";
BA_ "GenSigSendType" SG_ 1551 YSS_DiagRespData6 7;
BA_ "InvalidValue" SG_ 1551 YSS_DiagRespData6 "null";
BA_ "GenSigSendType" SG_ 1551 YSS_DiagRespData7 7;
BA_ "InvalidValue" SG_ 1551 YSS_DiagRespData7 "null";
BA_ "GenSigSendType" SG_ 1552 GS_DiagRespData0 7;
BA_ "InvalidValue" SG_ 1552 GS_DiagRespData0 "null";
BA_ "GenSigSendType" SG_ 1552 GS_DiagRespData1 7;
BA_ "InvalidValue" SG_ 1552 GS_DiagRespData1 "null";
BA_ "GenSigSendType" SG_ 1552 GS_DiagRespData2 7;
BA_ "InvalidValue" SG_ 1552 GS_DiagRespData2 "null";
BA_ "GenSigSendType" SG_ 1552 GS_DiagRespData3 7;
BA_ "InvalidValue" SG_ 1552 GS_DiagRespData3 "null";
BA_ "GenSigSendType" SG_ 1552 GS_DiagRespData4 7;
BA_ "InvalidValue" SG_ 1552 GS_DiagRespData4 "null";
BA_ "GenSigSendType" SG_ 1552 GS_DiagRespData5 7;
BA_ "InvalidValue" SG_ 1552 GS_DiagRespData5 "null";
BA_ "GenSigSendType" SG_ 1552 GS_DiagRespData6 7;
BA_ "InvalidValue" SG_ 1552 GS_DiagRespData6 "null";
BA_ "GenSigSendType" SG_ 1552 GS_DiagRespData7 7;
BA_ "InvalidValue" SG_ 1552 GS_DiagRespData7 "null";
BA_ "GenSigSendType" SG_ 1553 ASU_Gateway_DiagRespData0 7;
BA_ "InvalidValue" SG_ 1553 ASU_Gateway_DiagRespData0 "null";
BA_ "GenSigSendType" SG_ 1553 ASU_Gateway_DiagRespData1 7;
BA_ "InvalidValue" SG_ 1553 ASU_Gateway_DiagRespData1 "null";
BA_ "GenSigSendType" SG_ 1553 ASU_Gateway_DiagRespData2 7;
BA_ "InvalidValue" SG_ 1553 ASU_Gateway_DiagRespData2 "null";
BA_ "GenSigSendType" SG_ 1553 ASU_Gateway_DiagRespData3 7;
BA_ "InvalidValue" SG_ 1553 ASU_Gateway_DiagRespData3 "null";
BA_ "GenSigSendType" SG_ 1553 ASU_Gateway_DiagRespData4 7;
BA_ "InvalidValue" SG_ 1553 ASU_Gateway_DiagRespData4 "null";
BA_ "GenSigSendType" SG_ 1553 ASU_Gateway_DiagRespData5 7;
BA_ "InvalidValue" SG_ 1553 ASU_Gateway_DiagRespData5 "null";
BA_ "GenSigSendType" SG_ 1553 ASU_Gateway_DiagRespData6 7;
BA_ "InvalidValue" SG_ 1553 ASU_Gateway_DiagRespData6 "null";
BA_ "GenSigSendType" SG_ 1553 ASU_Gateway_DiagRespData7 7;
BA_ "InvalidValue" SG_ 1553 ASU_Gateway_DiagRespData7 "null";
BA_ "GenSigSendType" SG_ 1555 BMS_DiagRespData0 7;
BA_ "InvalidValue" SG_ 1555 BMS_DiagRespData0 "null";
BA_ "GenSigSendType" SG_ 1555 BMS_DiagRespData1 7;
BA_ "InvalidValue" SG_ 1555 BMS_DiagRespData1 "null";
BA_ "GenSigSendType" SG_ 1555 BMS_DiagRespData2 7;
BA_ "InvalidValue" SG_ 1555 BMS_DiagRespData2 "null";
BA_ "GenSigSendType" SG_ 1555 BMS_DiagRespData3 7;
BA_ "InvalidValue" SG_ 1555 BMS_DiagRespData3 "null";
BA_ "GenSigSendType" SG_ 1555 BMS_DiagRespData4 7;
BA_ "InvalidValue" SG_ 1555 BMS_DiagRespData4 "null";
BA_ "GenSigSendType" SG_ 1555 BMS_DiagRespData5 7;
BA_ "InvalidValue" SG_ 1555 BMS_DiagRespData5 "null";
BA_ "GenSigSendType" SG_ 1555 BMS_DiagRespData6 7;
BA_ "InvalidValue" SG_ 1555 BMS_DiagRespData6 "null";
BA_ "GenSigSendType" SG_ 1555 BMS_DiagRespData7 7;
BA_ "InvalidValue" SG_ 1555 BMS_DiagRespData7 "null";
BA_ "GenSigSendType" SG_ 1556 CCUR_DiagRespData0 7;
BA_ "InvalidValue" SG_ 1556 CCUR_DiagRespData0 "null";
BA_ "GenSigSendType" SG_ 1556 CCUR_DiagRespData1 7;
BA_ "InvalidValue" SG_ 1556 CCUR_DiagRespData1 "null";
BA_ "GenSigSendType" SG_ 1556 CCUR_DiagRespData2 7;
BA_ "InvalidValue" SG_ 1556 CCUR_DiagRespData2 "null";
BA_ "GenSigSendType" SG_ 1556 CCUR_DiagRespData3 7;
BA_ "InvalidValue" SG_ 1556 CCUR_DiagRespData3 "null";
BA_ "GenSigSendType" SG_ 1556 CCUR_DiagRespData4 7;
BA_ "InvalidValue" SG_ 1556 CCUR_DiagRespData4 "null";
BA_ "GenSigSendType" SG_ 1556 CCUR_DiagRespData5 7;
BA_ "InvalidValue" SG_ 1556 CCUR_DiagRespData5 "null";
BA_ "GenSigSendType" SG_ 1556 CCUR_DiagRespData6 7;
BA_ "InvalidValue" SG_ 1556 CCUR_DiagRespData6 "null";
BA_ "GenSigSendType" SG_ 1556 CCUR_DiagRespData7 7;
BA_ "InvalidValue" SG_ 1556 CCUR_DiagRespData7 "null";
BA_ "GenSigSendType" SG_ 1562 EDS_R_DiagRespData0 7;
BA_ "InvalidValue" SG_ 1562 EDS_R_DiagRespData0 "null";
BA_ "GenSigSendType" SG_ 1562 EDS_R_DiagRespData1 7;
BA_ "InvalidValue" SG_ 1562 EDS_R_DiagRespData1 "null";
BA_ "GenSigSendType" SG_ 1562 EDS_R_DiagRespData2 7;
BA_ "InvalidValue" SG_ 1562 EDS_R_DiagRespData2 "null";
BA_ "GenSigSendType" SG_ 1562 EDS_R_DiagRespData3 7;
BA_ "InvalidValue" SG_ 1562 EDS_R_DiagRespData3 "null";
BA_ "GenSigSendType" SG_ 1562 EDS_R_DiagRespData4 7;
BA_ "InvalidValue" SG_ 1562 EDS_R_DiagRespData4 "null";
BA_ "GenSigSendType" SG_ 1562 EDS_R_DiagRespData5 7;
BA_ "InvalidValue" SG_ 1562 EDS_R_DiagRespData5 "null";
BA_ "GenSigSendType" SG_ 1562 EDS_R_DiagRespData6 7;
BA_ "InvalidValue" SG_ 1562 EDS_R_DiagRespData6 "null";
BA_ "GenSigSendType" SG_ 1562 EDS_R_DiagRespData7 7;
BA_ "InvalidValue" SG_ 1562 EDS_R_DiagRespData7 "null";
BA_ "GenSigSendType" SG_ 1563 EDS_F_DiagRespData0 7;
BA_ "InvalidValue" SG_ 1563 EDS_F_DiagRespData0 "null";
BA_ "GenSigSendType" SG_ 1563 EDS_F_DiagRespData1 7;
BA_ "InvalidValue" SG_ 1563 EDS_F_DiagRespData1 "null";
BA_ "GenSigSendType" SG_ 1563 EDS_F_DiagRespData2 7;
BA_ "InvalidValue" SG_ 1563 EDS_F_DiagRespData2 "null";
BA_ "GenSigSendType" SG_ 1563 EDS_F_DiagRespData3 7;
BA_ "InvalidValue" SG_ 1563 EDS_F_DiagRespData3 "null";
BA_ "GenSigSendType" SG_ 1563 EDS_F_DiagRespData4 7;
BA_ "InvalidValue" SG_ 1563 EDS_F_DiagRespData4 "null";
BA_ "GenSigSendType" SG_ 1563 EDS_F_DiagRespData5 7;
BA_ "InvalidValue" SG_ 1563 EDS_F_DiagRespData5 "null";
BA_ "GenSigSendType" SG_ 1563 EDS_F_DiagRespData6 7;
BA_ "InvalidValue" SG_ 1563 EDS_F_DiagRespData6 "null";
BA_ "GenSigSendType" SG_ 1563 EDS_F_DiagRespData7 7;
BA_ "InvalidValue" SG_ 1563 EDS_F_DiagRespData7 "null";
BA_ "GenSigSendType" SG_ 1566 PSM_D_DiagRespData0 7;
BA_ "InvalidValue" SG_ 1566 PSM_D_DiagRespData0 "null";
BA_ "GenSigSendType" SG_ 1566 PSM_D_DiagRespData1 7;
BA_ "InvalidValue" SG_ 1566 PSM_D_DiagRespData1 "null";
BA_ "GenSigSendType" SG_ 1566 PSM_D_DiagRespData2 7;
BA_ "InvalidValue" SG_ 1566 PSM_D_DiagRespData2 "null";
BA_ "GenSigSendType" SG_ 1566 PSM_D_DiagRespData3 7;
BA_ "InvalidValue" SG_ 1566 PSM_D_DiagRespData3 "null";
BA_ "GenSigSendType" SG_ 1566 PSM_D_DiagRespData4 7;
BA_ "InvalidValue" SG_ 1566 PSM_D_DiagRespData4 "null";
BA_ "GenSigSendType" SG_ 1566 PSM_D_DiagRespData5 7;
BA_ "InvalidValue" SG_ 1566 PSM_D_DiagRespData5 "null";
BA_ "GenSigSendType" SG_ 1566 PSM_D_DiagRespData6 7;
BA_ "InvalidValue" SG_ 1566 PSM_D_DiagRespData6 "null";
BA_ "GenSigSendType" SG_ 1566 PSM_D_DiagRespData7 7;
BA_ "InvalidValue" SG_ 1566 PSM_D_DiagRespData7 "null";
BA_ "GenSigSendType" SG_ 1573 MRGEN_DiagRespData0 7;
BA_ "InvalidValue" SG_ 1573 MRGEN_DiagRespData0 "null";
BA_ "GenSigSendType" SG_ 1573 MRGEN_DiagRespData1 7;
BA_ "InvalidValue" SG_ 1573 MRGEN_DiagRespData1 "null";
BA_ "GenSigSendType" SG_ 1573 MRGEN_DiagRespData2 7;
BA_ "InvalidValue" SG_ 1573 MRGEN_DiagRespData2 "null";
BA_ "GenSigSendType" SG_ 1573 MRGEN_DiagRespData3 7;
BA_ "InvalidValue" SG_ 1573 MRGEN_DiagRespData3 "null";
BA_ "GenSigSendType" SG_ 1573 MRGEN_DiagRespData4 7;
BA_ "InvalidValue" SG_ 1573 MRGEN_DiagRespData4 "null";
BA_ "GenSigSendType" SG_ 1573 MRGEN_DiagRespData5 7;
BA_ "InvalidValue" SG_ 1573 MRGEN_DiagRespData5 "null";
BA_ "GenSigSendType" SG_ 1573 MRGEN_DiagRespData6 7;
BA_ "InvalidValue" SG_ 1573 MRGEN_DiagRespData6 "null";
BA_ "GenSigSendType" SG_ 1573 MRGEN_DiagRespData7 7;
BA_ "InvalidValue" SG_ 1573 MRGEN_DiagRespData7 "null";
BA_ "GenSigSendType" SG_ 1574 SCAM_DiagRespData0 7;
BA_ "InvalidValue" SG_ 1574 SCAM_DiagRespData0 "null";
BA_ "GenSigSendType" SG_ 1574 SCAM_DiagRespData1 7;
BA_ "InvalidValue" SG_ 1574 SCAM_DiagRespData1 "null";
BA_ "GenSigSendType" SG_ 1574 SCAM_DiagRespData2 7;
BA_ "InvalidValue" SG_ 1574 SCAM_DiagRespData2 "null";
BA_ "GenSigSendType" SG_ 1574 SCAM_DiagRespData3 7;
BA_ "InvalidValue" SG_ 1574 SCAM_DiagRespData3 "null";
BA_ "GenSigSendType" SG_ 1574 SCAM_DiagRespData4 7;
BA_ "InvalidValue" SG_ 1574 SCAM_DiagRespData4 "null";
BA_ "GenSigSendType" SG_ 1574 SCAM_DiagRespData5 7;
BA_ "InvalidValue" SG_ 1574 SCAM_DiagRespData5 "null";
BA_ "GenSigSendType" SG_ 1574 SCAM_DiagRespData6 7;
BA_ "InvalidValue" SG_ 1574 SCAM_DiagRespData6 "null";
BA_ "GenSigSendType" SG_ 1574 SCAM_DiagRespData7 7;
BA_ "InvalidValue" SG_ 1574 SCAM_DiagRespData7 "null";
BA_ "GenSigSendType" SG_ 1575 RCU_DiagRespData0 7;
BA_ "InvalidValue" SG_ 1575 RCU_DiagRespData0 "null";
BA_ "GenSigSendType" SG_ 1575 RCU_DiagRespData1 7;
BA_ "InvalidValue" SG_ 1575 RCU_DiagRespData1 "null";
BA_ "GenSigSendType" SG_ 1575 RCU_DiagRespData2 7;
BA_ "InvalidValue" SG_ 1575 RCU_DiagRespData2 "null";
BA_ "GenSigSendType" SG_ 1575 RCU_DiagRespData3 7;
BA_ "InvalidValue" SG_ 1575 RCU_DiagRespData3 "null";
BA_ "GenSigSendType" SG_ 1575 RCU_DiagRespData4 7;
BA_ "InvalidValue" SG_ 1575 RCU_DiagRespData4 "null";
BA_ "GenSigSendType" SG_ 1575 RCU_DiagRespData5 7;
BA_ "InvalidValue" SG_ 1575 RCU_DiagRespData5 "null";
BA_ "GenSigSendType" SG_ 1575 RCU_DiagRespData6 7;
BA_ "InvalidValue" SG_ 1575 RCU_DiagRespData6 "null";
BA_ "GenSigSendType" SG_ 1575 RCU_DiagRespData7 7;
BA_ "InvalidValue" SG_ 1575 RCU_DiagRespData7 "null";
BA_ "GenSigSendType" SG_ 1576 EPS_DiagRespData0 7;
BA_ "InvalidValue" SG_ 1576 EPS_DiagRespData0 "null";
BA_ "GenSigSendType" SG_ 1576 EPS_DiagRespData1 7;
BA_ "InvalidValue" SG_ 1576 EPS_DiagRespData1 "null";
BA_ "GenSigSendType" SG_ 1576 EPS_DiagRespData2 7;
BA_ "InvalidValue" SG_ 1576 EPS_DiagRespData2 "null";
BA_ "GenSigSendType" SG_ 1576 EPS_DiagRespData3 7;
BA_ "InvalidValue" SG_ 1576 EPS_DiagRespData3 "null";
BA_ "GenSigSendType" SG_ 1576 EPS_DiagRespData4 7;
BA_ "InvalidValue" SG_ 1576 EPS_DiagRespData4 "null";
BA_ "GenSigSendType" SG_ 1576 EPS_DiagRespData5 7;
BA_ "InvalidValue" SG_ 1576 EPS_DiagRespData5 "null";
BA_ "GenSigSendType" SG_ 1576 EPS_DiagRespData6 7;
BA_ "InvalidValue" SG_ 1576 EPS_DiagRespData6 "null";
BA_ "GenSigSendType" SG_ 1576 EPS_DiagRespData7 7;
BA_ "InvalidValue" SG_ 1576 EPS_DiagRespData7 "null";
BA_ "GenSigSendType" SG_ 1577 IDB_DiagRespData0 7;
BA_ "InvalidValue" SG_ 1577 IDB_DiagRespData0 "null";
BA_ "GenSigSendType" SG_ 1577 IDB_DiagRespData1 7;
BA_ "InvalidValue" SG_ 1577 IDB_DiagRespData1 "null";
BA_ "GenSigSendType" SG_ 1577 IDB_DiagRespData2 7;
BA_ "InvalidValue" SG_ 1577 IDB_DiagRespData2 "null";
BA_ "GenSigSendType" SG_ 1577 IDB_DiagRespData3 7;
BA_ "InvalidValue" SG_ 1577 IDB_DiagRespData3 "null";
BA_ "GenSigSendType" SG_ 1577 IDB_DiagRespData4 7;
BA_ "InvalidValue" SG_ 1577 IDB_DiagRespData4 "null";
BA_ "GenSigSendType" SG_ 1577 IDB_DiagRespData5 7;
BA_ "InvalidValue" SG_ 1577 IDB_DiagRespData5 "null";
BA_ "GenSigSendType" SG_ 1577 IDB_DiagRespData6 7;
BA_ "InvalidValue" SG_ 1577 IDB_DiagRespData6 "null";
BA_ "GenSigSendType" SG_ 1577 IDB_DiagRespData7 7;
BA_ "InvalidValue" SG_ 1577 IDB_DiagRespData7 "null";
BA_ "GenSigSendType" SG_ 1578 AVAS_DiagRespData0 7;
BA_ "InvalidValue" SG_ 1578 AVAS_DiagRespData0 "null";
BA_ "GenSigSendType" SG_ 1578 AVAS_DiagRespData1 7;
BA_ "InvalidValue" SG_ 1578 AVAS_DiagRespData1 "null";
BA_ "GenSigSendType" SG_ 1578 AVAS_DiagRespData2 7;
BA_ "InvalidValue" SG_ 1578 AVAS_DiagRespData2 "null";
BA_ "GenSigSendType" SG_ 1578 AVAS_DiagRespData3 7;
BA_ "InvalidValue" SG_ 1578 AVAS_DiagRespData3 "null";
BA_ "GenSigSendType" SG_ 1578 AVAS_DiagRespData4 7;
BA_ "InvalidValue" SG_ 1578 AVAS_DiagRespData4 "null";
BA_ "GenSigSendType" SG_ 1578 AVAS_DiagRespData5 7;
BA_ "InvalidValue" SG_ 1578 AVAS_DiagRespData5 "null";
BA_ "GenSigSendType" SG_ 1578 AVAS_DiagRespData6 7;
BA_ "InvalidValue" SG_ 1578 AVAS_DiagRespData6 "null";
BA_ "GenSigSendType" SG_ 1578 AVAS_DiagRespData7 7;
BA_ "InvalidValue" SG_ 1578 AVAS_DiagRespData7 "null";
BA_ "GenSigSendType" SG_ 1579 EPS2_DiagRespData0 7;
BA_ "InvalidValue" SG_ 1579 EPS2_DiagRespData0 "null";
BA_ "GenSigSendType" SG_ 1579 EPS2_DiagRespData1 7;
BA_ "InvalidValue" SG_ 1579 EPS2_DiagRespData1 "null";
BA_ "GenSigSendType" SG_ 1579 EPS2_DiagRespData2 7;
BA_ "InvalidValue" SG_ 1579 EPS2_DiagRespData2 "null";
BA_ "GenSigSendType" SG_ 1579 EPS2_DiagRespData3 7;
BA_ "InvalidValue" SG_ 1579 EPS2_DiagRespData3 "null";
BA_ "GenSigSendType" SG_ 1579 EPS2_DiagRespData4 7;
BA_ "InvalidValue" SG_ 1579 EPS2_DiagRespData4 "null";
BA_ "GenSigSendType" SG_ 1579 EPS2_DiagRespData5 7;
BA_ "InvalidValue" SG_ 1579 EPS2_DiagRespData5 "null";
BA_ "GenSigSendType" SG_ 1579 EPS2_DiagRespData6 7;
BA_ "InvalidValue" SG_ 1579 EPS2_DiagRespData6 "null";
BA_ "GenSigSendType" SG_ 1579 EPS2_DiagRespData7 7;
BA_ "InvalidValue" SG_ 1579 EPS2_DiagRespData7 "null";
BA_ "GenSigSendType" SG_ 1580 VCU_DiagRespData0 7;
BA_ "InvalidValue" SG_ 1580 VCU_DiagRespData0 "null";
BA_ "GenSigSendType" SG_ 1580 VCU_DiagRespData1 7;
BA_ "InvalidValue" SG_ 1580 VCU_DiagRespData1 "null";
BA_ "GenSigSendType" SG_ 1580 VCU_DiagRespData2 7;
BA_ "InvalidValue" SG_ 1580 VCU_DiagRespData2 "null";
BA_ "GenSigSendType" SG_ 1580 VCU_DiagRespData3 7;
BA_ "InvalidValue" SG_ 1580 VCU_DiagRespData3 "null";
BA_ "GenSigSendType" SG_ 1580 VCU_DiagRespData4 7;
BA_ "InvalidValue" SG_ 1580 VCU_DiagRespData4 "null";
BA_ "GenSigSendType" SG_ 1580 VCU_DiagRespData5 7;
BA_ "InvalidValue" SG_ 1580 VCU_DiagRespData5 "null";
BA_ "GenSigSendType" SG_ 1580 VCU_DiagRespData6 7;
BA_ "InvalidValue" SG_ 1580 VCU_DiagRespData6 "null";
BA_ "GenSigSendType" SG_ 1580 VCU_DiagRespData7 7;
BA_ "InvalidValue" SG_ 1580 VCU_DiagRespData7 "null";
BA_ "GenSigSendType" SG_ 1581 CPD_2_DiagRespData0 7;
BA_ "GenSigSendType" SG_ 1581 CPD_2_DiagRespData1 7;
BA_ "GenSigSendType" SG_ 1581 CPD_2_DiagRespData2 7;
BA_ "GenSigSendType" SG_ 1581 CPD_2_DiagRespData3 7;
BA_ "GenSigSendType" SG_ 1581 CPD_2_DiagRespData4 7;
BA_ "GenSigSendType" SG_ 1581 CPD_2_DiagRespData5 7;
BA_ "GenSigSendType" SG_ 1581 CPD_2_DiagRespData6 7;
BA_ "GenSigSendType" SG_ 1581 CPD_2_DiagRespData7 7;
BA_ "GenSigSendType" SG_ 1582 EASC_DiagRespData0 7;
BA_ "InvalidValue" SG_ 1582 EASC_DiagRespData0 "null";
BA_ "GenSigSendType" SG_ 1582 EASC_DiagRespData1 7;
BA_ "InvalidValue" SG_ 1582 EASC_DiagRespData1 "null";
BA_ "GenSigSendType" SG_ 1582 EASC_DiagRespData2 7;
BA_ "InvalidValue" SG_ 1582 EASC_DiagRespData2 "null";
BA_ "GenSigSendType" SG_ 1582 EASC_DiagRespData3 7;
BA_ "InvalidValue" SG_ 1582 EASC_DiagRespData3 "null";
BA_ "GenSigSendType" SG_ 1582 EASC_DiagRespData4 7;
BA_ "InvalidValue" SG_ 1582 EASC_DiagRespData4 "null";
BA_ "GenSigSendType" SG_ 1582 EASC_DiagRespData5 7;
BA_ "InvalidValue" SG_ 1582 EASC_DiagRespData5 "null";
BA_ "GenSigSendType" SG_ 1582 EASC_DiagRespData6 7;
BA_ "InvalidValue" SG_ 1582 EASC_DiagRespData6 "null";
BA_ "GenSigSendType" SG_ 1582 EASC_DiagRespData7 7;
BA_ "InvalidValue" SG_ 1582 EASC_DiagRespData7 "null";
BA_ "GenSigSendType" SG_ 1583 CPD_DiagRespData0 7;
BA_ "InvalidValue" SG_ 1583 CPD_DiagRespData0 "null";
BA_ "GenSigSendType" SG_ 1583 CPD_DiagRespData1 7;
BA_ "InvalidValue" SG_ 1583 CPD_DiagRespData1 "null";
BA_ "GenSigSendType" SG_ 1583 CPD_DiagRespData2 7;
BA_ "InvalidValue" SG_ 1583 CPD_DiagRespData2 "null";
BA_ "GenSigSendType" SG_ 1583 CPD_DiagRespData3 7;
BA_ "InvalidValue" SG_ 1583 CPD_DiagRespData3 "null";
BA_ "GenSigSendType" SG_ 1583 CPD_DiagRespData4 7;
BA_ "InvalidValue" SG_ 1583 CPD_DiagRespData4 "null";
BA_ "GenSigSendType" SG_ 1583 CPD_DiagRespData5 7;
BA_ "InvalidValue" SG_ 1583 CPD_DiagRespData5 "null";
BA_ "GenSigSendType" SG_ 1583 CPD_DiagRespData6 7;
BA_ "InvalidValue" SG_ 1583 CPD_DiagRespData6 "null";
BA_ "GenSigSendType" SG_ 1583 CPD_DiagRespData7 7;
BA_ "InvalidValue" SG_ 1583 CPD_DiagRespData7 "null";
BA_ "GenSigSendType" SG_ 1588 SRR_FR_DiagRespData0 7;
BA_ "GenSigSendType" SG_ 1588 SRR_FR_DiagRespData1 7;
BA_ "GenSigSendType" SG_ 1588 SRR_FR_DiagRespData2 7;
BA_ "GenSigSendType" SG_ 1588 SRR_FR_DiagRespData3 7;
BA_ "GenSigSendType" SG_ 1588 SRR_FR_DiagRespData4 7;
BA_ "GenSigSendType" SG_ 1588 SRR_FR_DiagRespData5 7;
BA_ "GenSigSendType" SG_ 1588 SRR_FR_DiagRespData6 7;
BA_ "GenSigSendType" SG_ 1588 SRR_FR_DiagRespData7 7;
BA_ "GenSigSendType" SG_ 1589 SRR_FL_DiagRespData0 7;
BA_ "GenSigSendType" SG_ 1589 SRR_FL_DiagRespData1 7;
BA_ "GenSigSendType" SG_ 1589 SRR_FL_DiagRespData2 7;
BA_ "GenSigSendType" SG_ 1589 SRR_FL_DiagRespData3 7;
BA_ "GenSigSendType" SG_ 1589 SRR_FL_DiagRespData4 7;
BA_ "GenSigSendType" SG_ 1589 SRR_FL_DiagRespData5 7;
BA_ "GenSigSendType" SG_ 1589 SRR_FL_DiagRespData6 7;
BA_ "GenSigSendType" SG_ 1589 SRR_FL_DiagRespData7 7;
BA_ "GenSigSendType" SG_ 1590 SRR_RR_DiagRespData0 7;
BA_ "GenSigSendType" SG_ 1590 SRR_RR_DiagRespData1 7;
BA_ "GenSigSendType" SG_ 1590 SRR_RR_DiagRespData2 7;
BA_ "GenSigSendType" SG_ 1590 SRR_RR_DiagRespData3 7;
BA_ "GenSigSendType" SG_ 1590 SRR_RR_DiagRespData4 7;
BA_ "GenSigSendType" SG_ 1590 SRR_RR_DiagRespData5 7;
BA_ "GenSigSendType" SG_ 1590 SRR_RR_DiagRespData6 7;
BA_ "GenSigSendType" SG_ 1590 SRR_RR_DiagRespData7 7;
BA_ "GenSigSendType" SG_ 1591 SRR_RL_DiagRespData0 7;
BA_ "GenSigSendType" SG_ 1591 SRR_RL_DiagRespData1 7;
BA_ "GenSigSendType" SG_ 1591 SRR_RL_DiagRespData2 7;
BA_ "GenSigSendType" SG_ 1591 SRR_RL_DiagRespData3 7;
BA_ "GenSigSendType" SG_ 1591 SRR_RL_DiagRespData4 7;
BA_ "GenSigSendType" SG_ 1591 SRR_RL_DiagRespData5 7;
BA_ "GenSigSendType" SG_ 1591 SRR_RL_DiagRespData6 7;
BA_ "GenSigSendType" SG_ 1591 SRR_RL_DiagRespData7 7;
BA_ "GenSigSendType" SG_ 1592 ASU_DiagRespData0 7;
BA_ "GenSigSendType" SG_ 1592 ASU_DiagRespData1 7;
BA_ "GenSigSendType" SG_ 1592 ASU_DiagRespData2 7;
BA_ "GenSigSendType" SG_ 1592 ASU_DiagRespData3 7;
BA_ "GenSigSendType" SG_ 1592 ASU_DiagRespData4 7;
BA_ "GenSigSendType" SG_ 1592 ASU_DiagRespData5 7;
BA_ "GenSigSendType" SG_ 1592 ASU_DiagRespData6 7;
BA_ "GenSigSendType" SG_ 1592 ASU_DiagRespData7 7;
BA_ "GenSigSendType" SG_ 1595 TRM_DiagRespData0 7;
BA_ "InvalidValue" SG_ 1595 TRM_DiagRespData0 "null";
BA_ "GenSigSendType" SG_ 1595 TRM_DiagRespData1 7;
BA_ "InvalidValue" SG_ 1595 TRM_DiagRespData1 "null";
BA_ "GenSigSendType" SG_ 1595 TRM_DiagRespData2 7;
BA_ "InvalidValue" SG_ 1595 TRM_DiagRespData2 "null";
BA_ "GenSigSendType" SG_ 1595 TRM_DiagRespData3 7;
BA_ "InvalidValue" SG_ 1595 TRM_DiagRespData3 "null";
BA_ "GenSigSendType" SG_ 1595 TRM_DiagRespData4 7;
BA_ "InvalidValue" SG_ 1595 TRM_DiagRespData4 "null";
BA_ "GenSigSendType" SG_ 1595 TRM_DiagRespData5 7;
BA_ "InvalidValue" SG_ 1595 TRM_DiagRespData5 "null";
BA_ "GenSigSendType" SG_ 1595 TRM_DiagRespData6 7;
BA_ "InvalidValue" SG_ 1595 TRM_DiagRespData6 "null";
BA_ "GenSigSendType" SG_ 1595 TRM_DiagRespData7 7;
BA_ "InvalidValue" SG_ 1595 TRM_DiagRespData7 "null";
BA_ "GenSigSendType" SG_ 1597 POD_DCDC_DiagRespData0 7;
BA_ "InvalidValue" SG_ 1597 POD_DCDC_DiagRespData0 "null";
BA_ "GenSigSendType" SG_ 1597 POD_DCDC_DiagRespData1 7;
BA_ "InvalidValue" SG_ 1597 POD_DCDC_DiagRespData1 "null";
BA_ "GenSigSendType" SG_ 1597 POD_DCDC_DiagRespData2 7;
BA_ "InvalidValue" SG_ 1597 POD_DCDC_DiagRespData2 "null";
BA_ "GenSigSendType" SG_ 1597 POD_DCDC_DiagRespData3 7;
BA_ "InvalidValue" SG_ 1597 POD_DCDC_DiagRespData3 "null";
BA_ "GenSigSendType" SG_ 1597 POD_DCDC_DiagRespData4 7;
BA_ "InvalidValue" SG_ 1597 POD_DCDC_DiagRespData4 "null";
BA_ "GenSigSendType" SG_ 1597 POD_DCDC_DiagRespData5 7;
BA_ "InvalidValue" SG_ 1597 POD_DCDC_DiagRespData5 "null";
BA_ "GenSigSendType" SG_ 1597 POD_DCDC_DiagRespData6 7;
BA_ "InvalidValue" SG_ 1597 POD_DCDC_DiagRespData6 "null";
BA_ "GenSigSendType" SG_ 1597 POD_DCDC_DiagRespData7 7;
BA_ "InvalidValue" SG_ 1597 POD_DCDC_DiagRespData7 "null";
BA_ "GenSigSendType" SG_ 1598 POD_OBC_DiagRespData0 7;
BA_ "InvalidValue" SG_ 1598 POD_OBC_DiagRespData0 "null";
BA_ "GenSigSendType" SG_ 1598 POD_OBC_DiagRespData1 7;
BA_ "InvalidValue" SG_ 1598 POD_OBC_DiagRespData1 "null";
BA_ "GenSigSendType" SG_ 1598 POD_OBC_DiagRespData2 7;
BA_ "InvalidValue" SG_ 1598 POD_OBC_DiagRespData2 "null";
BA_ "GenSigSendType" SG_ 1598 POD_OBC_DiagRespData3 7;
BA_ "InvalidValue" SG_ 1598 POD_OBC_DiagRespData3 "null";
BA_ "GenSigSendType" SG_ 1598 POD_OBC_DiagRespData4 7;
BA_ "InvalidValue" SG_ 1598 POD_OBC_DiagRespData4 "null";
BA_ "GenSigSendType" SG_ 1598 POD_OBC_DiagRespData5 7;
BA_ "InvalidValue" SG_ 1598 POD_OBC_DiagRespData5 "null";
BA_ "GenSigSendType" SG_ 1598 POD_OBC_DiagRespData6 7;
BA_ "InvalidValue" SG_ 1598 POD_OBC_DiagRespData6 "null";
BA_ "GenSigSendType" SG_ 1598 POD_OBC_DiagRespData7 7;
BA_ "InvalidValue" SG_ 1598 POD_OBC_DiagRespData7 "null";
BA_ "GenSigSendType" SG_ 1599 POD_DiagRespData0 7;
BA_ "InvalidValue" SG_ 1599 POD_DiagRespData0 "null";
BA_ "GenSigSendType" SG_ 1599 POD_DiagRespData1 7;
BA_ "InvalidValue" SG_ 1599 POD_DiagRespData1 "null";
BA_ "GenSigSendType" SG_ 1599 POD_DiagRespData2 7;
BA_ "InvalidValue" SG_ 1599 POD_DiagRespData2 "null";
BA_ "GenSigSendType" SG_ 1599 POD_DiagRespData3 7;
BA_ "InvalidValue" SG_ 1599 POD_DiagRespData3 "null";
BA_ "GenSigSendType" SG_ 1599 POD_DiagRespData4 7;
BA_ "InvalidValue" SG_ 1599 POD_DiagRespData4 "null";
BA_ "GenSigSendType" SG_ 1599 POD_DiagRespData5 7;
BA_ "InvalidValue" SG_ 1599 POD_DiagRespData5 "null";
BA_ "GenSigSendType" SG_ 1599 POD_DiagRespData6 7;
BA_ "InvalidValue" SG_ 1599 POD_DiagRespData6 "null";
BA_ "GenSigSendType" SG_ 1599 POD_DiagRespData7 7;
BA_ "InvalidValue" SG_ 1599 POD_DiagRespData7 "null";
BA_ "GenSigSendType" SG_ 1600 ADAS_DiagRespData0 7;
BA_ "InvalidValue" SG_ 1600 ADAS_DiagRespData0 "null";
BA_ "GenSigSendType" SG_ 1600 ADAS_DiagRespData1 7;
BA_ "InvalidValue" SG_ 1600 ADAS_DiagRespData1 "null";
BA_ "GenSigSendType" SG_ 1600 ADAS_DiagRespData2 7;
BA_ "InvalidValue" SG_ 1600 ADAS_DiagRespData2 "null";
BA_ "GenSigSendType" SG_ 1600 ADAS_DiagRespData3 7;
BA_ "InvalidValue" SG_ 1600 ADAS_DiagRespData3 "null";
BA_ "GenSigSendType" SG_ 1600 ADAS_DiagRespData4 7;
BA_ "InvalidValue" SG_ 1600 ADAS_DiagRespData4 "null";
BA_ "GenSigSendType" SG_ 1600 ADAS_DiagRespData5 7;
BA_ "InvalidValue" SG_ 1600 ADAS_DiagRespData5 "null";
BA_ "GenSigSendType" SG_ 1600 ADAS_DiagRespData6 7;
BA_ "InvalidValue" SG_ 1600 ADAS_DiagRespData6 "null";
BA_ "GenSigSendType" SG_ 1600 ADAS_DiagRespData7 7;
BA_ "InvalidValue" SG_ 1600 ADAS_DiagRespData7 "null";
BA_ "GenSigSendType" SG_ 1601 APM_DiagRespData0 7;
BA_ "InvalidValue" SG_ 1601 APM_DiagRespData0 "null";
BA_ "GenSigSendType" SG_ 1601 APM_DiagRespData1 7;
BA_ "InvalidValue" SG_ 1601 APM_DiagRespData1 "null";
BA_ "GenSigSendType" SG_ 1601 APM_DiagRespData2 7;
BA_ "InvalidValue" SG_ 1601 APM_DiagRespData2 "null";
BA_ "GenSigSendType" SG_ 1601 APM_DiagRespData3 7;
BA_ "InvalidValue" SG_ 1601 APM_DiagRespData3 "null";
BA_ "GenSigSendType" SG_ 1601 APM_DiagRespData4 7;
BA_ "InvalidValue" SG_ 1601 APM_DiagRespData4 "null";
BA_ "GenSigSendType" SG_ 1601 APM_DiagRespData5 7;
BA_ "InvalidValue" SG_ 1601 APM_DiagRespData5 "null";
BA_ "GenSigSendType" SG_ 1601 APM_DiagRespData6 7;
BA_ "InvalidValue" SG_ 1601 APM_DiagRespData6 "null";
BA_ "GenSigSendType" SG_ 1601 APM_DiagRespData7 7;
BA_ "InvalidValue" SG_ 1601 APM_DiagRespData7 "null";
BA_ "GenSigSendType" SG_ 1602 SHVU_F_DiagRespData0 7;
BA_ "InvalidValue" SG_ 1602 SHVU_F_DiagRespData0 "null";
BA_ "GenSigSendType" SG_ 1602 SHVU_F_DiagRespData1 7;
BA_ "InvalidValue" SG_ 1602 SHVU_F_DiagRespData1 "null";
BA_ "GenSigSendType" SG_ 1602 SHVU_F_DiagRespData2 7;
BA_ "InvalidValue" SG_ 1602 SHVU_F_DiagRespData2 "null";
BA_ "GenSigSendType" SG_ 1602 SHVU_F_DiagRespData3 7;
BA_ "InvalidValue" SG_ 1602 SHVU_F_DiagRespData3 "null";
BA_ "GenSigSendType" SG_ 1602 SHVU_F_DiagRespData4 7;
BA_ "InvalidValue" SG_ 1602 SHVU_F_DiagRespData4 "null";
BA_ "GenSigSendType" SG_ 1602 SHVU_F_DiagRespData5 7;
BA_ "InvalidValue" SG_ 1602 SHVU_F_DiagRespData5 "null";
BA_ "GenSigSendType" SG_ 1602 SHVU_F_DiagRespData6 7;
BA_ "InvalidValue" SG_ 1602 SHVU_F_DiagRespData6 "null";
BA_ "GenSigSendType" SG_ 1602 SHVU_F_DiagRespData7 7;
BA_ "InvalidValue" SG_ 1602 SHVU_F_DiagRespData7 "null";
BA_ "GenSigSendType" SG_ 1603 SHVU_R_DiagRespData0 7;
BA_ "InvalidValue" SG_ 1603 SHVU_R_DiagRespData0 "null";
BA_ "GenSigSendType" SG_ 1603 SHVU_R_DiagRespData1 7;
BA_ "InvalidValue" SG_ 1603 SHVU_R_DiagRespData1 "null";
BA_ "GenSigSendType" SG_ 1603 SHVU_R_DiagRespData2 7;
BA_ "InvalidValue" SG_ 1603 SHVU_R_DiagRespData2 "null";
BA_ "GenSigSendType" SG_ 1603 SHVU_R_DiagRespData3 7;
BA_ "InvalidValue" SG_ 1603 SHVU_R_DiagRespData3 "null";
BA_ "GenSigSendType" SG_ 1603 SHVU_R_DiagRespData4 7;
BA_ "InvalidValue" SG_ 1603 SHVU_R_DiagRespData4 "null";
BA_ "GenSigSendType" SG_ 1603 SHVU_R_DiagRespData5 7;
BA_ "InvalidValue" SG_ 1603 SHVU_R_DiagRespData5 "null";
BA_ "GenSigSendType" SG_ 1603 SHVU_R_DiagRespData6 7;
BA_ "InvalidValue" SG_ 1603 SHVU_R_DiagRespData6 "null";
BA_ "GenSigSendType" SG_ 1603 SHVU_R_DiagRespData7 7;
BA_ "InvalidValue" SG_ 1603 SHVU_R_DiagRespData7 "null";
BA_ "GenSigSendType" SG_ 1604 OCS_P_DiagRespData0 7;
BA_ "InvalidValue" SG_ 1604 OCS_P_DiagRespData0 "null";
BA_ "GenSigSendType" SG_ 1604 OCS_P_DiagRespData1 7;
BA_ "InvalidValue" SG_ 1604 OCS_P_DiagRespData1 "null";
BA_ "GenSigSendType" SG_ 1604 OCS_P_DiagRespData2 7;
BA_ "InvalidValue" SG_ 1604 OCS_P_DiagRespData2 "null";
BA_ "GenSigSendType" SG_ 1604 OCS_P_DiagRespData3 7;
BA_ "InvalidValue" SG_ 1604 OCS_P_DiagRespData3 "null";
BA_ "GenSigSendType" SG_ 1604 OCS_P_DiagRespData4 7;
BA_ "InvalidValue" SG_ 1604 OCS_P_DiagRespData4 "null";
BA_ "GenSigSendType" SG_ 1604 OCS_P_DiagRespData5 7;
BA_ "InvalidValue" SG_ 1604 OCS_P_DiagRespData5 "null";
BA_ "GenSigSendType" SG_ 1604 OCS_P_DiagRespData6 7;
BA_ "InvalidValue" SG_ 1604 OCS_P_DiagRespData6 "null";
BA_ "GenSigSendType" SG_ 1604 OCS_P_DiagRespData7 7;
BA_ "InvalidValue" SG_ 1604 OCS_P_DiagRespData7 "null";
BA_ "GenSigSendType" SG_ 1609 LDM_L_DiagRespData0 7;
BA_ "InvalidValue" SG_ 1609 LDM_L_DiagRespData0 "null";
BA_ "GenSigSendType" SG_ 1609 LDM_L_DiagRespData1 7;
BA_ "InvalidValue" SG_ 1609 LDM_L_DiagRespData1 "null";
BA_ "GenSigSendType" SG_ 1609 LDM_L_DiagRespData2 7;
BA_ "InvalidValue" SG_ 1609 LDM_L_DiagRespData2 "null";
BA_ "GenSigSendType" SG_ 1609 LDM_L_DiagRespData3 7;
BA_ "InvalidValue" SG_ 1609 LDM_L_DiagRespData3 "null";
BA_ "GenSigSendType" SG_ 1609 LDM_L_DiagRespData4 7;
BA_ "InvalidValue" SG_ 1609 LDM_L_DiagRespData4 "null";
BA_ "GenSigSendType" SG_ 1609 LDM_L_DiagRespData5 7;
BA_ "InvalidValue" SG_ 1609 LDM_L_DiagRespData5 "null";
BA_ "GenSigSendType" SG_ 1609 LDM_L_DiagRespData6 7;
BA_ "InvalidValue" SG_ 1609 LDM_L_DiagRespData6 "null";
BA_ "GenSigSendType" SG_ 1609 LDM_L_DiagRespData7 7;
BA_ "InvalidValue" SG_ 1609 LDM_L_DiagRespData7 "null";
BA_ "GenSigSendType" SG_ 1610 LDM_R_DiagRespData0 7;
BA_ "InvalidValue" SG_ 1610 LDM_R_DiagRespData0 "null";
BA_ "GenSigSendType" SG_ 1610 LDM_R_DiagRespData1 7;
BA_ "InvalidValue" SG_ 1610 LDM_R_DiagRespData1 "null";
BA_ "GenSigSendType" SG_ 1610 LDM_R_DiagRespData2 7;
BA_ "InvalidValue" SG_ 1610 LDM_R_DiagRespData2 "null";
BA_ "GenSigSendType" SG_ 1610 LDM_R_DiagRespData3 7;
BA_ "InvalidValue" SG_ 1610 LDM_R_DiagRespData3 "null";
BA_ "GenSigSendType" SG_ 1610 LDM_R_DiagRespData4 7;
BA_ "InvalidValue" SG_ 1610 LDM_R_DiagRespData4 "null";
BA_ "GenSigSendType" SG_ 1610 LDM_R_DiagRespData5 7;
BA_ "InvalidValue" SG_ 1610 LDM_R_DiagRespData5 "null";
BA_ "GenSigSendType" SG_ 1610 LDM_R_DiagRespData6 7;
BA_ "InvalidValue" SG_ 1610 LDM_R_DiagRespData6 "null";
BA_ "GenSigSendType" SG_ 1610 LDM_R_DiagRespData7 7;
BA_ "InvalidValue" SG_ 1610 LDM_R_DiagRespData7 "null";
BA_ "GenSigSendType" SG_ 1624 BAS_DiagRespData0 7;
BA_ "InvalidValue" SG_ 1624 BAS_DiagRespData0 "null";
BA_ "GenSigSendType" SG_ 1624 BAS_DiagRespData1 7;
BA_ "InvalidValue" SG_ 1624 BAS_DiagRespData1 "null";
BA_ "GenSigSendType" SG_ 1624 BAS_DiagRespData2 7;
BA_ "InvalidValue" SG_ 1624 BAS_DiagRespData2 "null";
BA_ "GenSigSendType" SG_ 1624 BAS_DiagRespData3 7;
BA_ "InvalidValue" SG_ 1624 BAS_DiagRespData3 "null";
BA_ "GenSigSendType" SG_ 1624 BAS_DiagRespData4 7;
BA_ "InvalidValue" SG_ 1624 BAS_DiagRespData4 "null";
BA_ "GenSigSendType" SG_ 1624 BAS_DiagRespData5 7;
BA_ "InvalidValue" SG_ 1624 BAS_DiagRespData5 "null";
BA_ "GenSigSendType" SG_ 1624 BAS_DiagRespData6 7;
BA_ "InvalidValue" SG_ 1624 BAS_DiagRespData6 "null";
BA_ "GenSigSendType" SG_ 1624 BAS_DiagRespData7 7;
BA_ "InvalidValue" SG_ 1624 BAS_DiagRespData7 "null";
BA_ "GenSigSendType" SG_ 1636 DCM_APM_DiagRespData0 7;
BA_ "InvalidValue" SG_ 1636 DCM_APM_DiagRespData0 "null";
BA_ "GenSigSendType" SG_ 1636 DCM_APM_DiagRespData1 7;
BA_ "InvalidValue" SG_ 1636 DCM_APM_DiagRespData1 "null";
BA_ "GenSigSendType" SG_ 1636 DCM_APM_DiagRespData2 7;
BA_ "InvalidValue" SG_ 1636 DCM_APM_DiagRespData2 "null";
BA_ "GenSigSendType" SG_ 1636 DCM_APM_DiagRespData3 7;
BA_ "InvalidValue" SG_ 1636 DCM_APM_DiagRespData3 "null";
BA_ "GenSigSendType" SG_ 1636 DCM_APM_DiagRespData4 7;
BA_ "InvalidValue" SG_ 1636 DCM_APM_DiagRespData4 "null";
BA_ "GenSigSendType" SG_ 1636 DCM_APM_DiagRespData5 7;
BA_ "InvalidValue" SG_ 1636 DCM_APM_DiagRespData5 "null";
BA_ "GenSigSendType" SG_ 1636 DCM_APM_DiagRespData6 7;
BA_ "InvalidValue" SG_ 1636 DCM_APM_DiagRespData6 "null";
BA_ "GenSigSendType" SG_ 1636 DCM_APM_DiagRespData7 7;
BA_ "InvalidValue" SG_ 1636 DCM_APM_DiagRespData7 "null";
BA_ "GenSigSendType" SG_ 1659 BCM_BPM_DiagRespData0 7;
BA_ "InvalidValue" SG_ 1659 BCM_BPM_DiagRespData0 "null";
BA_ "GenSigSendType" SG_ 1659 BCM_BPM_DiagRespData1 7;
BA_ "InvalidValue" SG_ 1659 BCM_BPM_DiagRespData1 "null";
BA_ "GenSigSendType" SG_ 1659 BCM_BPM_DiagRespData2 7;
BA_ "InvalidValue" SG_ 1659 BCM_BPM_DiagRespData2 "null";
BA_ "GenSigSendType" SG_ 1659 BCM_BPM_DiagRespData3 7;
BA_ "InvalidValue" SG_ 1659 BCM_BPM_DiagRespData3 "null";
BA_ "GenSigSendType" SG_ 1659 BCM_BPM_DiagRespData4 7;
BA_ "InvalidValue" SG_ 1659 BCM_BPM_DiagRespData4 "null";
BA_ "GenSigSendType" SG_ 1659 BCM_BPM_DiagRespData5 7;
BA_ "InvalidValue" SG_ 1659 BCM_BPM_DiagRespData5 "null";
BA_ "GenSigSendType" SG_ 1659 BCM_BPM_DiagRespData6 7;
BA_ "InvalidValue" SG_ 1659 BCM_BPM_DiagRespData6 "null";
BA_ "GenSigSendType" SG_ 1659 BCM_BPM_DiagRespData7 7;
BA_ "InvalidValue" SG_ 1659 BCM_BPM_DiagRespData7 "null";
BA_ "GenSigSendType" SG_ 1665 BCM_DiagReqData0 7;
BA_ "InvalidValue" SG_ 1665 BCM_DiagReqData0 "null";
BA_ "GenSigSendType" SG_ 1665 BCM_DiagReqData1 7;
BA_ "InvalidValue" SG_ 1665 BCM_DiagReqData1 "null";
BA_ "GenSigSendType" SG_ 1665 BCM_DiagReqData2 7;
BA_ "InvalidValue" SG_ 1665 BCM_DiagReqData2 "null";
BA_ "GenSigSendType" SG_ 1665 BCM_DiagReqData3 7;
BA_ "InvalidValue" SG_ 1665 BCM_DiagReqData3 "null";
BA_ "GenSigSendType" SG_ 1665 BCM_DiagReqData4 7;
BA_ "InvalidValue" SG_ 1665 BCM_DiagReqData4 "null";
BA_ "GenSigSendType" SG_ 1665 BCM_DiagReqData5 7;
BA_ "InvalidValue" SG_ 1665 BCM_DiagReqData5 "null";
BA_ "GenSigSendType" SG_ 1665 BCM_DiagReqData6 7;
BA_ "InvalidValue" SG_ 1665 BCM_DiagReqData6 "null";
BA_ "GenSigSendType" SG_ 1665 BCM_DiagReqData7 7;
BA_ "InvalidValue" SG_ 1665 BCM_DiagReqData7 "null";
BA_ "GenSigSendType" SG_ 1666 XGW_DiagReqData0 7;
BA_ "InvalidValue" SG_ 1666 XGW_DiagReqData0 "null";
BA_ "GenSigSendType" SG_ 1666 XGW_DiagReqData1 7;
BA_ "InvalidValue" SG_ 1666 XGW_DiagReqData1 "null";
BA_ "GenSigSendType" SG_ 1666 XGW_DiagReqData2 7;
BA_ "InvalidValue" SG_ 1666 XGW_DiagReqData2 "null";
BA_ "GenSigSendType" SG_ 1666 XGW_DiagReqData3 7;
BA_ "InvalidValue" SG_ 1666 XGW_DiagReqData3 "null";
BA_ "GenSigSendType" SG_ 1666 XGW_DiagReqData4 7;
BA_ "InvalidValue" SG_ 1666 XGW_DiagReqData4 "null";
BA_ "GenSigSendType" SG_ 1666 XGW_DiagReqData5 7;
BA_ "InvalidValue" SG_ 1666 XGW_DiagReqData5 "null";
BA_ "GenSigSendType" SG_ 1666 XGW_DiagReqData6 7;
BA_ "InvalidValue" SG_ 1666 XGW_DiagReqData6 "null";
BA_ "GenSigSendType" SG_ 1666 XGW_DiagReqData7 7;
BA_ "InvalidValue" SG_ 1666 XGW_DiagReqData7 "null";
BA_ "GenSigSendType" SG_ 1668 MHU_DiagReqData0 7;
BA_ "InvalidValue" SG_ 1668 MHU_DiagReqData0 "null";
BA_ "GenSigSendType" SG_ 1668 MHU_DiagReqData1 7;
BA_ "InvalidValue" SG_ 1668 MHU_DiagReqData1 "null";
BA_ "GenSigSendType" SG_ 1668 MHU_DiagReqData2 7;
BA_ "InvalidValue" SG_ 1668 MHU_DiagReqData2 "null";
BA_ "GenSigSendType" SG_ 1668 MHU_DiagReqData3 7;
BA_ "InvalidValue" SG_ 1668 MHU_DiagReqData3 "null";
BA_ "GenSigSendType" SG_ 1668 MHU_DiagReqData4 7;
BA_ "InvalidValue" SG_ 1668 MHU_DiagReqData4 "null";
BA_ "GenSigSendType" SG_ 1668 MHU_DiagReqData5 7;
BA_ "InvalidValue" SG_ 1668 MHU_DiagReqData5 "null";
BA_ "GenSigSendType" SG_ 1668 MHU_DiagReqData6 7;
BA_ "InvalidValue" SG_ 1668 MHU_DiagReqData6 "null";
BA_ "GenSigSendType" SG_ 1668 MHU_DiagReqData7 7;
BA_ "InvalidValue" SG_ 1668 MHU_DiagReqData7 "null";
BA_ "GenSigSendType" SG_ 1669 AMP_DiagReqData0 7;
BA_ "InvalidValue" SG_ 1669 AMP_DiagReqData0 "null";
BA_ "GenSigSendType" SG_ 1669 AMP_DiagReqData1 7;
BA_ "InvalidValue" SG_ 1669 AMP_DiagReqData1 "null";
BA_ "GenSigSendType" SG_ 1669 AMP_DiagReqData2 7;
BA_ "InvalidValue" SG_ 1669 AMP_DiagReqData2 "null";
BA_ "GenSigSendType" SG_ 1669 AMP_DiagReqData3 7;
BA_ "InvalidValue" SG_ 1669 AMP_DiagReqData3 "null";
BA_ "GenSigSendType" SG_ 1669 AMP_DiagReqData4 7;
BA_ "InvalidValue" SG_ 1669 AMP_DiagReqData4 "null";
BA_ "GenSigSendType" SG_ 1669 AMP_DiagReqData5 7;
BA_ "InvalidValue" SG_ 1669 AMP_DiagReqData5 "null";
BA_ "GenSigSendType" SG_ 1669 AMP_DiagReqData6 7;
BA_ "InvalidValue" SG_ 1669 AMP_DiagReqData6 "null";
BA_ "GenSigSendType" SG_ 1669 AMP_DiagReqData7 7;
BA_ "InvalidValue" SG_ 1669 AMP_DiagReqData7 "null";
BA_ "GenSigSendType" SG_ 1672 ACM_DiagReqData0 7;
BA_ "InvalidValue" SG_ 1672 ACM_DiagReqData0 "null";
BA_ "GenSigSendType" SG_ 1672 ACM_DiagReqData1 7;
BA_ "InvalidValue" SG_ 1672 ACM_DiagReqData1 "null";
BA_ "GenSigSendType" SG_ 1672 ACM_DiagReqData2 7;
BA_ "InvalidValue" SG_ 1672 ACM_DiagReqData2 "null";
BA_ "GenSigSendType" SG_ 1672 ACM_DiagReqData3 7;
BA_ "InvalidValue" SG_ 1672 ACM_DiagReqData3 "null";
BA_ "GenSigSendType" SG_ 1672 ACM_DiagReqData4 7;
BA_ "InvalidValue" SG_ 1672 ACM_DiagReqData4 "null";
BA_ "GenSigSendType" SG_ 1672 ACM_DiagReqData5 7;
BA_ "InvalidValue" SG_ 1672 ACM_DiagReqData5 "null";
BA_ "GenSigSendType" SG_ 1672 ACM_DiagReqData6 7;
BA_ "InvalidValue" SG_ 1672 ACM_DiagReqData6 "null";
BA_ "GenSigSendType" SG_ 1672 ACM_DiagReqData7 7;
BA_ "InvalidValue" SG_ 1672 ACM_DiagReqData7 "null";
BA_ "GenSigSendType" SG_ 1673 CCUF_DiagReqData0 7;
BA_ "InvalidValue" SG_ 1673 CCUF_DiagReqData0 "null";
BA_ "GenSigSendType" SG_ 1673 CCUF_DiagReqData1 7;
BA_ "InvalidValue" SG_ 1673 CCUF_DiagReqData1 "null";
BA_ "GenSigSendType" SG_ 1673 CCUF_DiagReqData2 7;
BA_ "InvalidValue" SG_ 1673 CCUF_DiagReqData2 "null";
BA_ "GenSigSendType" SG_ 1673 CCUF_DiagReqData3 7;
BA_ "InvalidValue" SG_ 1673 CCUF_DiagReqData3 "null";
BA_ "GenSigSendType" SG_ 1673 CCUF_DiagReqData4 7;
BA_ "InvalidValue" SG_ 1673 CCUF_DiagReqData4 "null";
BA_ "GenSigSendType" SG_ 1673 CCUF_DiagReqData5 7;
BA_ "InvalidValue" SG_ 1673 CCUF_DiagReqData5 "null";
BA_ "GenSigSendType" SG_ 1673 CCUF_DiagReqData6 7;
BA_ "InvalidValue" SG_ 1673 CCUF_DiagReqData6 "null";
BA_ "GenSigSendType" SG_ 1673 CCUF_DiagReqData7 7;
BA_ "InvalidValue" SG_ 1673 CCUF_DiagReqData7 "null";
BA_ "GenSigSendType" SG_ 1677 HUD_DiagReqData0 7;
BA_ "InvalidValue" SG_ 1677 HUD_DiagReqData0 "null";
BA_ "GenSigSendType" SG_ 1677 HUD_DiagReqData1 7;
BA_ "InvalidValue" SG_ 1677 HUD_DiagReqData1 "null";
BA_ "GenSigSendType" SG_ 1677 HUD_DiagReqData2 7;
BA_ "InvalidValue" SG_ 1677 HUD_DiagReqData2 "null";
BA_ "GenSigSendType" SG_ 1677 HUD_DiagReqData3 7;
BA_ "InvalidValue" SG_ 1677 HUD_DiagReqData3 "null";
BA_ "GenSigSendType" SG_ 1677 HUD_DiagReqData4 7;
BA_ "InvalidValue" SG_ 1677 HUD_DiagReqData4 "null";
BA_ "GenSigSendType" SG_ 1677 HUD_DiagReqData5 7;
BA_ "InvalidValue" SG_ 1677 HUD_DiagReqData5 "null";
BA_ "GenSigSendType" SG_ 1677 HUD_DiagReqData6 7;
BA_ "InvalidValue" SG_ 1677 HUD_DiagReqData6 "null";
BA_ "GenSigSendType" SG_ 1677 HUD_DiagReqData7 7;
BA_ "InvalidValue" SG_ 1677 HUD_DiagReqData7 "null";
BA_ "GenSigSendType" SG_ 1678 ETG_DiagReqData0 7;
BA_ "InvalidValue" SG_ 1678 ETG_DiagReqData0 "null";
BA_ "GenSigSendType" SG_ 1678 ETG_DiagReqData1 7;
BA_ "InvalidValue" SG_ 1678 ETG_DiagReqData1 "null";
BA_ "GenSigSendType" SG_ 1678 ETG_DiagReqData2 7;
BA_ "InvalidValue" SG_ 1678 ETG_DiagReqData2 "null";
BA_ "GenSigSendType" SG_ 1678 ETG_DiagReqData3 7;
BA_ "InvalidValue" SG_ 1678 ETG_DiagReqData3 "null";
BA_ "GenSigSendType" SG_ 1678 ETG_DiagReqData4 7;
BA_ "InvalidValue" SG_ 1678 ETG_DiagReqData4 "null";
BA_ "GenSigSendType" SG_ 1678 ETG_DiagReqData5 7;
BA_ "InvalidValue" SG_ 1678 ETG_DiagReqData5 "null";
BA_ "GenSigSendType" SG_ 1678 ETG_DiagReqData6 7;
BA_ "InvalidValue" SG_ 1678 ETG_DiagReqData6 "null";
BA_ "GenSigSendType" SG_ 1678 ETG_DiagReqData7 7;
BA_ "InvalidValue" SG_ 1678 ETG_DiagReqData7 "null";
BA_ "GenSigSendType" SG_ 1679 YSS_DiagReqData0 7;
BA_ "InvalidValue" SG_ 1679 YSS_DiagReqData0 "null";
BA_ "GenSigSendType" SG_ 1679 YSS_DiagReqData1 7;
BA_ "InvalidValue" SG_ 1679 YSS_DiagReqData1 "null";
BA_ "GenSigSendType" SG_ 1679 YSS_DiagReqData2 7;
BA_ "InvalidValue" SG_ 1679 YSS_DiagReqData2 "null";
BA_ "GenSigSendType" SG_ 1679 YSS_DiagReqData3 7;
BA_ "InvalidValue" SG_ 1679 YSS_DiagReqData3 "null";
BA_ "GenSigSendType" SG_ 1679 YSS_DiagReqData4 7;
BA_ "InvalidValue" SG_ 1679 YSS_DiagReqData4 "null";
BA_ "GenSigSendType" SG_ 1679 YSS_DiagReqData5 7;
BA_ "InvalidValue" SG_ 1679 YSS_DiagReqData5 "null";
BA_ "GenSigSendType" SG_ 1679 YSS_DiagReqData6 7;
BA_ "InvalidValue" SG_ 1679 YSS_DiagReqData6 "null";
BA_ "GenSigSendType" SG_ 1679 YSS_DiagReqData7 7;
BA_ "InvalidValue" SG_ 1679 YSS_DiagReqData7 "null";
BA_ "GenSigSendType" SG_ 1680 GS_DiagReqData0 7;
BA_ "InvalidValue" SG_ 1680 GS_DiagReqData0 "null";
BA_ "GenSigSendType" SG_ 1680 GS_DiagReqData1 7;
BA_ "InvalidValue" SG_ 1680 GS_DiagReqData1 "null";
BA_ "GenSigSendType" SG_ 1680 GS_DiagReqData2 7;
BA_ "InvalidValue" SG_ 1680 GS_DiagReqData2 "null";
BA_ "GenSigSendType" SG_ 1680 GS_DiagReqData3 7;
BA_ "InvalidValue" SG_ 1680 GS_DiagReqData3 "null";
BA_ "GenSigSendType" SG_ 1680 GS_DiagReqData4 7;
BA_ "InvalidValue" SG_ 1680 GS_DiagReqData4 "null";
BA_ "GenSigSendType" SG_ 1680 GS_DiagReqData5 7;
BA_ "InvalidValue" SG_ 1680 GS_DiagReqData5 "null";
BA_ "GenSigSendType" SG_ 1680 GS_DiagReqData6 7;
BA_ "InvalidValue" SG_ 1680 GS_DiagReqData6 "null";
BA_ "GenSigSendType" SG_ 1680 GS_DiagReqData7 7;
BA_ "InvalidValue" SG_ 1680 GS_DiagReqData7 "null";
BA_ "GenSigSendType" SG_ 1681 ASU_Gateway_DiagReqData0 7;
BA_ "InvalidValue" SG_ 1681 ASU_Gateway_DiagReqData0 "null";
BA_ "GenSigSendType" SG_ 1681 ASU_Gateway_DiagReqData1 7;
BA_ "InvalidValue" SG_ 1681 ASU_Gateway_DiagReqData1 "null";
BA_ "GenSigSendType" SG_ 1681 ASU_Gateway_DiagReqData2 7;
BA_ "InvalidValue" SG_ 1681 ASU_Gateway_DiagReqData2 "null";
BA_ "GenSigSendType" SG_ 1681 ASU_Gateway_DiagReqData3 7;
BA_ "InvalidValue" SG_ 1681 ASU_Gateway_DiagReqData3 "null";
BA_ "GenSigSendType" SG_ 1681 ASU_Gateway_DiagReqData4 7;
BA_ "InvalidValue" SG_ 1681 ASU_Gateway_DiagReqData4 "null";
BA_ "GenSigSendType" SG_ 1681 ASU_Gateway_DiagReqData5 7;
BA_ "InvalidValue" SG_ 1681 ASU_Gateway_DiagReqData5 "null";
BA_ "GenSigSendType" SG_ 1681 ASU_Gateway_DiagReqData6 7;
BA_ "InvalidValue" SG_ 1681 ASU_Gateway_DiagReqData6 "null";
BA_ "GenSigSendType" SG_ 1681 ASU_Gateway_DiagReqData7 7;
BA_ "InvalidValue" SG_ 1681 ASU_Gateway_DiagReqData7 "null";
BA_ "GenSigSendType" SG_ 1683 BMS_DiagReqData0 7;
BA_ "InvalidValue" SG_ 1683 BMS_DiagReqData0 "null";
BA_ "GenSigSendType" SG_ 1683 BMS_DiagReqData1 7;
BA_ "InvalidValue" SG_ 1683 BMS_DiagReqData1 "null";
BA_ "GenSigSendType" SG_ 1683 BMS_DiagReqData2 7;
BA_ "InvalidValue" SG_ 1683 BMS_DiagReqData2 "null";
BA_ "GenSigSendType" SG_ 1683 BMS_DiagReqData3 7;
BA_ "InvalidValue" SG_ 1683 BMS_DiagReqData3 "null";
BA_ "GenSigSendType" SG_ 1683 BMS_DiagReqData4 7;
BA_ "InvalidValue" SG_ 1683 BMS_DiagReqData4 "null";
BA_ "GenSigSendType" SG_ 1683 BMS_DiagReqData5 7;
BA_ "InvalidValue" SG_ 1683 BMS_DiagReqData5 "null";
BA_ "GenSigSendType" SG_ 1683 BMS_DiagReqData6 7;
BA_ "InvalidValue" SG_ 1683 BMS_DiagReqData6 "null";
BA_ "GenSigSendType" SG_ 1683 BMS_DiagReqData7 7;
BA_ "InvalidValue" SG_ 1683 BMS_DiagReqData7 "null";
BA_ "GenSigSendType" SG_ 1684 CCUR_DiagReqData0 7;
BA_ "InvalidValue" SG_ 1684 CCUR_DiagReqData0 "null";
BA_ "GenSigSendType" SG_ 1684 CCUR_DiagReqData1 7;
BA_ "InvalidValue" SG_ 1684 CCUR_DiagReqData1 "null";
BA_ "GenSigSendType" SG_ 1684 CCUR_DiagReqData2 7;
BA_ "InvalidValue" SG_ 1684 CCUR_DiagReqData2 "null";
BA_ "GenSigSendType" SG_ 1684 CCUR_DiagReqData3 7;
BA_ "InvalidValue" SG_ 1684 CCUR_DiagReqData3 "null";
BA_ "GenSigSendType" SG_ 1684 CCUR_DiagReqData4 7;
BA_ "InvalidValue" SG_ 1684 CCUR_DiagReqData4 "null";
BA_ "GenSigSendType" SG_ 1684 CCUR_DiagReqData5 7;
BA_ "InvalidValue" SG_ 1684 CCUR_DiagReqData5 "null";
BA_ "GenSigSendType" SG_ 1684 CCUR_DiagReqData6 7;
BA_ "InvalidValue" SG_ 1684 CCUR_DiagReqData6 "null";
BA_ "GenSigSendType" SG_ 1684 CCUR_DiagReqData7 7;
BA_ "InvalidValue" SG_ 1684 CCUR_DiagReqData7 "null";
BA_ "GenSigSendType" SG_ 1690 EDS_R_DiagReqData0 7;
BA_ "InvalidValue" SG_ 1690 EDS_R_DiagReqData0 "null";
BA_ "GenSigSendType" SG_ 1690 EDS_R_DiagReqData1 7;
BA_ "InvalidValue" SG_ 1690 EDS_R_DiagReqData1 "null";
BA_ "GenSigSendType" SG_ 1690 EDS_R_DiagReqData2 7;
BA_ "InvalidValue" SG_ 1690 EDS_R_DiagReqData2 "null";
BA_ "GenSigSendType" SG_ 1690 EDS_R_DiagReqData3 7;
BA_ "InvalidValue" SG_ 1690 EDS_R_DiagReqData3 "null";
BA_ "GenSigSendType" SG_ 1690 EDS_R_DiagReqData4 7;
BA_ "InvalidValue" SG_ 1690 EDS_R_DiagReqData4 "null";
BA_ "GenSigSendType" SG_ 1690 EDS_R_DiagReqData5 7;
BA_ "InvalidValue" SG_ 1690 EDS_R_DiagReqData5 "null";
BA_ "GenSigSendType" SG_ 1690 EDS_R_DiagReqData6 7;
BA_ "InvalidValue" SG_ 1690 EDS_R_DiagReqData6 "null";
BA_ "GenSigSendType" SG_ 1690 EDS_R_DiagReqData7 7;
BA_ "InvalidValue" SG_ 1690 EDS_R_DiagReqData7 "null";
BA_ "GenSigSendType" SG_ 1691 EDS_F_DiagReqData0 7;
BA_ "InvalidValue" SG_ 1691 EDS_F_DiagReqData0 "null";
BA_ "GenSigSendType" SG_ 1691 EDS_F_DiagReqData1 7;
BA_ "InvalidValue" SG_ 1691 EDS_F_DiagReqData1 "null";
BA_ "GenSigSendType" SG_ 1691 EDS_F_DiagReqData2 7;
BA_ "InvalidValue" SG_ 1691 EDS_F_DiagReqData2 "null";
BA_ "GenSigSendType" SG_ 1691 EDS_F_DiagReqData3 7;
BA_ "InvalidValue" SG_ 1691 EDS_F_DiagReqData3 "null";
BA_ "GenSigSendType" SG_ 1691 EDS_F_DiagReqData4 7;
BA_ "InvalidValue" SG_ 1691 EDS_F_DiagReqData4 "null";
BA_ "GenSigSendType" SG_ 1691 EDS_F_DiagReqData5 7;
BA_ "InvalidValue" SG_ 1691 EDS_F_DiagReqData5 "null";
BA_ "GenSigSendType" SG_ 1691 EDS_F_DiagReqData6 7;
BA_ "InvalidValue" SG_ 1691 EDS_F_DiagReqData6 "null";
BA_ "GenSigSendType" SG_ 1691 EDS_F_DiagReqData7 7;
BA_ "InvalidValue" SG_ 1691 EDS_F_DiagReqData7 "null";
BA_ "GenSigSendType" SG_ 1694 PSM_D_DiagReqData0 7;
BA_ "InvalidValue" SG_ 1694 PSM_D_DiagReqData0 "null";
BA_ "GenSigSendType" SG_ 1694 PSM_D_DiagReqData1 7;
BA_ "InvalidValue" SG_ 1694 PSM_D_DiagReqData1 "null";
BA_ "GenSigSendType" SG_ 1694 PSM_D_DiagReqData2 7;
BA_ "InvalidValue" SG_ 1694 PSM_D_DiagReqData2 "null";
BA_ "GenSigSendType" SG_ 1694 PSM_D_DiagReqData3 7;
BA_ "InvalidValue" SG_ 1694 PSM_D_DiagReqData3 "null";
BA_ "GenSigSendType" SG_ 1694 PSM_D_DiagReqData4 7;
BA_ "InvalidValue" SG_ 1694 PSM_D_DiagReqData4 "null";
BA_ "GenSigSendType" SG_ 1694 PSM_D_DiagReqData5 7;
BA_ "InvalidValue" SG_ 1694 PSM_D_DiagReqData5 "null";
BA_ "GenSigSendType" SG_ 1694 PSM_D_DiagReqData6 7;
BA_ "InvalidValue" SG_ 1694 PSM_D_DiagReqData6 "null";
BA_ "GenSigSendType" SG_ 1694 PSM_D_DiagReqData7 7;
BA_ "InvalidValue" SG_ 1694 PSM_D_DiagReqData7 "null";
BA_ "GenSigSendType" SG_ 1701 MRGEN_DiagReqData0 7;
BA_ "InvalidValue" SG_ 1701 MRGEN_DiagReqData0 "null";
BA_ "GenSigSendType" SG_ 1701 MRGEN_DiagReqData1 7;
BA_ "InvalidValue" SG_ 1701 MRGEN_DiagReqData1 "null";
BA_ "GenSigSendType" SG_ 1701 MRGEN_DiagReqData2 7;
BA_ "InvalidValue" SG_ 1701 MRGEN_DiagReqData2 "null";
BA_ "GenSigSendType" SG_ 1701 MRGEN_DiagReqData3 7;
BA_ "InvalidValue" SG_ 1701 MRGEN_DiagReqData3 "null";
BA_ "GenSigSendType" SG_ 1701 MRGEN_DiagReqData4 7;
BA_ "InvalidValue" SG_ 1701 MRGEN_DiagReqData4 "null";
BA_ "GenSigSendType" SG_ 1701 MRGEN_DiagReqData5 7;
BA_ "InvalidValue" SG_ 1701 MRGEN_DiagReqData5 "null";
BA_ "GenSigSendType" SG_ 1701 MRGEN_DiagReqData6 7;
BA_ "InvalidValue" SG_ 1701 MRGEN_DiagReqData6 "null";
BA_ "GenSigSendType" SG_ 1701 MRGEN_DiagReqData7 7;
BA_ "InvalidValue" SG_ 1701 MRGEN_DiagReqData7 "null";
BA_ "GenSigSendType" SG_ 1702 SCAM_DiagReqData0 7;
BA_ "InvalidValue" SG_ 1702 SCAM_DiagReqData0 "null";
BA_ "GenSigSendType" SG_ 1702 SCAM_DiagReqData1 7;
BA_ "InvalidValue" SG_ 1702 SCAM_DiagReqData1 "null";
BA_ "GenSigSendType" SG_ 1702 SCAM_DiagReqData2 7;
BA_ "InvalidValue" SG_ 1702 SCAM_DiagReqData2 "null";
BA_ "GenSigSendType" SG_ 1702 SCAM_DiagReqData3 7;
BA_ "InvalidValue" SG_ 1702 SCAM_DiagReqData3 "null";
BA_ "GenSigSendType" SG_ 1702 SCAM_DiagReqData4 7;
BA_ "InvalidValue" SG_ 1702 SCAM_DiagReqData4 "null";
BA_ "GenSigSendType" SG_ 1702 SCAM_DiagReqData5 7;
BA_ "InvalidValue" SG_ 1702 SCAM_DiagReqData5 "null";
BA_ "GenSigSendType" SG_ 1702 SCAM_DiagReqData6 7;
BA_ "InvalidValue" SG_ 1702 SCAM_DiagReqData6 "null";
BA_ "GenSigSendType" SG_ 1702 SCAM_DiagReqData7 7;
BA_ "InvalidValue" SG_ 1702 SCAM_DiagReqData7 "null";
BA_ "GenSigSendType" SG_ 1703 RCU_DiagReqData0 7;
BA_ "InvalidValue" SG_ 1703 RCU_DiagReqData0 "null";
BA_ "GenSigSendType" SG_ 1703 RCU_DiagReqData1 7;
BA_ "InvalidValue" SG_ 1703 RCU_DiagReqData1 "null";
BA_ "GenSigSendType" SG_ 1703 RCU_DiagReqData2 7;
BA_ "InvalidValue" SG_ 1703 RCU_DiagReqData2 "null";
BA_ "GenSigSendType" SG_ 1703 RCU_DiagReqData3 7;
BA_ "InvalidValue" SG_ 1703 RCU_DiagReqData3 "null";
BA_ "GenSigSendType" SG_ 1703 RCU_DiagReqData4 7;
BA_ "InvalidValue" SG_ 1703 RCU_DiagReqData4 "null";
BA_ "GenSigSendType" SG_ 1703 RCU_DiagReqData5 7;
BA_ "InvalidValue" SG_ 1703 RCU_DiagReqData5 "null";
BA_ "GenSigSendType" SG_ 1703 RCU_DiagReqData6 7;
BA_ "InvalidValue" SG_ 1703 RCU_DiagReqData6 "null";
BA_ "GenSigSendType" SG_ 1703 RCU_DiagReqData7 7;
BA_ "InvalidValue" SG_ 1703 RCU_DiagReqData7 "null";
BA_ "GenSigSendType" SG_ 1704 EPS_DiagReqData0 7;
BA_ "InvalidValue" SG_ 1704 EPS_DiagReqData0 "null";
BA_ "GenSigSendType" SG_ 1704 EPS_DiagReqData1 7;
BA_ "InvalidValue" SG_ 1704 EPS_DiagReqData1 "null";
BA_ "GenSigSendType" SG_ 1704 EPS_DiagReqData2 7;
BA_ "InvalidValue" SG_ 1704 EPS_DiagReqData2 "null";
BA_ "GenSigSendType" SG_ 1704 EPS_DiagReqData3 7;
BA_ "InvalidValue" SG_ 1704 EPS_DiagReqData3 "null";
BA_ "GenSigSendType" SG_ 1704 EPS_DiagReqData4 7;
BA_ "InvalidValue" SG_ 1704 EPS_DiagReqData4 "null";
BA_ "GenSigSendType" SG_ 1704 EPS_DiagReqData5 7;
BA_ "InvalidValue" SG_ 1704 EPS_DiagReqData5 "null";
BA_ "GenSigSendType" SG_ 1704 EPS_DiagReqData6 7;
BA_ "InvalidValue" SG_ 1704 EPS_DiagReqData6 "null";
BA_ "GenSigSendType" SG_ 1704 EPS_DiagReqData7 7;
BA_ "InvalidValue" SG_ 1704 EPS_DiagReqData7 "null";
BA_ "GenSigSendType" SG_ 1705 IDB_DiagReqData0 7;
BA_ "InvalidValue" SG_ 1705 IDB_DiagReqData0 "null";
BA_ "GenSigSendType" SG_ 1705 IDB_DiagReqData1 7;
BA_ "InvalidValue" SG_ 1705 IDB_DiagReqData1 "null";
BA_ "GenSigSendType" SG_ 1705 IDB_DiagReqData2 7;
BA_ "InvalidValue" SG_ 1705 IDB_DiagReqData2 "null";
BA_ "GenSigSendType" SG_ 1705 IDB_DiagReqData3 7;
BA_ "InvalidValue" SG_ 1705 IDB_DiagReqData3 "null";
BA_ "GenSigSendType" SG_ 1705 IDB_DiagReqData4 7;
BA_ "InvalidValue" SG_ 1705 IDB_DiagReqData4 "null";
BA_ "GenSigSendType" SG_ 1705 IDB_DiagReqData5 7;
BA_ "InvalidValue" SG_ 1705 IDB_DiagReqData5 "null";
BA_ "GenSigSendType" SG_ 1705 IDB_DiagReqData6 7;
BA_ "InvalidValue" SG_ 1705 IDB_DiagReqData6 "null";
BA_ "GenSigSendType" SG_ 1705 IDB_DiagReqData7 7;
BA_ "InvalidValue" SG_ 1705 IDB_DiagReqData7 "null";
BA_ "GenSigSendType" SG_ 1706 AVAS_DiagReqData0 7;
BA_ "InvalidValue" SG_ 1706 AVAS_DiagReqData0 "null";
BA_ "GenSigSendType" SG_ 1706 AVAS_DiagReqData1 7;
BA_ "InvalidValue" SG_ 1706 AVAS_DiagReqData1 "null";
BA_ "GenSigSendType" SG_ 1706 AVAS_DiagReqData2 7;
BA_ "InvalidValue" SG_ 1706 AVAS_DiagReqData2 "null";
BA_ "GenSigSendType" SG_ 1706 AVAS_DiagReqData3 7;
BA_ "InvalidValue" SG_ 1706 AVAS_DiagReqData3 "null";
BA_ "GenSigSendType" SG_ 1706 AVAS_DiagReqData4 7;
BA_ "InvalidValue" SG_ 1706 AVAS_DiagReqData4 "null";
BA_ "GenSigSendType" SG_ 1706 AVAS_DiagReqData5 7;
BA_ "InvalidValue" SG_ 1706 AVAS_DiagReqData5 "null";
BA_ "GenSigSendType" SG_ 1706 AVAS_DiagReqData6 7;
BA_ "InvalidValue" SG_ 1706 AVAS_DiagReqData6 "null";
BA_ "GenSigSendType" SG_ 1706 AVAS_DiagReqData7 7;
BA_ "InvalidValue" SG_ 1706 AVAS_DiagReqData7 "null";
BA_ "GenSigSendType" SG_ 1707 EPS2_DiagReqData0 7;
BA_ "InvalidValue" SG_ 1707 EPS2_DiagReqData0 "null";
BA_ "GenSigSendType" SG_ 1707 EPS2_DiagReqData1 7;
BA_ "InvalidValue" SG_ 1707 EPS2_DiagReqData1 "null";
BA_ "GenSigSendType" SG_ 1707 EPS2_DiagReqData2 7;
BA_ "InvalidValue" SG_ 1707 EPS2_DiagReqData2 "null";
BA_ "GenSigSendType" SG_ 1707 EPS2_DiagReqData3 7;
BA_ "InvalidValue" SG_ 1707 EPS2_DiagReqData3 "null";
BA_ "GenSigSendType" SG_ 1707 EPS2_DiagReqData4 7;
BA_ "InvalidValue" SG_ 1707 EPS2_DiagReqData4 "null";
BA_ "GenSigSendType" SG_ 1707 EPS2_DiagReqData5 7;
BA_ "InvalidValue" SG_ 1707 EPS2_DiagReqData5 "null";
BA_ "GenSigSendType" SG_ 1707 EPS2_DiagReqData6 7;
BA_ "InvalidValue" SG_ 1707 EPS2_DiagReqData6 "null";
BA_ "GenSigSendType" SG_ 1707 EPS2_DiagReqData7 7;
BA_ "InvalidValue" SG_ 1707 EPS2_DiagReqData7 "null";
BA_ "GenSigSendType" SG_ 1708 VCU_DiagReqData0 7;
BA_ "InvalidValue" SG_ 1708 VCU_DiagReqData0 "null";
BA_ "GenSigSendType" SG_ 1708 VCU_DiagReqData1 7;
BA_ "InvalidValue" SG_ 1708 VCU_DiagReqData1 "null";
BA_ "GenSigSendType" SG_ 1708 VCU_DiagReqData2 7;
BA_ "InvalidValue" SG_ 1708 VCU_DiagReqData2 "null";
BA_ "GenSigSendType" SG_ 1708 VCU_DiagReqData3 7;
BA_ "InvalidValue" SG_ 1708 VCU_DiagReqData3 "null";
BA_ "GenSigSendType" SG_ 1708 VCU_DiagReqData4 7;
BA_ "InvalidValue" SG_ 1708 VCU_DiagReqData4 "null";
BA_ "GenSigSendType" SG_ 1708 VCU_DiagReqData5 7;
BA_ "InvalidValue" SG_ 1708 VCU_DiagReqData5 "null";
BA_ "GenSigSendType" SG_ 1708 VCU_DiagReqData6 7;
BA_ "InvalidValue" SG_ 1708 VCU_DiagReqData6 "null";
BA_ "GenSigSendType" SG_ 1708 VCU_DiagReqData7 7;
BA_ "InvalidValue" SG_ 1708 VCU_DiagReqData7 "null";
BA_ "GenSigSendType" SG_ 1709 CPD_2_DiagReqData0 7;
BA_ "GenSigSendType" SG_ 1709 CPD_2_DiagReqData1 7;
BA_ "GenSigSendType" SG_ 1709 CPD_2_DiagReqData2 7;
BA_ "GenSigSendType" SG_ 1709 CPD_2_DiagReqData3 7;
BA_ "GenSigSendType" SG_ 1709 CPD_2_DiagReqData4 7;
BA_ "GenSigSendType" SG_ 1709 CPD_2_DiagReqData5 7;
BA_ "GenSigSendType" SG_ 1709 CPD_2_DiagReqData6 7;
BA_ "GenSigSendType" SG_ 1709 CPD_2_DiagReqData7 7;
BA_ "GenSigSendType" SG_ 1710 EASC_DiagReqData0 7;
BA_ "InvalidValue" SG_ 1710 EASC_DiagReqData0 "null";
BA_ "GenSigSendType" SG_ 1710 EASC_DiagReqData1 7;
BA_ "InvalidValue" SG_ 1710 EASC_DiagReqData1 "null";
BA_ "GenSigSendType" SG_ 1710 EASC_DiagReqData2 7;
BA_ "InvalidValue" SG_ 1710 EASC_DiagReqData2 "null";
BA_ "GenSigSendType" SG_ 1710 EASC_DiagReqData3 7;
BA_ "InvalidValue" SG_ 1710 EASC_DiagReqData3 "null";
BA_ "GenSigSendType" SG_ 1710 EASC_DiagReqData4 7;
BA_ "InvalidValue" SG_ 1710 EASC_DiagReqData4 "null";
BA_ "GenSigSendType" SG_ 1710 EASC_DiagReqData5 7;
BA_ "InvalidValue" SG_ 1710 EASC_DiagReqData5 "null";
BA_ "GenSigSendType" SG_ 1710 EASC_DiagReqData6 7;
BA_ "InvalidValue" SG_ 1710 EASC_DiagReqData6 "null";
BA_ "GenSigSendType" SG_ 1710 EASC_DiagReqData7 7;
BA_ "InvalidValue" SG_ 1710 EASC_DiagReqData7 "null";
BA_ "GenSigSendType" SG_ 1711 CPD_DiagReqData0 7;
BA_ "InvalidValue" SG_ 1711 CPD_DiagReqData0 "null";
BA_ "GenSigSendType" SG_ 1711 CPD_DiagReqData1 7;
BA_ "InvalidValue" SG_ 1711 CPD_DiagReqData1 "null";
BA_ "GenSigSendType" SG_ 1711 CPD_DiagReqData2 7;
BA_ "InvalidValue" SG_ 1711 CPD_DiagReqData2 "null";
BA_ "GenSigSendType" SG_ 1711 CPD_DiagReqData3 7;
BA_ "InvalidValue" SG_ 1711 CPD_DiagReqData3 "null";
BA_ "GenSigSendType" SG_ 1711 CPD_DiagReqData4 7;
BA_ "InvalidValue" SG_ 1711 CPD_DiagReqData4 "null";
BA_ "GenSigSendType" SG_ 1711 CPD_DiagReqData5 7;
BA_ "InvalidValue" SG_ 1711 CPD_DiagReqData5 "null";
BA_ "GenSigSendType" SG_ 1711 CPD_DiagReqData6 7;
BA_ "InvalidValue" SG_ 1711 CPD_DiagReqData6 "null";
BA_ "GenSigSendType" SG_ 1711 CPD_DiagReqData7 7;
BA_ "InvalidValue" SG_ 1711 CPD_DiagReqData7 "null";
BA_ "GenSigSendType" SG_ 1716 SRR_FR_DiagReqData0 7;
BA_ "InvalidValue" SG_ 1716 SRR_FR_DiagReqData0 "null";
BA_ "GenSigSendType" SG_ 1716 SRR_FR_DiagReqData1 7;
BA_ "InvalidValue" SG_ 1716 SRR_FR_DiagReqData1 "null";
BA_ "GenSigSendType" SG_ 1716 SRR_FR_DiagReqData2 7;
BA_ "InvalidValue" SG_ 1716 SRR_FR_DiagReqData2 "null";
BA_ "GenSigSendType" SG_ 1716 SRR_FR_DiagReqData3 7;
BA_ "InvalidValue" SG_ 1716 SRR_FR_DiagReqData3 "null";
BA_ "GenSigSendType" SG_ 1716 SRR_FR_DiagReqData4 7;
BA_ "InvalidValue" SG_ 1716 SRR_FR_DiagReqData4 "null";
BA_ "GenSigSendType" SG_ 1716 SRR_FR_DiagReqData5 7;
BA_ "InvalidValue" SG_ 1716 SRR_FR_DiagReqData5 "null";
BA_ "GenSigSendType" SG_ 1716 SRR_FR_DiagReqData6 7;
BA_ "InvalidValue" SG_ 1716 SRR_FR_DiagReqData6 "null";
BA_ "GenSigSendType" SG_ 1716 SRR_FR_DiagReqData7 7;
BA_ "InvalidValue" SG_ 1716 SRR_FR_DiagReqData7 "null";
BA_ "GenSigSendType" SG_ 1717 SRR_FL_DiagReqData0 7;
BA_ "InvalidValue" SG_ 1717 SRR_FL_DiagReqData0 "null";
BA_ "GenSigSendType" SG_ 1717 SRR_FL_DiagReqData1 7;
BA_ "InvalidValue" SG_ 1717 SRR_FL_DiagReqData1 "null";
BA_ "GenSigSendType" SG_ 1717 SRR_FL_DiagReqData2 7;
BA_ "InvalidValue" SG_ 1717 SRR_FL_DiagReqData2 "null";
BA_ "GenSigSendType" SG_ 1717 SRR_FL_DiagReqData3 7;
BA_ "InvalidValue" SG_ 1717 SRR_FL_DiagReqData3 "null";
BA_ "GenSigSendType" SG_ 1717 SRR_FL_DiagReqData4 7;
BA_ "InvalidValue" SG_ 1717 SRR_FL_DiagReqData4 "null";
BA_ "GenSigSendType" SG_ 1717 SRR_FL_DiagReqData5 7;
BA_ "InvalidValue" SG_ 1717 SRR_FL_DiagReqData5 "null";
BA_ "GenSigSendType" SG_ 1717 SRR_FL_DiagReqData6 7;
BA_ "InvalidValue" SG_ 1717 SRR_FL_DiagReqData6 "null";
BA_ "GenSigSendType" SG_ 1717 SRR_FL_DiagReqData7 7;
BA_ "InvalidValue" SG_ 1717 SRR_FL_DiagReqData7 "null";
BA_ "GenSigSendType" SG_ 1718 SRR_RR_DiagReqData0 7;
BA_ "InvalidValue" SG_ 1718 SRR_RR_DiagReqData0 "null";
BA_ "GenSigSendType" SG_ 1718 SRR_RR_DiagReqData1 7;
BA_ "InvalidValue" SG_ 1718 SRR_RR_DiagReqData1 "null";
BA_ "GenSigSendType" SG_ 1718 SRR_RR_DiagReqData2 7;
BA_ "InvalidValue" SG_ 1718 SRR_RR_DiagReqData2 "null";
BA_ "GenSigSendType" SG_ 1718 SRR_RR_DiagReqData3 7;
BA_ "InvalidValue" SG_ 1718 SRR_RR_DiagReqData3 "null";
BA_ "GenSigSendType" SG_ 1718 SRR_RR_DiagReqData4 7;
BA_ "InvalidValue" SG_ 1718 SRR_RR_DiagReqData4 "null";
BA_ "GenSigSendType" SG_ 1718 SRR_RR_DiagReqData5 7;
BA_ "InvalidValue" SG_ 1718 SRR_RR_DiagReqData5 "null";
BA_ "GenSigSendType" SG_ 1718 SRR_RR_DiagReqData6 7;
BA_ "InvalidValue" SG_ 1718 SRR_RR_DiagReqData6 "null";
BA_ "GenSigSendType" SG_ 1718 SRR_RR_DiagReqData7 7;
BA_ "InvalidValue" SG_ 1718 SRR_RR_DiagReqData7 "null";
BA_ "GenSigSendType" SG_ 1719 SRR_RL_DiagReqData0 7;
BA_ "InvalidValue" SG_ 1719 SRR_RL_DiagReqData0 "null";
BA_ "GenSigSendType" SG_ 1719 SRR_RL_DiagReqData1 7;
BA_ "InvalidValue" SG_ 1719 SRR_RL_DiagReqData1 "null";
BA_ "GenSigSendType" SG_ 1719 SRR_RL_DiagReqData2 7;
BA_ "InvalidValue" SG_ 1719 SRR_RL_DiagReqData2 "null";
BA_ "GenSigSendType" SG_ 1719 SRR_RL_DiagReqData3 7;
BA_ "InvalidValue" SG_ 1719 SRR_RL_DiagReqData3 "null";
BA_ "GenSigSendType" SG_ 1719 SRR_RL_DiagReqData4 7;
BA_ "InvalidValue" SG_ 1719 SRR_RL_DiagReqData4 "null";
BA_ "GenSigSendType" SG_ 1719 SRR_RL_DiagReqData5 7;
BA_ "InvalidValue" SG_ 1719 SRR_RL_DiagReqData5 "null";
BA_ "GenSigSendType" SG_ 1719 SRR_RL_DiagReqData6 7;
BA_ "InvalidValue" SG_ 1719 SRR_RL_DiagReqData6 "null";
BA_ "GenSigSendType" SG_ 1719 SRR_RL_DiagReqData7 7;
BA_ "InvalidValue" SG_ 1719 SRR_RL_DiagReqData7 "null";
BA_ "GenSigSendType" SG_ 1723 TRM_DiagReqData0 7;
BA_ "InvalidValue" SG_ 1723 TRM_DiagReqData0 "null";
BA_ "GenSigSendType" SG_ 1723 TRM_DiagReqData1 7;
BA_ "InvalidValue" SG_ 1723 TRM_DiagReqData1 "null";
BA_ "GenSigSendType" SG_ 1723 TRM_DiagReqData2 7;
BA_ "InvalidValue" SG_ 1723 TRM_DiagReqData2 "null";
BA_ "GenSigSendType" SG_ 1723 TRM_DiagReqData3 7;
BA_ "InvalidValue" SG_ 1723 TRM_DiagReqData3 "null";
BA_ "GenSigSendType" SG_ 1723 TRM_DiagReqData4 7;
BA_ "InvalidValue" SG_ 1723 TRM_DiagReqData4 "null";
BA_ "GenSigSendType" SG_ 1723 TRM_DiagReqData5 7;
BA_ "InvalidValue" SG_ 1723 TRM_DiagReqData5 "null";
BA_ "GenSigSendType" SG_ 1723 TRM_DiagReqData6 7;
BA_ "InvalidValue" SG_ 1723 TRM_DiagReqData6 "null";
BA_ "GenSigSendType" SG_ 1723 TRM_DiagReqData7 7;
BA_ "InvalidValue" SG_ 1723 TRM_DiagReqData7 "null";
BA_ "GenSigSendType" SG_ 1725 POD_DCDC_DiagReqData0 7;
BA_ "InvalidValue" SG_ 1725 POD_DCDC_DiagReqData0 "null";
BA_ "GenSigSendType" SG_ 1725 POD_DCDC_DiagReqData1 7;
BA_ "InvalidValue" SG_ 1725 POD_DCDC_DiagReqData1 "null";
BA_ "GenSigSendType" SG_ 1725 POD_DCDC_DiagReqData2 7;
BA_ "InvalidValue" SG_ 1725 POD_DCDC_DiagReqData2 "null";
BA_ "GenSigSendType" SG_ 1725 POD_DCDC_DiagReqData3 7;
BA_ "InvalidValue" SG_ 1725 POD_DCDC_DiagReqData3 "null";
BA_ "GenSigSendType" SG_ 1725 POD_DCDC_DiagReqData4 7;
BA_ "InvalidValue" SG_ 1725 POD_DCDC_DiagReqData4 "null";
BA_ "GenSigSendType" SG_ 1725 POD_DCDC_DiagReqData5 7;
BA_ "InvalidValue" SG_ 1725 POD_DCDC_DiagReqData5 "null";
BA_ "GenSigSendType" SG_ 1725 POD_DCDC_DiagReqData6 7;
BA_ "InvalidValue" SG_ 1725 POD_DCDC_DiagReqData6 "null";
BA_ "GenSigSendType" SG_ 1725 POD_DCDC_DiagReqData7 7;
BA_ "InvalidValue" SG_ 1725 POD_DCDC_DiagReqData7 "null";
BA_ "GenSigSendType" SG_ 1726 POD_OBC_DiagReqData0 7;
BA_ "InvalidValue" SG_ 1726 POD_OBC_DiagReqData0 "null";
BA_ "GenSigSendType" SG_ 1726 POD_OBC_DiagReqData1 7;
BA_ "InvalidValue" SG_ 1726 POD_OBC_DiagReqData1 "null";
BA_ "GenSigSendType" SG_ 1726 POD_OBC_DiagReqData2 7;
BA_ "InvalidValue" SG_ 1726 POD_OBC_DiagReqData2 "null";
BA_ "GenSigSendType" SG_ 1726 POD_OBC_DiagReqData3 7;
BA_ "InvalidValue" SG_ 1726 POD_OBC_DiagReqData3 "null";
BA_ "GenSigSendType" SG_ 1726 POD_OBC_DiagReqData4 7;
BA_ "InvalidValue" SG_ 1726 POD_OBC_DiagReqData4 "null";
BA_ "GenSigSendType" SG_ 1726 POD_OBC_DiagReqData5 7;
BA_ "InvalidValue" SG_ 1726 POD_OBC_DiagReqData5 "null";
BA_ "GenSigSendType" SG_ 1726 POD_OBC_DiagReqData6 7;
BA_ "InvalidValue" SG_ 1726 POD_OBC_DiagReqData6 "null";
BA_ "GenSigSendType" SG_ 1726 POD_OBC_DiagReqData7 7;
BA_ "InvalidValue" SG_ 1726 POD_OBC_DiagReqData7 "null";
BA_ "GenSigSendType" SG_ 1727 POD_DiagReqData0 7;
BA_ "InvalidValue" SG_ 1727 POD_DiagReqData0 "null";
BA_ "GenSigSendType" SG_ 1727 POD_DiagReqData1 7;
BA_ "InvalidValue" SG_ 1727 POD_DiagReqData1 "null";
BA_ "GenSigSendType" SG_ 1727 POD_DiagReqData2 7;
BA_ "InvalidValue" SG_ 1727 POD_DiagReqData2 "null";
BA_ "GenSigSendType" SG_ 1727 POD_DiagReqData3 7;
BA_ "InvalidValue" SG_ 1727 POD_DiagReqData3 "null";
BA_ "GenSigSendType" SG_ 1727 POD_DiagReqData4 7;
BA_ "InvalidValue" SG_ 1727 POD_DiagReqData4 "null";
BA_ "GenSigSendType" SG_ 1727 POD_DiagReqData5 7;
BA_ "InvalidValue" SG_ 1727 POD_DiagReqData5 "null";
BA_ "GenSigSendType" SG_ 1727 POD_DiagReqData6 7;
BA_ "InvalidValue" SG_ 1727 POD_DiagReqData6 "null";
BA_ "GenSigSendType" SG_ 1727 POD_DiagReqData7 7;
BA_ "InvalidValue" SG_ 1727 POD_DiagReqData7 "null";
BA_ "GenSigSendType" SG_ 1728 ADAS_DiagReqData0 7;
BA_ "InvalidValue" SG_ 1728 ADAS_DiagReqData0 "null";
BA_ "GenSigSendType" SG_ 1728 ADAS_DiagReqData1 7;
BA_ "InvalidValue" SG_ 1728 ADAS_DiagReqData1 "null";
BA_ "GenSigSendType" SG_ 1728 ADAS_DiagReqData2 7;
BA_ "InvalidValue" SG_ 1728 ADAS_DiagReqData2 "null";
BA_ "GenSigSendType" SG_ 1728 ADAS_DiagReqData3 7;
BA_ "InvalidValue" SG_ 1728 ADAS_DiagReqData3 "null";
BA_ "GenSigSendType" SG_ 1728 ADAS_DiagReqData4 7;
BA_ "InvalidValue" SG_ 1728 ADAS_DiagReqData4 "null";
BA_ "GenSigSendType" SG_ 1728 ADAS_DiagReqData5 7;
BA_ "InvalidValue" SG_ 1728 ADAS_DiagReqData5 "null";
BA_ "GenSigSendType" SG_ 1728 ADAS_DiagReqData6 7;
BA_ "InvalidValue" SG_ 1728 ADAS_DiagReqData6 "null";
BA_ "GenSigSendType" SG_ 1728 ADAS_DiagReqData7 7;
BA_ "InvalidValue" SG_ 1728 ADAS_DiagReqData7 "null";
BA_ "GenSigSendType" SG_ 1729 APM_DiagReqData0 7;
BA_ "InvalidValue" SG_ 1729 APM_DiagReqData0 "null";
BA_ "GenSigSendType" SG_ 1729 APM_DiagReqData1 7;
BA_ "InvalidValue" SG_ 1729 APM_DiagReqData1 "null";
BA_ "GenSigSendType" SG_ 1729 APM_DiagReqData2 7;
BA_ "InvalidValue" SG_ 1729 APM_DiagReqData2 "null";
BA_ "GenSigSendType" SG_ 1729 APM_DiagReqData3 7;
BA_ "InvalidValue" SG_ 1729 APM_DiagReqData3 "null";
BA_ "GenSigSendType" SG_ 1729 APM_DiagReqData4 7;
BA_ "InvalidValue" SG_ 1729 APM_DiagReqData4 "null";
BA_ "GenSigSendType" SG_ 1729 APM_DiagReqData5 7;
BA_ "InvalidValue" SG_ 1729 APM_DiagReqData5 "null";
BA_ "GenSigSendType" SG_ 1729 APM_DiagReqData6 7;
BA_ "InvalidValue" SG_ 1729 APM_DiagReqData6 "null";
BA_ "GenSigSendType" SG_ 1729 APM_DiagReqData7 7;
BA_ "InvalidValue" SG_ 1729 APM_DiagReqData7 "null";
BA_ "GenSigSendType" SG_ 1730 SHVU_F_DiagReqData0 7;
BA_ "InvalidValue" SG_ 1730 SHVU_F_DiagReqData0 "null";
BA_ "GenSigSendType" SG_ 1730 SHVU_F_DiagReqData1 7;
BA_ "InvalidValue" SG_ 1730 SHVU_F_DiagReqData1 "null";
BA_ "GenSigSendType" SG_ 1730 SHVU_F_DiagReqData2 7;
BA_ "InvalidValue" SG_ 1730 SHVU_F_DiagReqData2 "null";
BA_ "GenSigSendType" SG_ 1730 SHVU_F_DiagReqData3 7;
BA_ "InvalidValue" SG_ 1730 SHVU_F_DiagReqData3 "null";
BA_ "GenSigSendType" SG_ 1730 SHVU_F_DiagReqData4 7;
BA_ "InvalidValue" SG_ 1730 SHVU_F_DiagReqData4 "null";
BA_ "GenSigSendType" SG_ 1730 SHVU_F_DiagReqData5 7;
BA_ "InvalidValue" SG_ 1730 SHVU_F_DiagReqData5 "null";
BA_ "GenSigSendType" SG_ 1730 SHVU_F_DiagReqData6 7;
BA_ "InvalidValue" SG_ 1730 SHVU_F_DiagReqData6 "null";
BA_ "GenSigSendType" SG_ 1730 SHVU_F_DiagReqData7 7;
BA_ "InvalidValue" SG_ 1730 SHVU_F_DiagReqData7 "null";
BA_ "GenSigSendType" SG_ 1731 SHVU_R_DiagReqData0 7;
BA_ "InvalidValue" SG_ 1731 SHVU_R_DiagReqData0 "null";
BA_ "GenSigSendType" SG_ 1731 SHVU_R_DiagReqData1 7;
BA_ "InvalidValue" SG_ 1731 SHVU_R_DiagReqData1 "null";
BA_ "GenSigSendType" SG_ 1731 SHVU_R_DiagReqData2 7;
BA_ "InvalidValue" SG_ 1731 SHVU_R_DiagReqData2 "null";
BA_ "GenSigSendType" SG_ 1731 SHVU_R_DiagReqData3 7;
BA_ "InvalidValue" SG_ 1731 SHVU_R_DiagReqData3 "null";
BA_ "GenSigSendType" SG_ 1731 SHVU_R_DiagReqData4 7;
BA_ "InvalidValue" SG_ 1731 SHVU_R_DiagReqData4 "null";
BA_ "GenSigSendType" SG_ 1731 SHVU_R_DiagReqData5 7;
BA_ "InvalidValue" SG_ 1731 SHVU_R_DiagReqData5 "null";
BA_ "GenSigSendType" SG_ 1731 SHVU_R_DiagReqData6 7;
BA_ "InvalidValue" SG_ 1731 SHVU_R_DiagReqData6 "null";
BA_ "GenSigSendType" SG_ 1731 SHVU_R_DiagReqData7 7;
BA_ "InvalidValue" SG_ 1731 SHVU_R_DiagReqData7 "null";
BA_ "GenSigSendType" SG_ 1732 OCS_P_DiagReqData0 7;
BA_ "InvalidValue" SG_ 1732 OCS_P_DiagReqData0 "null";
BA_ "GenSigSendType" SG_ 1732 OCS_P_DiagReqData1 7;
BA_ "InvalidValue" SG_ 1732 OCS_P_DiagReqData1 "null";
BA_ "GenSigSendType" SG_ 1732 OCS_P_DiagReqData2 7;
BA_ "InvalidValue" SG_ 1732 OCS_P_DiagReqData2 "null";
BA_ "GenSigSendType" SG_ 1732 OCS_P_DiagReqData3 7;
BA_ "InvalidValue" SG_ 1732 OCS_P_DiagReqData3 "null";
BA_ "GenSigSendType" SG_ 1732 OCS_P_DiagReqData4 7;
BA_ "InvalidValue" SG_ 1732 OCS_P_DiagReqData4 "null";
BA_ "GenSigSendType" SG_ 1732 OCS_P_DiagReqData5 7;
BA_ "InvalidValue" SG_ 1732 OCS_P_DiagReqData5 "null";
BA_ "GenSigSendType" SG_ 1732 OCS_P_DiagReqData6 7;
BA_ "InvalidValue" SG_ 1732 OCS_P_DiagReqData6 "null";
BA_ "GenSigSendType" SG_ 1732 OCS_P_DiagReqData7 7;
BA_ "InvalidValue" SG_ 1732 OCS_P_DiagReqData7 "null";
BA_ "GenSigSendType" SG_ 1737 LDM_L_DiagReqData0 7;
BA_ "InvalidValue" SG_ 1737 LDM_L_DiagReqData0 "null";
BA_ "GenSigSendType" SG_ 1737 LDM_L_DiagReqData1 7;
BA_ "InvalidValue" SG_ 1737 LDM_L_DiagReqData1 "null";
BA_ "GenSigSendType" SG_ 1737 LDM_L_DiagReqData2 7;
BA_ "InvalidValue" SG_ 1737 LDM_L_DiagReqData2 "null";
BA_ "GenSigSendType" SG_ 1737 LDM_L_DiagReqData3 7;
BA_ "InvalidValue" SG_ 1737 LDM_L_DiagReqData3 "null";
BA_ "GenSigSendType" SG_ 1737 LDM_L_DiagReqData4 7;
BA_ "InvalidValue" SG_ 1737 LDM_L_DiagReqData4 "null";
BA_ "GenSigSendType" SG_ 1737 LDM_L_DiagReqData5 7;
BA_ "InvalidValue" SG_ 1737 LDM_L_DiagReqData5 "null";
BA_ "GenSigSendType" SG_ 1737 LDM_L_DiagReqData6 7;
BA_ "InvalidValue" SG_ 1737 LDM_L_DiagReqData6 "null";
BA_ "GenSigSendType" SG_ 1737 LDM_L_DiagReqData7 7;
BA_ "InvalidValue" SG_ 1737 LDM_L_DiagReqData7 "null";
BA_ "GenSigSendType" SG_ 1738 LDM_R_DiagReqData0 7;
BA_ "InvalidValue" SG_ 1738 LDM_R_DiagReqData0 "null";
BA_ "GenSigSendType" SG_ 1738 LDM_R_DiagReqData1 7;
BA_ "InvalidValue" SG_ 1738 LDM_R_DiagReqData1 "null";
BA_ "GenSigSendType" SG_ 1738 LDM_R_DiagReqData2 7;
BA_ "InvalidValue" SG_ 1738 LDM_R_DiagReqData2 "null";
BA_ "GenSigSendType" SG_ 1738 LDM_R_DiagReqData3 7;
BA_ "InvalidValue" SG_ 1738 LDM_R_DiagReqData3 "null";
BA_ "GenSigSendType" SG_ 1738 LDM_R_DiagReqData4 7;
BA_ "InvalidValue" SG_ 1738 LDM_R_DiagReqData4 "null";
BA_ "GenSigSendType" SG_ 1738 LDM_R_DiagReqData5 7;
BA_ "InvalidValue" SG_ 1738 LDM_R_DiagReqData5 "null";
BA_ "GenSigSendType" SG_ 1738 LDM_R_DiagReqData6 7;
BA_ "InvalidValue" SG_ 1738 LDM_R_DiagReqData6 "null";
BA_ "GenSigSendType" SG_ 1738 LDM_R_DiagReqData7 7;
BA_ "InvalidValue" SG_ 1738 LDM_R_DiagReqData7 "null";
BA_ "GenSigSendType" SG_ 1752 BAS_DiagReqData0 7;
BA_ "InvalidValue" SG_ 1752 BAS_DiagReqData0 "null";
BA_ "GenSigSendType" SG_ 1752 BAS_DiagReqData1 7;
BA_ "InvalidValue" SG_ 1752 BAS_DiagReqData1 "null";
BA_ "GenSigSendType" SG_ 1752 BAS_DiagReqData2 7;
BA_ "InvalidValue" SG_ 1752 BAS_DiagReqData2 "null";
BA_ "GenSigSendType" SG_ 1752 BAS_DiagReqData3 7;
BA_ "InvalidValue" SG_ 1752 BAS_DiagReqData3 "null";
BA_ "GenSigSendType" SG_ 1752 BAS_DiagReqData4 7;
BA_ "InvalidValue" SG_ 1752 BAS_DiagReqData4 "null";
BA_ "GenSigSendType" SG_ 1752 BAS_DiagReqData5 7;
BA_ "InvalidValue" SG_ 1752 BAS_DiagReqData5 "null";
BA_ "GenSigSendType" SG_ 1752 BAS_DiagReqData6 7;
BA_ "InvalidValue" SG_ 1752 BAS_DiagReqData6 "null";
BA_ "GenSigSendType" SG_ 1752 BAS_DiagReqData7 7;
BA_ "InvalidValue" SG_ 1752 BAS_DiagReqData7 "null";
BA_ "GenSigSendType" SG_ 1764 DCM_APM_DiagReqData0 7;
BA_ "InvalidValue" SG_ 1764 DCM_APM_DiagReqData0 "null";
BA_ "GenSigSendType" SG_ 1764 DCM_APM_DiagReqData1 7;
BA_ "InvalidValue" SG_ 1764 DCM_APM_DiagReqData1 "null";
BA_ "GenSigSendType" SG_ 1764 DCM_APM_DiagReqData2 7;
BA_ "InvalidValue" SG_ 1764 DCM_APM_DiagReqData2 "null";
BA_ "GenSigSendType" SG_ 1764 DCM_APM_DiagReqData3 7;
BA_ "InvalidValue" SG_ 1764 DCM_APM_DiagReqData3 "null";
BA_ "GenSigSendType" SG_ 1764 DCM_APM_DiagReqData4 7;
BA_ "InvalidValue" SG_ 1764 DCM_APM_DiagReqData4 "null";
BA_ "GenSigSendType" SG_ 1764 DCM_APM_DiagReqData5 7;
BA_ "InvalidValue" SG_ 1764 DCM_APM_DiagReqData5 "null";
BA_ "GenSigSendType" SG_ 1764 DCM_APM_DiagReqData6 7;
BA_ "InvalidValue" SG_ 1764 DCM_APM_DiagReqData6 "null";
BA_ "GenSigSendType" SG_ 1764 DCM_APM_DiagReqData7 7;
BA_ "InvalidValue" SG_ 1764 DCM_APM_DiagReqData7 "null";
BA_ "GenSigSendType" SG_ 1775 DiagReqAllCANData0 7;
BA_ "InvalidValue" SG_ 1775 DiagReqAllCANData0 "null";
BA_ "GenSigSendType" SG_ 1775 DiagReqAllCANData1 7;
BA_ "InvalidValue" SG_ 1775 DiagReqAllCANData1 "null";
BA_ "GenSigSendType" SG_ 1775 DiagReqAllCANData2 7;
BA_ "InvalidValue" SG_ 1775 DiagReqAllCANData2 "null";
BA_ "GenSigSendType" SG_ 1775 DiagReqAllCANData3 7;
BA_ "InvalidValue" SG_ 1775 DiagReqAllCANData3 "null";
BA_ "GenSigSendType" SG_ 1775 DiagReqAllCANData4 7;
BA_ "InvalidValue" SG_ 1775 DiagReqAllCANData4 "null";
BA_ "GenSigSendType" SG_ 1775 DiagReqAllCANData5 7;
BA_ "InvalidValue" SG_ 1775 DiagReqAllCANData5 "null";
BA_ "GenSigSendType" SG_ 1775 DiagReqAllCANData6 7;
BA_ "InvalidValue" SG_ 1775 DiagReqAllCANData6 "null";
BA_ "GenSigSendType" SG_ 1775 DiagReqAllCANData7 7;
BA_ "InvalidValue" SG_ 1775 DiagReqAllCANData7 "null";
BA_ "GenSigSendType" SG_ 1777 ASU_DiagReqData0 7;
BA_ "GenSigSendType" SG_ 1777 ASU_DiagReqData1 7;
BA_ "GenSigSendType" SG_ 1777 ASU_DiagReqData2 7;
BA_ "GenSigSendType" SG_ 1777 ASU_DiagReqData3 7;
BA_ "GenSigSendType" SG_ 1777 ASU_DiagReqData4 7;
BA_ "GenSigSendType" SG_ 1777 ASU_DiagReqData5 7;
BA_ "GenSigSendType" SG_ 1777 ASU_DiagReqData6 7;
BA_ "GenSigSendType" SG_ 1777 ASU_DiagReqData7 7;
BA_ "GenSigSendType" SG_ 1787 BCM_BPM_DiagReqData0 7;
BA_ "InvalidValue" SG_ 1787 BCM_BPM_DiagReqData0 "null";
BA_ "GenSigSendType" SG_ 1787 BCM_BPM_DiagReqData1 7;
BA_ "InvalidValue" SG_ 1787 BCM_BPM_DiagReqData1 "null";
BA_ "GenSigSendType" SG_ 1787 BCM_BPM_DiagReqData2 7;
BA_ "InvalidValue" SG_ 1787 BCM_BPM_DiagReqData2 "null";
BA_ "GenSigSendType" SG_ 1787 BCM_BPM_DiagReqData3 7;
BA_ "InvalidValue" SG_ 1787 BCM_BPM_DiagReqData3 "null";
BA_ "GenSigSendType" SG_ 1787 BCM_BPM_DiagReqData4 7;
BA_ "InvalidValue" SG_ 1787 BCM_BPM_DiagReqData4 "null";
BA_ "GenSigSendType" SG_ 1787 BCM_BPM_DiagReqData5 7;
BA_ "InvalidValue" SG_ 1787 BCM_BPM_DiagReqData5 "null";
BA_ "GenSigSendType" SG_ 1787 BCM_BPM_DiagReqData6 7;
BA_ "InvalidValue" SG_ 1787 BCM_BPM_DiagReqData6 "null";
BA_ "GenSigSendType" SG_ 1787 BCM_BPM_DiagReqData7 7;
BA_ "InvalidValue" SG_ 1787 BCM_BPM_DiagReqData7 "null";
BA_ "GenSigSendType" SG_ 1791 DiagReqAllEcuData0 7;
BA_ "InvalidValue" SG_ 1791 DiagReqAllEcuData0 "null";
BA_ "GenSigSendType" SG_ 1791 DiagReqAllEcuData1 7;
BA_ "InvalidValue" SG_ 1791 DiagReqAllEcuData1 "null";
BA_ "GenSigSendType" SG_ 1791 DiagReqAllEcuData2 7;
BA_ "InvalidValue" SG_ 1791 DiagReqAllEcuData2 "null";
BA_ "GenSigSendType" SG_ 1791 DiagReqAllEcuData3 7;
BA_ "InvalidValue" SG_ 1791 DiagReqAllEcuData3 "null";
BA_ "GenSigSendType" SG_ 1791 DiagReqAllEcuData4 7;
BA_ "InvalidValue" SG_ 1791 DiagReqAllEcuData4 "null";
BA_ "GenSigSendType" SG_ 1791 DiagReqAllEcuData5 7;
BA_ "InvalidValue" SG_ 1791 DiagReqAllEcuData5 "null";
BA_ "GenSigSendType" SG_ 1791 DiagReqAllEcuData6 7;
BA_ "InvalidValue" SG_ 1791 DiagReqAllEcuData6 "null";
BA_ "GenSigSendType" SG_ 1791 DiagReqAllEcuData7 7;
BA_ "InvalidValue" SG_ 1791 DiagReqAllEcuData7 "null";
BA_ "GenSigSendType" SG_ 2033 Request_Airbag_Deployment 7;
BA_ "InvalidValue" SG_ 2033 Request_Airbag_Deployment "null";
BA_ "GenSigSendType" SG_ 2041 Response_Airbag_Deployment 7;
BA_ "InvalidValue" SG_ 2041 Response_Airbag_Deployment "null";
